VERSION "0.2"

NS_ :

BS_:

BU_: IFV_CWMP IFV_VFP External ExternalX

BO_ 259 ETSEL_common_1: 8 IFV_CWMP
 SG_ ETSEL_common_1_MessageCounter : 62|2@1+ (1,0) [0|3] ""  External
 SG_ Traffic_Direction : 47|2@1+ (1,0) [0|2] "enum"  External
 SG_ Predicted_Path_Lane_Width : 32|15@1+ (0.01,0) [0|5] "m"  External
 SG_ LROS_MVS_UpdatePulse : 16|16@1+ (1,0) [0|65535] ""  External
 SG_ LROS_FUS_UpdatePulse : 0|16@1+ (1,0) [0|65535] ""  External
 SG_ FiltVehicleSpeedOverGround : 49|13@1+ (0.01,0) [0|70] "m/s"  External

BO_ 1654 VIS_OBS_MSG_2: 8 IFV_CWMP
 SG_ VIS_OBS_CUT_IN_OUT_15 m15 : 33|3@1+ (1,0) [0|7] ""  External
 SG_ VIS_OBS_CUT_IN_OUT_14 m14 : 33|3@1+ (1,0) [0|7] ""  External
 SG_ VIS_OBS_CUT_IN_OUT_13 m13 : 33|3@1+ (1,0) [0|7] ""  External
 SG_ VIS_OBS_CUT_IN_OUT_12 m12 : 33|3@1+ (1,0) [0|7] ""  External
 SG_ VIS_OBS_CUT_IN_OUT_11 m11 : 33|3@1+ (1,0) [0|7] ""  External
 SG_ VIS_OBS_CUT_IN_OUT_10 m10 : 33|3@1+ (1,0) [0|7] ""  External
 SG_ VIS_OBS_CUT_IN_OUT_09 m9 : 33|3@1+ (1,0) [0|7] ""  External
 SG_ VIS_OBS_CUT_IN_OUT_08 m8 : 33|3@1+ (1,0) [0|7] ""  External
 SG_ VIS_OBS_CUT_IN_OUT_07 m7 : 33|3@1+ (1,0) [0|7] ""  External
 SG_ VIS_OBS_CUT_IN_OUT_06 m6 : 33|3@1+ (1,0) [0|7] ""  External
 SG_ VIS_OBS_CUT_IN_OUT_05 m5 : 33|3@1+ (1,0) [0|7] ""  External
 SG_ VIS_OBS_CUT_IN_OUT_04 m4 : 33|3@1+ (1,0) [0|7] ""  External
 SG_ VIS_OBS_CUT_IN_OUT_03 m3 : 33|3@1+ (1,0) [0|7] ""  External
 SG_ VIS_OBS_CUT_IN_OUT_02 m2 : 33|3@1+ (1,0) [0|7] ""  External
 SG_ VIS_OBS_CUT_IN_OUT_01 m1 : 33|3@1+ (1,0) [0|7] ""  External
 SG_ VIS_OBS_CIPO_15 m15 : 29|4@1+ (1,0) [0|15] ""  External
 SG_ VIS_OBS_CIPO_14 m14 : 29|4@1+ (1,0) [0|15] ""  External
 SG_ VIS_OBS_CIPO_13 m13 : 29|4@1+ (1,0) [0|15] ""  External
 SG_ VIS_OBS_CIPO_12 m12 : 29|4@1+ (1,0) [0|15] ""  External
 SG_ VIS_OBS_CIPO_11 m11 : 29|4@1+ (1,0) [0|15] ""  External
 SG_ VIS_OBS_CIPO_10 m10 : 29|4@1+ (1,0) [0|15] ""  External
 SG_ VIS_OBS_CIPO_09 m9 : 29|4@1+ (1,0) [0|15] ""  External
 SG_ VIS_OBS_CIPO_08 m8 : 29|4@1+ (1,0) [0|15] ""  External
 SG_ VIS_OBS_CIPO_07 m7 : 29|4@1+ (1,0) [0|15] ""  External
 SG_ VIS_OBS_CIPO_06 m6 : 29|4@1+ (1,0) [0|15] ""  External
 SG_ VIS_OBS_CIPO_05 m5 : 29|4@1+ (1,0) [0|15] ""  External
 SG_ VIS_OBS_CIPO_04 m4 : 29|4@1+ (1,0) [0|15] ""  External
 SG_ VIS_OBS_CIPO_03 m3 : 29|4@1+ (1,0) [0|15] ""  External
 SG_ VIS_OBS_CIPO_02 m2 : 29|4@1+ (1,0) [0|15] ""  External
 SG_ VIS_OBS_CIPO_01 m1 : 29|4@1+ (1,0) [0|15] ""  External
 SG_ VIS_OBS_TTC_CONST_ACC_MODEL_15 m15 : 19|10@1+ (0.01,0) [0|7] "s"  External
 SG_ VIS_OBS_TTC_CONST_ACC_MODEL_14 m14 : 19|10@1+ (0.01,0) [0|7] "s"  External
 SG_ VIS_OBS_TTC_CONST_ACC_MODEL_13 m13 : 19|10@1+ (0.01,0) [0|7] "s"  External
 SG_ VIS_OBS_TTC_CONST_ACC_MODEL_12 m12 : 19|10@1+ (0.01,0) [0|7] "s"  External
 SG_ VIS_OBS_TTC_CONST_ACC_MODEL_11 m11 : 19|10@1+ (0.01,0) [0|7] "s"  External
 SG_ VIS_OBS_TTC_CONST_ACC_MODEL_10 m10 : 19|10@1+ (0.01,0) [0|7] "s"  External
 SG_ VIS_OBS_TTC_CONST_ACC_MODEL_09 m9 : 19|10@1+ (0.01,0) [0|7] "s"  External
 SG_ VIS_OBS_TTC_CONST_ACC_MODEL_08 m8 : 19|10@1+ (0.01,0) [0|7] "s"  External
 SG_ VIS_OBS_TTC_CONST_ACC_MODEL_07 m7 : 19|10@1+ (0.01,0) [0|7] "s"  External
 SG_ VIS_OBS_TTC_CONST_ACC_MODEL_06 m6 : 19|10@1+ (0.01,0) [0|7] "s"  External
 SG_ VIS_OBS_TTC_CONST_ACC_MODEL_05 m5 : 19|10@1+ (0.01,0) [0|7] "s"  External
 SG_ VIS_OBS_TTC_CONST_ACC_MODEL_04 m4 : 19|10@1+ (0.01,0) [0|7] "s"  External
 SG_ VIS_OBS_TTC_CONST_ACC_MODEL_03 m3 : 19|10@1+ (0.01,0) [0|7] "s"  External
 SG_ VIS_OBS_TTC_CONST_ACC_MODEL_02 m2 : 19|10@1+ (0.01,0) [0|7] "s"  External
 SG_ VIS_OBS_TTC_CONST_ACC_MODEL_01 m1 : 19|10@1+ (0.01,0) [0|7] "s"  External
 SG_ VIS_OBS_LONG_ACCEL_15 m15 : 6|13@1+ (0.0078125,-20) [-20|20] "m/s^2"  External
 SG_ VIS_OBS_LONG_ACCEL_14 m14 : 6|13@1+ (0.0078125,-20) [-20|20] "m/s^2"  External
 SG_ VIS_OBS_LONG_ACCEL_13 m13 : 6|13@1+ (0.0078125,-20) [-20|20] "m/s^2"  External
 SG_ VIS_OBS_LONG_ACCEL_12 m12 : 6|13@1+ (0.0078125,-20) [-20|20] "m/s^2"  External
 SG_ VIS_OBS_LONG_ACCEL_11 m11 : 6|13@1+ (0.0078125,-20) [-20|20] "m/s^2"  External
 SG_ VIS_OBS_LONG_ACCEL_10 m10 : 6|13@1+ (0.0078125,-20) [-20|20] "m/s^2"  External
 SG_ VIS_OBS_LONG_ACCEL_09 m9 : 6|13@1+ (0.0078125,-20) [-20|20] "m/s^2"  External
 SG_ VIS_OBS_LONG_ACCEL_08 m8 : 6|13@1+ (0.0078125,-20) [-20|20] "m/s^2"  External
 SG_ VIS_OBS_LONG_ACCEL_07 m7 : 6|13@1+ (0.0078125,-20) [-20|20] "m/s^2"  External
 SG_ VIS_OBS_LONG_ACCEL_06 m6 : 6|13@1+ (0.0078125,-20) [-20|20] "m/s^2"  External
 SG_ VIS_OBS_LONG_ACCEL_05 m5 : 6|13@1+ (0.0078125,-20) [-20|20] "m/s^2"  External
 SG_ VIS_OBS_LONG_ACCEL_04 m4 : 6|13@1+ (0.0078125,-20) [-20|20] "m/s^2"  External
 SG_ VIS_OBS_LONG_ACCEL_03 m3 : 6|13@1+ (0.0078125,-20) [-20|20] "m/s^2"  External
 SG_ VIS_OBS_LONG_ACCEL_02 m2 : 6|13@1+ (0.0078125,-20) [-20|20] "m/s^2"  External
 SG_ VIS_OBS_LONG_ACCEL_01 m1 : 6|13@1+ (0.0078125,-20) [-20|20] "m/s^2"  External
 SG_ VIS_OBS_COUNT_MSG2 M : 2|4@1+ (1,0) [0|15] "obs"  External
 SG_ VIS_OBS_MESSAGE_COUNTER_MSG2 : 0|2@1+ (1,0) [0|3] ""  External

BO_ 1650 VFP_SYS_STATUS_MSG3: 8 IFV_CWMP
 SG_ VIS_FAILSAFE_PART_BLOCK : 36|2@1+ (1,0) [0|3] ""  External
 SG_ VIS_FAILSAFE_OUT_OF_FOCUS : 32|2@1+ (1,0) [0|3] ""  External
 SG_ VIS_FAILSAFE_OUT_OF_CALIBRATION : 34|2@1+ (1,0) [0|3] ""  External
 SG_ FUS_FAILSAFE_FUS_RAD_MISALIGNMNT : 28|2@1+ (1,0) [0|3] ""  External
 SG_ FUS_FAILSAFE_FUS_RAD_LOW_VIS : 30|2@1+ (1,0) [0|3] ""  External
 SG_ VIS_FAILSAFE_NIGHT_SPOT_RAYS : 24|2@1+ (1,0) [0|3] ""  External
 SG_ VIS_FAILSAFE_NIGHT_SMEARED_SPOTS : 26|2@1+ (1,0) [0|3] ""  External
 SG_ VIS_FAILSAFE_NIGHT_SELF_GLARE : 22|2@1+ (1,0) [0|3] ""  External
 SG_ VIS_FAILSAFE_SMEAR_IMAGE : 16|2@1+ (1,0) [0|3] ""  External
 SG_ VIS_FAILSAFE_NIGHT_FULL_BLOCK : 18|2@1+ (1,0) [0|3] ""  External
 SG_ VIS_FAILSAFE_NIGHT_FOGGY_SPOTS : 20|2@1+ (1,0) [0|3] ""  External
 SG_ VIS_FAILSAFE_NIGHT_BLUR : 14|2@1+ (1,0) [0|3] ""  External
 SG_ VIS_FAILSAFE_DAY_SUN_RAY : 12|2@1+ (1,0) [0|3] ""  External
 SG_ VIS_FAILSAFE_DAY_SPLASHES : 10|2@1+ (1,0) [0|3] ""  External
 SG_ VIS_FAILSAFE_DAY_LOW_SUN : 8|2@1+ (1,0) [0|3] ""  External
 SG_ CAN_DRIVING_SIDE : 7|1@1+ (1,0) [0|1] ""  External
 SG_ VIS_FAILSAFE_FLR_VIS_CORRELATION : 6|1@1+ (1,0) [0|1] ""  External
 SG_ VIS_FAULT_INVALID_SPEED_YAW : 5|1@1+ (1,0) [0|1] ""  External
 SG_ VIS_FAULT_IMAGER_RCC_MISALIGNED : 4|1@1+ (1,0) [0|1] ""  External
 SG_ VIS_FAILSAFE_PART_BLUR_IMAGE : 3|1@1+ (1,0) [0|1] ""  External
 SG_ VIS_FAILSAFE_PART_SOLID_BLOCKAGE : 2|1@1+ (1,0) [0|1] ""  External
 SG_ VIS_FAILSAFE_HEAVY_RAIN : 1|1@1+ (1,0) [0|1] ""  External
 SG_ VIS_FAILSAFE_ROLL_ANGLE : 0|1@1+ (1,0) [0|1] ""  External

BO_ 1710 VIS_LANE_TIMESTAMP: 8 IFV_CWMP
 SG_ VIS_LANE_TIMESTAMP : 0|32@1+ (1,0) [0|4294967295] "ms"  External

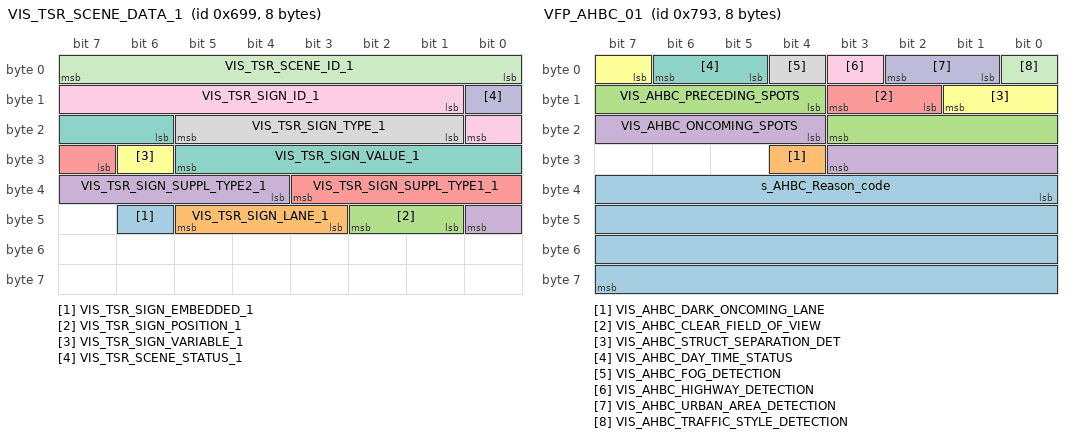
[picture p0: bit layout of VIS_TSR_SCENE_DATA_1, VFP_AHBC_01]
BO_ 1689 VIS_TSR_SCENE_DATA_1: 8 IFV_CWMP
 SG_ VIS_TSR_SIGN_EMBEDDED_1 : 46|1@1+ (1,0) [0|1] ""  External
 SG_ VIS_TSR_SIGN_LANE_1 : 43|3@1+ (1,0) [0|6] ""  External
 SG_ VIS_TSR_SIGN_POSITION_1 : 41|2@1+ (1,0) [0|2] ""  External
 SG_ VIS_TSR_SIGN_SUPPL_TYPE2_1 : 36|5@1+ (1,0) [0|24] ""  External
 SG_ VIS_TSR_SIGN_SUPPL_TYPE1_1 : 31|5@1+ (1,0) [0|24] ""  External
 SG_ VIS_TSR_SIGN_VARIABLE_1 : 30|1@1+ (1,0) [0|1] ""  External
 SG_ VIS_TSR_SIGN_VALUE_1 : 22|8@1+ (1,0) [0|255] ""  External
 SG_ VIS_TSR_SIGN_TYPE_1 : 17|5@1+ (1,0) [0|27] ""  External
 SG_ VIS_TSR_SIGN_ID_1 : 9|8@1+ (1,0) [0|255] ""  External
 SG_ VIS_TSR_SCENE_STATUS_1 : 8|1@1+ (1,0) [0|1] ""  External
 SG_ VIS_TSR_SCENE_ID_1 : 0|8@1+ (1,0) [0|255] ""  External

BO_ 1688 VIS_TSR_Environmental_Detection: 8 IFV_CWMP
 SG_ VIS_TSR_LANE_CHANGE : 6|2@1+ (1,0) [0|2] ""  External
 SG_ VIS_TSR_ROAD_CLASS : 3|3@1+ (1,0) [0|4] ""  External
 SG_ VIS_TSR_SPEED_UNIT : 1|2@1+ (1,0) [0|2] ""  External
 SG_ VIS_TSR_TRAFFIC_STYLE : 0|1@1+ (1,0) [0|1] ""  External

BO_ 1939 VFP_AHBC_01: 8 IFV_CWMP
 SG_ s_AHBC_Reason_code : 32|32@1+ (1,0) [0|4294967295] ""  External
 SG_ VIS_AHBC_DARK_ONCOMING_LANE : 28|1@1+ (1,0) [0|1] ""  External
 SG_ VIS_AHBC_PRECEDING_SPOTS : 12|8@1+ (1,0) [0|255] ""  External
 SG_ VIS_AHBC_ONCOMING_SPOTS : 20|8@1+ (1,0) [0|255] ""  External
 SG_ VIS_AHBC_CLEAR_FIELD_OF_VIEW : 10|2@1+ (1,0) [0|2] ""  External
 SG_ VIS_AHBC_STRUCT_SEPARATION_DET : 7|3@1+ (1,0) [0|4] ""  External
 SG_ VIS_AHBC_DAY_TIME_STATUS : 5|2@1+ (1,0) [0|3] ""  External
 SG_ VIS_AHBC_FOG_DETECTION : 4|1@1+ (1,0) [0|1] ""  External
 SG_ VIS_AHBC_HIGHWAY_DETECTION : 3|1@1+ (1,0) [0|1] ""  External
 SG_ VIS_AHBC_URBAN_AREA_DETECTION : 1|2@1+ (1,0) [0|2] ""  External
 SG_ VIS_AHBC_TRAFFIC_STYLE_DETECTION : 0|1@1+ (1,0) [0|1] ""  External

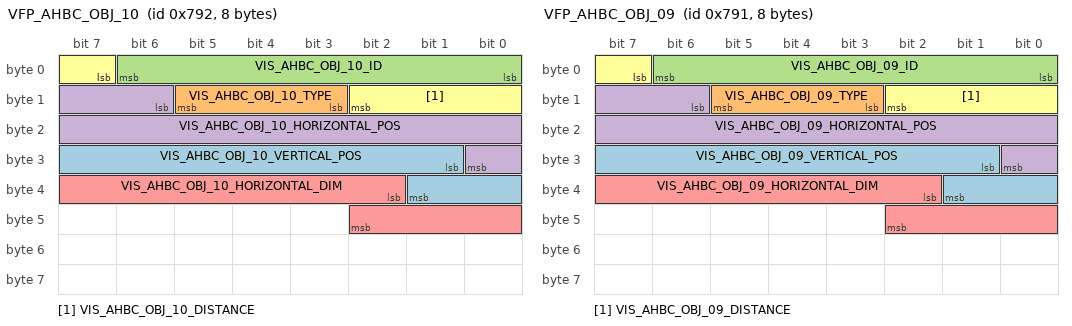
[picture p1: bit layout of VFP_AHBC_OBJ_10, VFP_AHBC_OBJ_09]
BO_ 1938 VFP_AHBC_OBJ_10: 8 IFV_CWMP
 SG_ VIS_AHBC_OBJ_10_VERTICAL_POS : 25|9@1+ (0.04,-5) [-5|5] "deg"  External
 SG_ VIS_AHBC_OBJ_10_TYPE : 11|3@1+ (1,0) [0|5] ""  External
 SG_ VIS_AHBC_OBJ_10_ID : 0|7@1+ (1,0) [0|127] ""  External
 SG_ VIS_AHBC_OBJ_10_HORIZONTAL_POS : 14|11@1+ (0.04,-24) [-24|24] "deg"  External
 SG_ VIS_AHBC_OBJ_10_HORIZONTAL_DIM : 34|9@1+ (0.04,0) [0|10] "deg"  External
 SG_ VIS_AHBC_OBJ_10_DISTANCE : 7|4@1+ (1,0) [0|15] ""  External

BO_ 1937 VFP_AHBC_OBJ_09: 8 IFV_CWMP
 SG_ VIS_AHBC_OBJ_09_VERTICAL_POS : 25|9@1+ (0.04,-5) [-5|5] "deg"  External
 SG_ VIS_AHBC_OBJ_09_TYPE : 11|3@1+ (1,0) [0|5] ""  External
 SG_ VIS_AHBC_OBJ_09_ID : 0|7@1+ (1,0) [0|127] ""  External
 SG_ VIS_AHBC_OBJ_09_HORIZONTAL_POS : 14|11@1+ (0.04,-24) [-24|24] "deg"  External
 SG_ VIS_AHBC_OBJ_09_HORIZONTAL_DIM : 34|9@1+ (0.04,0) [0|10] "deg"  External
 SG_ VIS_AHBC_OBJ_09_DISTANCE : 7|4@1+ (1,0) [0|15] ""  External

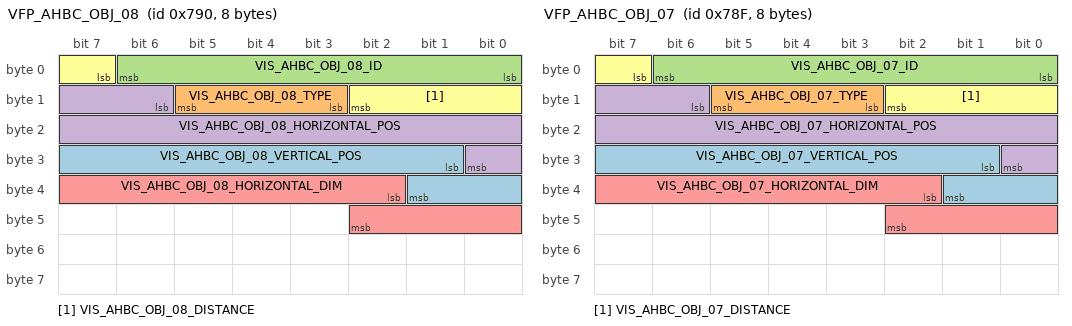
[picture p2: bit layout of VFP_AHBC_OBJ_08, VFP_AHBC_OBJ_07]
BO_ 1936 VFP_AHBC_OBJ_08: 8 IFV_CWMP
 SG_ VIS_AHBC_OBJ_08_VERTICAL_POS : 25|9@1+ (0.04,-5) [-5|5] "deg"  External
 SG_ VIS_AHBC_OBJ_08_TYPE : 11|3@1+ (1,0) [0|5] ""  External
 SG_ VIS_AHBC_OBJ_08_ID : 0|7@1+ (1,0) [0|127] ""  External
 SG_ VIS_AHBC_OBJ_08_HORIZONTAL_POS : 14|11@1+ (0.04,-24) [-24|24] "deg"  External
 SG_ VIS_AHBC_OBJ_08_HORIZONTAL_DIM : 34|9@1+ (0.04,0) [0|10] "deg"  External
 SG_ VIS_AHBC_OBJ_08_DISTANCE : 7|4@1+ (1,0) [0|15] ""  External

BO_ 1935 VFP_AHBC_OBJ_07: 8 IFV_CWMP
 SG_ VIS_AHBC_OBJ_07_VERTICAL_POS : 25|9@1+ (0.04,-5) [-5|5] "deg"  External
 SG_ VIS_AHBC_OBJ_07_TYPE : 11|3@1+ (1,0) [0|5] ""  External
 SG_ VIS_AHBC_OBJ_07_ID : 0|7@1+ (1,0) [0|127] ""  External
 SG_ VIS_AHBC_OBJ_07_HORIZONTAL_POS : 14|11@1+ (0.04,-24) [-24|24] "deg"  External
 SG_ VIS_AHBC_OBJ_07_HORIZONTAL_DIM : 34|9@1+ (0.04,0) [0|10] "deg"  External
 SG_ VIS_AHBC_OBJ_07_DISTANCE : 7|4@1+ (1,0) [0|15] ""  External

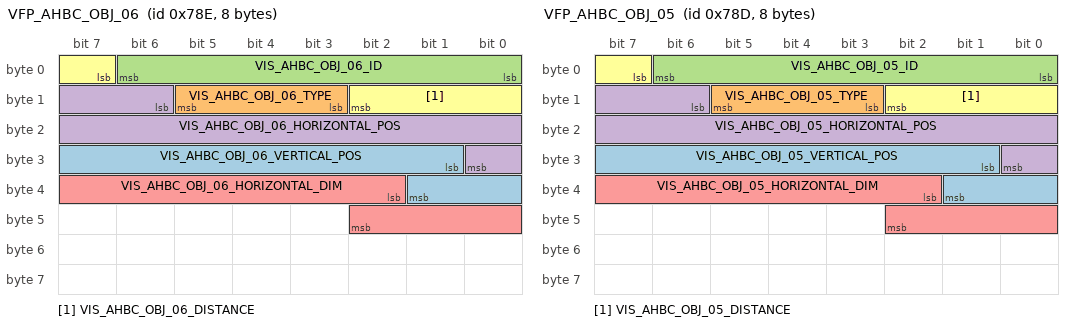
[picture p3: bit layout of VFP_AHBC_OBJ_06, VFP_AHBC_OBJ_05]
BO_ 1934 VFP_AHBC_OBJ_06: 8 IFV_CWMP
 SG_ VIS_AHBC_OBJ_06_VERTICAL_POS : 25|9@1+ (0.04,-5) [-5|5] "deg"  External
 SG_ VIS_AHBC_OBJ_06_TYPE : 11|3@1+ (1,0) [0|5] ""  External
 SG_ VIS_AHBC_OBJ_06_ID : 0|7@1+ (1,0) [0|127] ""  External
 SG_ VIS_AHBC_OBJ_06_HORIZONTAL_POS : 14|11@1+ (0.04,-24) [-24|24] "deg"  External
 SG_ VIS_AHBC_OBJ_06_HORIZONTAL_DIM : 34|9@1+ (0.04,0) [0|10] "deg"  External
 SG_ VIS_AHBC_OBJ_06_DISTANCE : 7|4@1+ (1,0) [0|15] ""  External

BO_ 1933 VFP_AHBC_OBJ_05: 8 IFV_CWMP
 SG_ VIS_AHBC_OBJ_05_VERTICAL_POS : 25|9@1+ (0.04,-5) [-5|5] "deg"  External
 SG_ VIS_AHBC_OBJ_05_TYPE : 11|3@1+ (1,0) [0|5] ""  External
 SG_ VIS_AHBC_OBJ_05_ID : 0|7@1+ (1,0) [0|127] ""  External
 SG_ VIS_AHBC_OBJ_05_HORIZONTAL_POS : 14|11@1+ (0.04,-24) [-24|24] "deg"  External
 SG_ VIS_AHBC_OBJ_05_HORIZONTAL_DIM : 34|9@1+ (0.04,0) [0|10] "deg"  External
 SG_ VIS_AHBC_OBJ_05_DISTANCE : 7|4@1+ (1,0) [0|15] ""  External

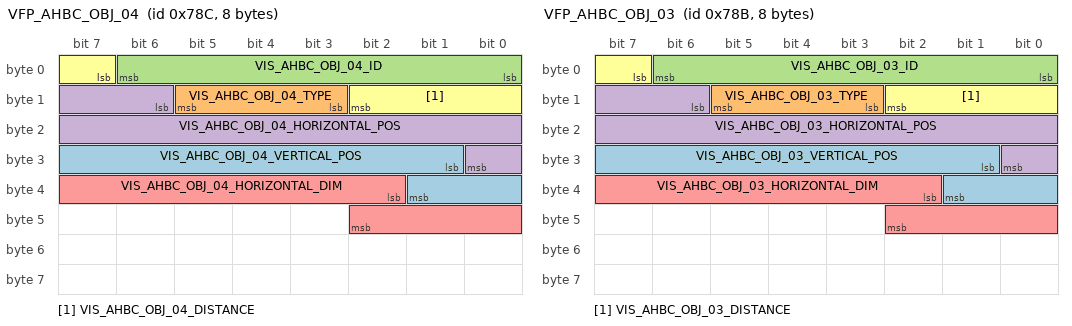
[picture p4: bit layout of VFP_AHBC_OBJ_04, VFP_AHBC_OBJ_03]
BO_ 1932 VFP_AHBC_OBJ_04: 8 IFV_CWMP
 SG_ VIS_AHBC_OBJ_04_VERTICAL_POS : 25|9@1+ (0.04,-5) [-5|5] "deg"  External
 SG_ VIS_AHBC_OBJ_04_TYPE : 11|3@1+ (1,0) [0|5] ""  External
 SG_ VIS_AHBC_OBJ_04_ID : 0|7@1+ (1,0) [0|127] ""  External
 SG_ VIS_AHBC_OBJ_04_HORIZONTAL_POS : 14|11@1+ (0.04,-24) [-24|24] "deg"  External
 SG_ VIS_AHBC_OBJ_04_HORIZONTAL_DIM : 34|9@1+ (0.04,0) [0|10] "deg"  External
 SG_ VIS_AHBC_OBJ_04_DISTANCE : 7|4@1+ (1,0) [0|15] ""  External

BO_ 1931 VFP_AHBC_OBJ_03: 8 IFV_CWMP
 SG_ VIS_AHBC_OBJ_03_VERTICAL_POS : 25|9@1+ (0.04,-5) [-5|5] "deg"  External
 SG_ VIS_AHBC_OBJ_03_TYPE : 11|3@1+ (1,0) [0|5] ""  External
 SG_ VIS_AHBC_OBJ_03_ID : 0|7@1+ (1,0) [0|127] ""  External
 SG_ VIS_AHBC_OBJ_03_HORIZONTAL_POS : 14|11@1+ (0.04,-24) [-24|24] "deg"  External
 SG_ VIS_AHBC_OBJ_03_HORIZONTAL_DIM : 34|9@1+ (0.04,0) [0|10] "deg"  External
 SG_ VIS_AHBC_OBJ_03_DISTANCE : 7|4@1+ (1,0) [0|15] ""  External

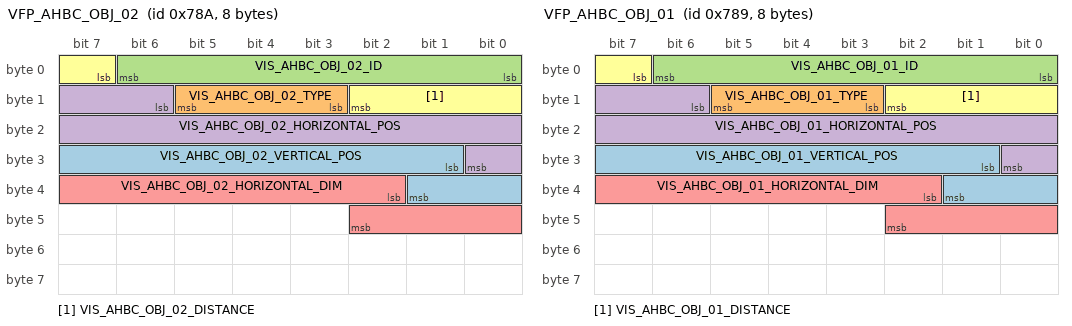
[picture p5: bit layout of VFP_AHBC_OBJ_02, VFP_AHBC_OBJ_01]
BO_ 1930 VFP_AHBC_OBJ_02: 8 IFV_CWMP
 SG_ VIS_AHBC_OBJ_02_VERTICAL_POS : 25|9@1+ (0.04,-5) [-5|5] "deg"  External
 SG_ VIS_AHBC_OBJ_02_TYPE : 11|3@1+ (1,0) [0|5] ""  External
 SG_ VIS_AHBC_OBJ_02_ID : 0|7@1+ (1,0) [0|127] ""  External
 SG_ VIS_AHBC_OBJ_02_HORIZONTAL_POS : 14|11@1+ (0.04,-24) [-24|24] "deg"  External
 SG_ VIS_AHBC_OBJ_02_HORIZONTAL_DIM : 34|9@1+ (0.04,0) [0|10] "deg"  External
 SG_ VIS_AHBC_OBJ_02_DISTANCE : 7|4@1+ (1,0) [0|15] ""  External

BO_ 1929 VFP_AHBC_OBJ_01: 8 IFV_CWMP
 SG_ VIS_AHBC_OBJ_01_VERTICAL_POS : 25|9@1+ (0.04,-5) [-5|5] "deg"  External
 SG_ VIS_AHBC_OBJ_01_TYPE : 11|3@1+ (1,0) [0|5] ""  External
 SG_ VIS_AHBC_OBJ_01_ID : 0|7@1+ (1,0) [0|127] ""  External
 SG_ VIS_AHBC_OBJ_01_HORIZONTAL_POS : 14|11@1+ (0.04,-24) [-24|24] "deg"  External
 SG_ VIS_AHBC_OBJ_01_HORIZONTAL_DIM : 34|9@1+ (0.04,0) [0|10] "deg"  External
 SG_ VIS_AHBC_OBJ_01_DISTANCE : 7|4@1+ (1,0) [0|15] ""  External

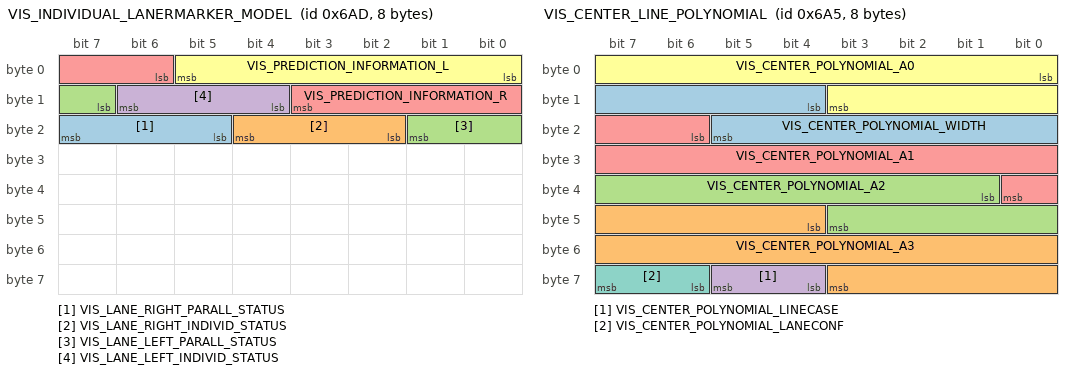
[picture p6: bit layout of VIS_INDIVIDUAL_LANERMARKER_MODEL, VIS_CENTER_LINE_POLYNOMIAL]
BO_ 1709 VIS_INDIVIDUAL_LANERMARKER_MODEL: 8 IFV_CWMP
 SG_ VIS_LANE_RIGHT_PARALL_STATUS : 21|3@1+ (1,0) [0|7] ""  External
 SG_ VIS_LANE_RIGHT_INDIVID_STATUS : 18|3@1+ (1,0) [0|7] ""  External
 SG_ VIS_LANE_LEFT_PARALL_STATUS : 15|3@1+ (1,0) [0|7] ""  External
 SG_ VIS_LANE_LEFT_INDIVID_STATUS : 12|3@1+ (1,0) [0|7] ""  External
 SG_ VIS_PREDICTION_INFORMATION_R : 6|6@1+ (1,0) [0|63] ""  External
 SG_ VIS_PREDICTION_INFORMATION_L : 0|6@1+ (1,0) [0|63] ""  External

BO_ 1701 VIS_CENTER_LINE_POLYNOMIAL: 8 IFV_CWMP
 SG_ VIS_CENTER_POLYNOMIAL_WIDTH : 12|10@1+ (0.01,0) [0|10] "m"  External
 SG_ VIS_CENTER_POLYNOMIAL_A3 : 44|16@1+ (1E-008,-0.00017) [-0.00017|0.000167] "1/m^2"  External
 SG_ VIS_CENTER_POLYNOMIAL_A2 : 33|11@1+ (1E-005,-0.01) [-0.01|0.01] "1/m"  External
 SG_ VIS_CENTER_POLYNOMIAL_LINECASE : 60|2@1+ (1,0) [0|3] ""  External
 SG_ VIS_CENTER_POLYNOMIAL_A1 : 22|11@1+ (0.0009,-0.9) [-0.9|0.9] "rad"  External
 SG_ VIS_CENTER_POLYNOMIAL_A0 : 0|12@1+ (0.01,-16) [-16|15.99] "m"  External
 SG_ VIS_CENTER_POLYNOMIAL_LANECONF : 62|2@1+ (1,0) [0|2] ""  External

BO_ 1655 VIS_OBS_MSG_3: 8 IFV_CWMP
 SG_ VIS_OBS_WIDTH_15 m15 : 6|7@1+ (0.1,0) [0|6] "m"  External
 SG_ VIS_OBS_WIDTH_14 m14 : 6|7@1+ (0.1,0) [0|6] "m"  External
 SG_ VIS_OBS_WIDTH_13 m13 : 6|7@1+ (0.1,0) [0|6] "m"  External
 SG_ VIS_OBS_WIDTH_12 m12 : 6|7@1+ (0.1,0) [0|6] "m"  External
 SG_ VIS_OBS_WIDTH_11 m11 : 6|7@1+ (0.1,0) [0|6] "m"  External
 SG_ VIS_OBS_WIDTH_10 m10 : 6|7@1+ (0.1,0) [0|6] "m"  External
 SG_ VIS_OBS_WIDTH_09 m9 : 6|7@1+ (0.1,0) [0|6] "m"  External
 SG_ VIS_OBS_WIDTH_08 m8 : 6|7@1+ (0.1,0) [0|6] "m"  External
 SG_ VIS_OBS_WIDTH_07 m7 : 6|7@1+ (0.1,0) [0|6] "m"  External
 SG_ VIS_OBS_WIDTH_06 m6 : 6|7@1+ (0.1,0) [0|12.7] "m"  External
 SG_ VIS_OBS_WIDTH_05 m5 : 6|7@1+ (0.1,0) [0|6] "m"  External
 SG_ VIS_OBS_WIDTH_04 m4 : 6|7@1+ (0.1,0) [0|6] "m"  External
 SG_ VIS_OBS_WIDTH_03 m3 : 6|7@1+ (0.1,0) [0|6] "m"  External
 SG_ VIS_OBS_WIDTH_02 m2 : 6|7@1+ (0.1,0) [0|6] "m"  External
 SG_ VIS_OBS_LONG_VEL_15 m15 : 26|12@1+ (0.0625,-128) [-128|127.9375] "m/s"  External
 SG_ VIS_OBS_LONG_VEL_14 m14 : 26|12@1+ (0.0625,-128) [-128|127.9375] "m/s"  External
 SG_ VIS_OBS_LONG_VEL_13 m13 : 26|12@1+ (0.0625,-128) [-128|127.9375] "m/s"  External
 SG_ VIS_OBS_LONG_VEL_12 m12 : 26|12@1+ (0.0625,-128) [-128|127.9375] "m/s"  External
 SG_ VIS_OBS_LONG_VEL_11 m11 : 26|12@1+ (0.0625,-128) [-128|127.9375] "m/s"  External
 SG_ VIS_OBS_LONG_VEL_10 m10 : 26|12@1+ (0.0625,-128) [-128|127.9375] "m/s"  External
 SG_ VIS_OBS_LONG_VEL_09 m9 : 26|12@1+ (0.0625,-128) [-128|127.9375] "m/s"  External
 SG_ VIS_OBS_LONG_VEL_08 m8 : 26|12@1+ (0.0625,-128) [-128|127.9375] "m/s"  External
 SG_ VIS_OBS_LONG_VEL_07 m7 : 26|12@1+ (0.0625,-128) [-128|127.9375] "m/s"  External
 SG_ VIS_OBS_LONG_VEL_06 m6 : 26|12@1+ (0.0625,-128) [-128|127.9375] "m/s"  External
 SG_ VIS_OBS_LONG_VEL_05 m5 : 26|12@1+ (0.0625,-128) [-128|127.9375] "m/s"  External
 SG_ VIS_OBS_LONG_VEL_04 m4 : 26|12@1+ (0.0625,-128) [-128|127.9375] "m/s"  External
 SG_ VIS_OBS_LONG_VEL_03 m3 : 26|12@1+ (0.0625,-128) [-128|127.9375] "m/s"  External
 SG_ VIS_OBS_LONG_VEL_02 m2 : 26|12@1+ (0.0625,-128) [-128|127.9375] "m/s"  External
 SG_ VIS_OBS_LONG_POS_15 m15 : 13|13@1+ (0.03125,0) [0|255] "m"  External
 SG_ VIS_OBS_LONG_POS_14 m14 : 13|13@1+ (0.03125,0) [0|255] "m"  External
 SG_ VIS_OBS_LONG_POS_13 m13 : 13|13@1+ (0.03125,0) [0|255] "m"  External
 SG_ VIS_OBS_LONG_POS_12 m12 : 13|13@1+ (0.03125,0) [0|255] "m"  External
 SG_ VIS_OBS_LONG_POS_11 m11 : 13|13@1+ (0.03125,0) [0|255] "m"  External
 SG_ VIS_OBS_LONG_POS_10 m10 : 13|13@1+ (0.03125,0) [0|255] "m"  External
 SG_ VIS_OBS_LONG_POS_09 m9 : 13|13@1+ (0.03125,0) [0|255] "m"  External
 SG_ VIS_OBS_LONG_POS_08 m8 : 13|13@1+ (0.03125,0) [0|255] "m"  External
 SG_ VIS_OBS_LONG_POS_07 m7 : 13|13@1+ (0.03125,0) [0|255] "m"  External
 SG_ VIS_OBS_LONG_POS_06 m6 : 13|13@1+ (0.03125,0) [0|255] "m"  External
 SG_ VIS_OBS_LONG_POS_05 m5 : 13|13@1+ (0.03125,0) [0|255] "m"  External
 SG_ VIS_OBS_LONG_POS_04 m4 : 13|13@1+ (0.03125,0) [0|255] "m"  External
 SG_ VIS_OBS_LONG_POS_03 m3 : 13|13@1+ (0.03125,0) [0|255] "m"  External
 SG_ VIS_OBS_LONG_POS_02 m2 : 13|13@1+ (0.03125,0) [0|255] "m"  External
 SG_ VIS_OBS_LAT_VEL_15 m15 : 50|12@1+ (0.0625,-128) [-128|127.9375] "m/s"  External
 SG_ VIS_OBS_LAT_VEL_14 m14 : 50|12@1+ (0.0625,-128) [-128|127.9375] "m/s"  External
 SG_ VIS_OBS_LAT_VEL_13 m13 : 50|12@1+ (0.0625,-128) [-128|127.9375] "m/s"  External
 SG_ VIS_OBS_LAT_VEL_12 m12 : 50|12@1+ (0.0625,-128) [-128|127.9375] "m/s"  External
 SG_ VIS_OBS_LAT_VEL_11 m11 : 50|12@1+ (0.0625,-128) [-128|127.9375] "m/s"  External
 SG_ VIS_OBS_LAT_VEL_10 m10 : 50|12@1+ (0.0625,-128) [-128|127.9375] "m/s"  External
 SG_ VIS_OBS_LAT_VEL_09 m9 : 50|12@1+ (0.0625,-128) [-128|127.9375] "m/s"  External
 SG_ VIS_OBS_LAT_VEL_08 m8 : 50|12@1+ (0.0625,-128) [-128|127.9375] "m/s"  External
 SG_ VIS_OBS_LAT_VEL_07 m7 : 50|12@1+ (0.0625,-128) [-128|127.9375] "m/s"  External
 SG_ VIS_OBS_LAT_VEL_06 m6 : 50|12@1+ (0.0625,-128) [-128|127.9375] "m/s"  External
 SG_ VIS_OBS_LAT_VEL_05 m5 : 50|12@1+ (0.0625,-128) [-128|127.9375] "m/s"  External
 SG_ VIS_OBS_LAT_VEL_04 m4 : 50|12@1+ (0.0625,-128) [-128|127.9375] "m/s"  External
 SG_ VIS_OBS_LAT_VEL_03 m3 : 50|12@1+ (0.0625,-128) [-128|127.9375] "m/s"  External
 SG_ VIS_OBS_LAT_VEL_02 m2 : 50|12@1+ (0.0625,-128) [-128|127.9375] "m/s"  External
 SG_ VIS_OBS_LAT_POS_15 m15 : 38|12@1+ (0.0625,-128) [-128|127.9375] "m"  External
 SG_ VIS_OBS_LAT_POS_14 m14 : 38|12@1+ (0.0625,-128) [-128|127.9375] "m"  External
 SG_ VIS_OBS_LAT_POS_13 m13 : 38|12@1+ (0.0625,-128) [-128|127.9375] "m"  External
 SG_ VIS_OBS_LAT_POS_12 m12 : 38|12@1+ (0.0625,-128) [-128|127.9375] "m"  External
 SG_ VIS_OBS_LAT_POS_11 m11 : 38|12@1+ (0.0625,-128) [-128|127.9375] "m"  External
 SG_ VIS_OBS_LAT_POS_10 m10 : 38|12@1+ (0.0625,-128) [-128|127.9375] "m"  External
 SG_ VIS_OBS_LAT_POS_09 m9 : 38|12@1+ (0.0625,-128) [-128|127.9375] "m"  External
 SG_ VIS_OBS_LAT_POS_08 m8 : 38|12@1+ (0.0625,-128) [-128|127.9375] "m"  External
 SG_ VIS_OBS_LAT_POS_07 m7 : 38|12@1+ (0.0625,-128) [-128|127.9375] "m"  External
 SG_ VIS_OBS_LAT_POS_06 m6 : 38|12@1+ (0.0625,-128) [-128|127.9375] "m"  External
 SG_ VIS_OBS_LAT_POS_05 m5 : 38|12@1+ (0.0625,-128) [-128|127.9375] "m"  External
 SG_ VIS_OBS_LAT_POS_04 m4 : 38|12@1+ (0.0625,-128) [-128|127.9375] "m"  External
 SG_ VIS_OBS_LAT_POS_03 m3 : 38|12@1+ (0.0625,-128) [-128|127.9375] "m"  External
 SG_ VIS_OBS_LAT_POS_02 m2 : 38|12@1+ (0.0625,-128) [-128|127.9375] "m"  External
 SG_ VIS_OBS_WIDTH_01 m1 : 6|7@1+ (0.1,0) [0|6] "m"  External
 SG_ VIS_OBS_MESSAGE_COUNTER_MSG3 : 0|2@1+ (1,0) [0|3] ""  External
 SG_ VIS_OBS_LONG_VEL_01 m1 : 26|12@1+ (0.0625,-128) [-128|127.9375] "m/s"  External
 SG_ VIS_OBS_LONG_POS_01 m1 : 13|13@1+ (0.03125,0) [0|255] "m"  External
 SG_ VIS_OBS_LAT_VEL_01 m1 : 50|12@1+ (0.0625,-128) [-128|127.9375] "m/s"  External
 SG_ VIS_OBS_LAT_POS_01 m1 : 38|12@1+ (0.0625,-128) [-128|127.9375] "m"  External
 SG_ VIS_OBS_COUNT_MSG3 M : 2|4@1+ (1,0) [0|15] "obs"  External

BO_ 1653 VIS_OBS_MSG_1: 8 IFV_CWMP
 SG_ VIS_OBS_TURN_INDICATOR_15 m15 : 22|2@1+ (1,0) [0|3] ""  External
 SG_ VIS_OBS_TURN_INDICATOR_14 m14 : 22|2@1+ (1,0) [0|3] ""  External
 SG_ VIS_OBS_TURN_INDICATOR_13 m13 : 22|2@1+ (1,0) [0|3] ""  External
 SG_ VIS_OBS_TURN_INDICATOR_12 m12 : 22|2@1+ (1,0) [0|3] ""  External
 SG_ VIS_OBS_TURN_INDICATOR_11 m11 : 22|2@1+ (1,0) [0|3] ""  External
 SG_ VIS_OBS_TURN_INDICATOR_10 m10 : 22|2@1+ (1,0) [0|3] ""  External
 SG_ VIS_OBS_TURN_INDICATOR_09 m9 : 22|2@1+ (1,0) [0|3] ""  External
 SG_ VIS_OBS_TURN_INDICATOR_08 m8 : 22|2@1+ (1,0) [0|3] ""  External
 SG_ VIS_OBS_TURN_INDICATOR_07 m7 : 22|2@1+ (1,0) [0|3] ""  External
 SG_ VIS_OBS_TURN_INDICATOR_06 m6 : 22|2@1+ (1,0) [0|3] ""  External
 SG_ VIS_OBS_TURN_INDICATOR_05 m5 : 22|2@1+ (1,0) [0|3] ""  External
 SG_ VIS_OBS_TURN_INDICATOR_04 m4 : 22|2@1+ (1,0) [0|3] ""  External
 SG_ VIS_OBS_TURN_INDICATOR_03 m3 : 22|2@1+ (1,0) [0|3] ""  External
 SG_ VIS_OBS_TURN_INDICATOR_02 m2 : 22|2@1+ (1,0) [0|3] ""  External
 SG_ VIS_OBS_PED_WAIST_UP_15 m15 : 19|1@1+ (1,0) [0|1] ""  External
 SG_ VIS_OBS_PED_WAIST_UP_14 m14 : 19|1@1+ (1,0) [0|1] ""  External
 SG_ VIS_OBS_PED_WAIST_UP_13 m13 : 19|1@1+ (1,0) [0|1] ""  External
 SG_ VIS_OBS_PED_WAIST_UP_12 m12 : 19|1@1+ (1,0) [0|1] ""  External
 SG_ VIS_OBS_PED_WAIST_UP_11 m11 : 19|1@1+ (1,0) [0|1] ""  External
 SG_ VIS_OBS_PED_WAIST_UP_10 m10 : 19|1@1+ (1,0) [0|1] ""  External
 SG_ VIS_OBS_PED_WAIST_UP_09 m9 : 19|1@1+ (1,0) [0|1] ""  External
 SG_ VIS_OBS_PED_WAIST_UP_08 m8 : 19|1@1+ (1,0) [0|1] ""  External
 SG_ VIS_OBS_PED_WAIST_UP_07 m7 : 19|1@1+ (1,0) [0|1] ""  External
 SG_ VIS_OBS_PED_WAIST_UP_06 m6 : 19|1@1+ (1,0) [0|1] ""  External
 SG_ VIS_OBS_PED_WAIST_UP_05 m5 : 19|1@1+ (1,0) [0|1] ""  External
 SG_ VIS_OBS_PED_WAIST_UP_04 m4 : 19|1@1+ (1,0) [0|1] ""  External
 SG_ VIS_OBS_PED_WAIST_UP_03 m3 : 19|1@1+ (1,0) [0|1] ""  External
 SG_ VIS_OBS_PED_WAIST_UP_02 m2 : 19|1@1+ (1,0) [0|1] ""  External
 SG_ VIS_OBS_ID_15 m15 : 8|4@1+ (1,0) [0|15] ""  External
 SG_ VIS_OBS_ID_14 m14 : 8|4@1+ (1,0) [0|15] ""  External
 SG_ VIS_OBS_ID_13 m13 : 8|4@1+ (1,0) [0|15] ""  External
 SG_ VIS_OBS_ID_12 m12 : 8|4@1+ (1,0) [0|15] ""  External
 SG_ VIS_OBS_ID_11 m11 : 8|4@1+ (1,0) [0|15] ""  External
 SG_ VIS_OBS_ID_10 m10 : 8|4@1+ (1,0) [0|15] ""  External
 SG_ VIS_OBS_ID_09 m9 : 8|4@1+ (1,0) [0|15] ""  External
 SG_ VIS_OBS_ID_08 m8 : 8|4@1+ (1,0) [0|15] ""  External
 SG_ VIS_OBS_ID_07 m7 : 8|4@1+ (1,0) [0|15] ""  External
 SG_ VIS_OBS_ID_06 m6 : 8|4@1+ (1,0) [0|15] ""  External
 SG_ VIS_OBS_ID_05 m5 : 8|4@1+ (1,0) [0|15] ""  External
 SG_ VIS_OBS_ID_04 m4 : 8|4@1+ (1,0) [0|15] ""  External
 SG_ VIS_OBS_ID_03 m3 : 8|4@1+ (1,0) [0|15] ""  External
 SG_ VIS_OBS_ID_02 m2 : 8|4@1+ (1,0) [0|15] ""  External
 SG_ VIS_OBS_HEIGHT_15 m15 : 58|5@1+ (0.1,0) [0|3] "m"  External
 SG_ VIS_OBS_HEIGHT_14 m14 : 58|5@1+ (0.1,0) [0|3] "m"  External
 SG_ VIS_OBS_HEIGHT_13 m13 : 58|5@1+ (0.1,0) [0|3] "m"  External
 SG_ VIS_OBS_HEIGHT_12 m12 : 58|5@1+ (0.1,0) [0|3] "m"  External
 SG_ VIS_OBS_HEIGHT_11 m11 : 58|5@1+ (0.1,0) [0|3] "m"  External
 SG_ VIS_OBS_HEIGHT_10 m10 : 58|5@1+ (0.1,0) [0|3] "m"  External
 SG_ VIS_OBS_HEIGHT_09 m9 : 58|5@1+ (0.1,0) [0|3] "m"  External
 SG_ VIS_OBS_HEIGHT_08 m8 : 58|5@1+ (0.1,0) [0|3] "m"  External
 SG_ VIS_OBS_HEIGHT_07 m7 : 58|5@1+ (0.1,0) [0|3] "m"  External
 SG_ VIS_OBS_HEIGHT_06 m6 : 58|5@1+ (0.1,0) [0|3] "m"  External
 SG_ VIS_OBS_HEIGHT_05 m5 : 58|5@1+ (0.1,0) [0|3] "m"  External
 SG_ VIS_OBS_HEIGHT_04 m4 : 58|5@1+ (0.1,0) [0|3] "m"  External
 SG_ VIS_OBS_HEIGHT_03 m3 : 58|5@1+ (0.1,0) [0|3] "m"  External
 SG_ VIS_OBS_HEIGHT_02 m2 : 58|5@1+ (0.1,0) [0|3] "m"  External
 SG_ VIS_OBS_CLASSIFICATION_15 m15 : 12|4@1+ (1,0) [0|10] ""  External
 SG_ VIS_OBS_CLASSIFICATION_14 m14 : 12|4@1+ (1,0) [0|10] ""  External
 SG_ VIS_OBS_CLASSIFICATION_13 m13 : 12|4@1+ (1,0) [0|10] ""  External
 SG_ VIS_OBS_CLASSIFICATION_12 m12 : 12|4@1+ (1,0) [0|10] ""  External
 SG_ VIS_OBS_CLASSIFICATION_11 m11 : 12|4@1+ (1,0) [0|10] ""  External
 SG_ VIS_OBS_CLASSIFICATION_10 m10 : 12|4@1+ (1,0) [0|10] ""  External
 SG_ VIS_OBS_CLASSIFICATION_09 m9 : 12|4@1+ (1,0) [0|10] ""  External
 SG_ VIS_OBS_CLASSIFICATION_08 m8 : 12|4@1+ (1,0) [0|10] ""  External
 SG_ VIS_OBS_CLASSIFICATION_07 m7 : 12|4@1+ (1,0) [0|10] ""  External
 SG_ VIS_OBS_CLASSIFICATION_06 m6 : 12|4@1+ (1,0) [0|10] ""  External
 SG_ VIS_OBS_CLASSIFICATION_05 m5 : 12|4@1+ (1,0) [0|10] ""  External
 SG_ VIS_OBS_CLASSIFICATION_04 m4 : 12|4@1+ (1,0) [0|10] ""  External
 SG_ VIS_OBS_CLASSIFICATION_03 m3 : 12|4@1+ (1,0) [0|10] ""  External
 SG_ VIS_OBS_CLASSIFICATION_02 m2 : 12|4@1+ (1,0) [0|10] ""  External
 SG_ VIS_OBS_BRAKE_LIGHT_INDIC_15 m15 : 20|2@1+ (1,0) [0|2] ""  External
 SG_ VIS_OBS_BRAKE_LIGHT_INDIC_14 m14 : 20|2@1+ (1,0) [0|2] ""  External
 SG_ VIS_OBS_BRAKE_LIGHT_INDIC_13 m13 : 20|2@1+ (1,0) [0|2] ""  External
 SG_ VIS_OBS_BRAKE_LIGHT_INDIC_12 m12 : 20|2@1+ (1,0) [0|2] ""  External
 SG_ VIS_OBS_BRAKE_LIGHT_INDIC_11 m11 : 20|2@1+ (1,0) [0|2] ""  External
 SG_ VIS_OBS_BRAKE_LIGHT_INDIC_10 m10 : 20|2@1+ (1,0) [0|2] ""  External
 SG_ VIS_OBS_BRAKE_LIGHT_INDIC_09 m9 : 20|2@1+ (1,0) [0|2] ""  External
 SG_ VIS_OBS_BRAKE_LIGHT_INDIC_08 m8 : 20|2@1+ (1,0) [0|2] ""  External
 SG_ VIS_OBS_BRAKE_LIGHT_INDIC_07 m7 : 20|2@1+ (1,0) [0|2] ""  External
 SG_ VIS_OBS_BRAKE_LIGHT_INDIC_06 m6 : 20|2@1+ (1,0) [0|2] ""  External
 SG_ VIS_OBS_BRAKE_LIGHT_INDIC_05 m5 : 20|2@1+ (1,0) [0|2] ""  External
 SG_ VIS_OBS_BRAKE_LIGHT_INDIC_04 m4 : 20|2@1+ (1,0) [0|2] ""  External
 SG_ VIS_OBS_BRAKE_LIGHT_INDIC_03 m3 : 20|2@1+ (1,0) [0|2] ""  External
 SG_ VIS_OBS_BRAKE_LIGHT_INDIC_02 m2 : 20|2@1+ (1,0) [0|2] ""  External
 SG_ VIS_OBS_TURN_INDICATOR_01 m1 : 22|2@1+ (1,0) [0|3] ""  External
 SG_ VIS_OBS_PED_WAIST_UP_01 m1 : 19|1@1+ (1,0) [0|1] ""  External
 SG_ VIS_OBS_MESSAGE_COUNTER_MSG1 : 56|2@1+ (1,0) [0|3] ""  External
 SG_ VIS_OBS_ID_01 m1 : 8|4@1+ (1,0) [0|15] ""  External
 SG_ VIS_OBS_HEIGHT_01 m1 : 58|5@1+ (0.1,0) [0|3] "m"  External
 SG_ VIS_OBS_COUNT_MSG1 M : 4|4@1+ (1,0) [0|15] "obs"  External
 SG_ VIS_OBS_CLASSIFICATION_01 m1 : 12|4@1+ (1,0) [0|10] ""  External
 SG_ VIS_OBS_BRAKE_LIGHT_INDIC_01 m1 : 20|2@1+ (1,0) [0|2] ""  External

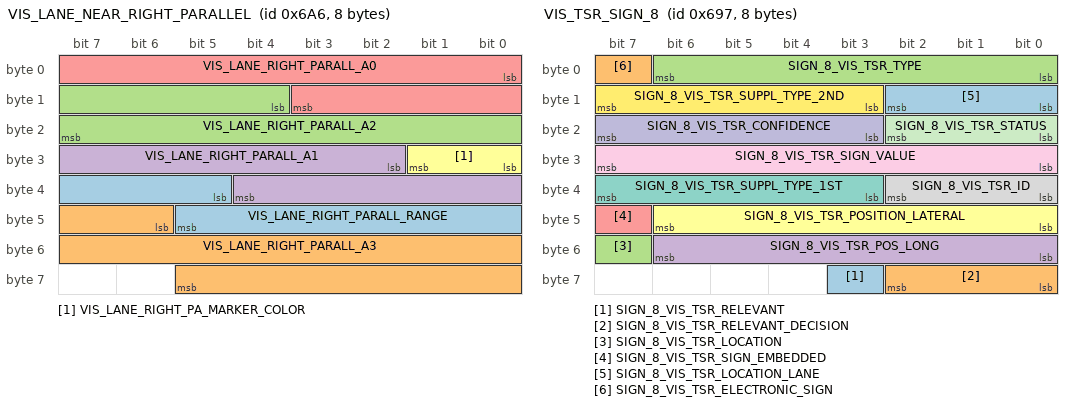
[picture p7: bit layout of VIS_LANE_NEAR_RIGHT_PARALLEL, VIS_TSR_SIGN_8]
BO_ 1702 VIS_LANE_NEAR_RIGHT_PARALLEL: 8 IFV_CWMP
 SG_ VIS_LANE_RIGHT_PARALL_RANGE : 37|9@1+ (0.25,0) [0|127.75] "m"  External
 SG_ VIS_LANE_RIGHT_PARALL_A3 : 46|16@1+ (1E-008,-0.00017) [-0.00017|0.000167] "1/m^2"  External
 SG_ VIS_LANE_RIGHT_PARALL_A2 : 12|12@1+ (5E-006,-0.01) [-0.01|0.01] "1/m"  External
 SG_ VIS_LANE_RIGHT_PARALL_A1 : 26|11@1+ (0.0009,-0.9) [-0.9|0.9] ""  External
 SG_ VIS_LANE_RIGHT_PARALL_A0 : 0|12@1+ (0.01,-16) [-16|15.99] "m"  External
 SG_ VIS_LANE_RIGHT_PA_MARKER_COLOR : 24|2@1+ (1,0) [0|3] ""  External

BO_ 1707 VIS_LANE_NEAR_RIGHT_INDIVIDUAL: 8 IFV_CWMP
 SG_ VIS_LANE_RIGHT_INDIVID_RANGE : 37|9@1+ (0.25,0) [0|127.75] "m"  External
 SG_ VIS_LANE_RIGHT_INDIVID_A3 : 46|16@1+ (1E-008,-0.00017) [-0.00017|0.000167] "1/m^2"  External
 SG_ VIS_LANE_RIGHT_INDIVID_A2 : 12|12@1+ (5E-006,-0.01) [-0.01|0.01] "1/m"  External
 SG_ VIS_LANE_RIGHT_INDIVID_A1 : 26|11@1+ (0.0009,-0.9) [-0.9|0.9] ""  External
 SG_ VIS_LANE_RIGHT_INDIVID_A0 : 0|12@1+ (0.01,-16) [-16|15.99] "m"  External
 SG_ VIS_LANE_RIGHT_IN_MARKER_COLOR : 24|2@1+ (1,0) [0|3] ""  External

BO_ 1703 VIS_LANE_NEAR_LEFT_PARALLEL: 8 IFV_CWMP
 SG_ VIS_LANE_LEFT_PARALL_RANGE : 37|9@1+ (0.25,0) [0|127.75] "m"  External
 SG_ VIS_LANE_LEFT_PARALL_A3 : 46|16@1+ (1E-008,-0.00017) [-0.00017|0.000167] "1/m^2"  External
 SG_ VIS_LANE_LEFT_PARALL_A2 : 12|12@1+ (5E-006,-0.01) [-0.01|0.01] "1/m"  External
 SG_ VIS_LANE_LEFT_PARALL_A1 : 26|11@1+ (0.0009,-0.9) [-0.9|0.9] ""  External
 SG_ VIS_LANE_LEFT_PARALL_A0 : 0|12@1+ (0.01,-16) [-16|15.99] "m"  External
 SG_ VIS_LANE_LEFT_PA_MARKER_COLOR : 24|2@1+ (1,0) [0|3] ""  External

BO_ 1708 VIS_LANE_NEAR_LEFT_INDIVIDUAL: 8 IFV_CWMP
 SG_ VIS_LANE_LEFT_INDIVID_RANGE : 37|9@1+ (0.25,0) [0|127.75] "m"  External
 SG_ VIS_LANE_LEFT_INDIVID_A3 : 46|16@1+ (1E-008,-0.00017) [-0.00017|0.000167] "1/m^2"  External
 SG_ VIS_LANE_LEFT_INDIVID_A2 : 12|12@1+ (5E-006,-0.01) [-0.01|0.01] "1/m"  External
 SG_ VIS_LANE_LEFT_INDIVID_A1 : 26|11@1+ (0.0009,-0.9) [-0.9|0.9] ""  External
 SG_ VIS_LANE_LEFT_INDIVID_A0 : 0|12@1+ (0.01,-16) [-16|15.99] "m"  External
 SG_ VIS_LANE_LEFT_IN_MARKER_COLOR : 24|2@1+ (1,0) [0|3] ""  External

BO_ 1704 VIS_LANE_NEIGHBOR_RIGHT: 8 IFV_CWMP
 SG_ VIS_LANE_NEIGHBOR_RIGHT_RANGE : 37|9@1+ (0.25,0) [0|127.75] "m"  External
 SG_ VIS_LANE_NEIGHBOR_RIGHT_A3 : 46|16@1+ (1E-008,-0.00017) [-0.00017|0.000167] "1/m^2"  External
 SG_ VIS_LANE_NEIGHBOR_RIGHT_A2 : 12|12@1+ (5E-006,-0.01) [-0.01|0.01] "1/m"  External
 SG_ VIS_LANE_NEIGHBOR_RIGHT_A1 : 26|11@1+ (0.0009,-0.9) [-0.9|0.9] ""  External
 SG_ VIS_LANE_NEIGHBOR_RIGHT_A0 : 0|12@1+ (0.01,-16) [-16|15.99] "m"  External
 SG_ VIS_LANE_NEIGHBOR_RIGHT_MARKER_COLOR : 24|2@1+ (1,0) [0|3] ""  External

BO_ 1705 VIS_LANE_NEIGHBOR_LEFT: 8 IFV_CWMP
 SG_ VIS_LANE_NEIGHBOR_LEFT_RANGE : 37|9@1+ (0.25,0) [0|127.75] "m"  External
 SG_ VIS_LANE_NEIGHBOR_LEFT_A3 : 46|16@1+ (1E-008,-0.00017) [-0.00017|0.000167] "1/m^2"  External
 SG_ VIS_LANE_NEIGHBOR_LEFT_A2 : 12|12@1+ (5E-006,-0.01) [-0.01|0.01] "1/m"  External
 SG_ VIS_LANE_NEIGHBOR_LEFT_A1 : 26|11@1+ (0.0009,-0.9) [-0.9|0.9] ""  External
 SG_ VIS_LANE_NEIGHBOR_LEFT_A0 : 0|12@1+ (0.01,-16) [-16|15.99] "m"  External
 SG_ VIS_LANE_NEIGHBOR_LEFT_MARKER_COLOR : 24|2@1+ (1,0) [0|3] ""  External

BO_ 1687 VIS_TSR_SIGN_8: 8 IFV_CWMP
 SG_ SIGN_8_VIS_TSR_RELEVANT : 59|1@1+ (1,0) [0|1] ""  External
 SG_ SIGN_8_VIS_TSR_RELEVANT_DECISION : 56|3@1+ (1,0) [0|7] ""  External
 SG_ SIGN_8_VIS_TSR_LOCATION : 55|1@1+ (1,0) [0|1] ""  External
 SG_ SIGN_8_VIS_TSR_POS_LONG : 48|7@1+ (1,0) [0|127] ""  External
 SG_ SIGN_8_VIS_TSR_SIGN_EMBEDDED : 47|1@1+ (1,0) [0|1] ""  External
 SG_ SIGN_8_VIS_TSR_POSITION_LATERAL : 40|7@1+ (1,-64) [-64|63] "m"  External
 SG_ SIGN_8_VIS_TSR_SUPPL_TYPE_1ST : 35|5@1+ (1,0) [0|24] ""  External
 SG_ SIGN_8_VIS_TSR_ID : 32|3@1+ (1,0) [0|7] ""  External
 SG_ SIGN_8_VIS_TSR_SIGN_VALUE : 24|8@1+ (1,0) [0|255] ""  External
 SG_ SIGN_8_VIS_TSR_CONFIDENCE : 19|5@1+ (0.0625,0) [0|1] ""  External
 SG_ SIGN_8_VIS_TSR_STATUS : 16|3@1+ (1,0) [0|7] ""  External
 SG_ SIGN_8_VIS_TSR_SUPPL_TYPE_2ND : 11|5@1+ (1,0) [0|24] ""  External
 SG_ SIGN_8_VIS_TSR_LOCATION_LANE : 8|3@1+ (1,-4) [-4|3] ""  External
 SG_ SIGN_8_VIS_TSR_ELECTRONIC_SIGN : 7|1@1+ (1,0) [0|1] ""  External
 SG_ SIGN_8_VIS_TSR_TYPE : 0|7@1+ (1,0) [0|127] ""  External

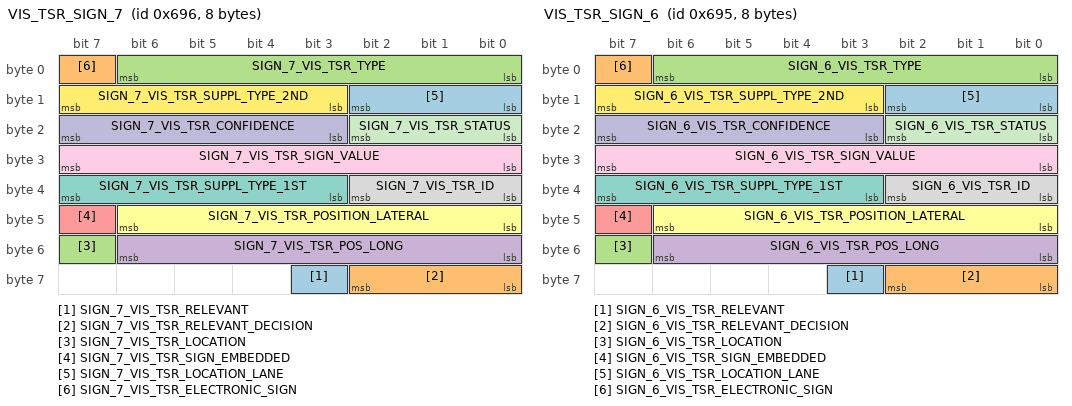
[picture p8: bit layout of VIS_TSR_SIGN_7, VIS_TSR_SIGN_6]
BO_ 1686 VIS_TSR_SIGN_7: 8 IFV_CWMP
 SG_ SIGN_7_VIS_TSR_RELEVANT : 59|1@1+ (1,0) [0|1] ""  External
 SG_ SIGN_7_VIS_TSR_RELEVANT_DECISION : 56|3@1+ (1,0) [0|7] ""  External
 SG_ SIGN_7_VIS_TSR_LOCATION : 55|1@1+ (1,0) [0|1] ""  External
 SG_ SIGN_7_VIS_TSR_POS_LONG : 48|7@1+ (1,0) [0|127] ""  External
 SG_ SIGN_7_VIS_TSR_SIGN_EMBEDDED : 47|1@1+ (1,0) [0|1] ""  External
 SG_ SIGN_7_VIS_TSR_POSITION_LATERAL : 40|7@1+ (1,-64) [-64|63] "m"  External
 SG_ SIGN_7_VIS_TSR_SUPPL_TYPE_1ST : 35|5@1+ (1,0) [0|24] ""  External
 SG_ SIGN_7_VIS_TSR_ID : 32|3@1+ (1,0) [0|7] ""  External
 SG_ SIGN_7_VIS_TSR_SIGN_VALUE : 24|8@1+ (1,0) [0|255] ""  External
 SG_ SIGN_7_VIS_TSR_CONFIDENCE : 19|5@1+ (0.0625,0) [0|1] ""  External
 SG_ SIGN_7_VIS_TSR_STATUS : 16|3@1+ (1,0) [0|7] ""  External
 SG_ SIGN_7_VIS_TSR_SUPPL_TYPE_2ND : 11|5@1+ (1,0) [0|24] ""  External
 SG_ SIGN_7_VIS_TSR_LOCATION_LANE : 8|3@1+ (1,-4) [-4|3] ""  External
 SG_ SIGN_7_VIS_TSR_ELECTRONIC_SIGN : 7|1@1+ (1,0) [0|1] ""  External
 SG_ SIGN_7_VIS_TSR_TYPE : 0|7@1+ (1,0) [0|127] ""  External

BO_ 1685 VIS_TSR_SIGN_6: 8 IFV_CWMP
 SG_ SIGN_6_VIS_TSR_RELEVANT : 59|1@1+ (1,0) [0|1] ""  External
 SG_ SIGN_6_VIS_TSR_RELEVANT_DECISION : 56|3@1+ (1,0) [0|7] ""  External
 SG_ SIGN_6_VIS_TSR_LOCATION : 55|1@1+ (1,0) [0|1] ""  External
 SG_ SIGN_6_VIS_TSR_POS_LONG : 48|7@1+ (1,0) [0|127] ""  External
 SG_ SIGN_6_VIS_TSR_SIGN_EMBEDDED : 47|1@1+ (1,0) [0|1] ""  External
 SG_ SIGN_6_VIS_TSR_POSITION_LATERAL : 40|7@1+ (1,-64) [-64|63] "m"  External
 SG_ SIGN_6_VIS_TSR_SUPPL_TYPE_1ST : 35|5@1+ (1,0) [0|24] ""  External
 SG_ SIGN_6_VIS_TSR_ID : 32|3@1+ (1,0) [0|7] ""  External
 SG_ SIGN_6_VIS_TSR_SIGN_VALUE : 24|8@1+ (1,0) [0|255] ""  External
 SG_ SIGN_6_VIS_TSR_CONFIDENCE : 19|5@1+ (0.0625,0) [0|1] ""  External
 SG_ SIGN_6_VIS_TSR_STATUS : 16|3@1+ (1,0) [0|7] ""  External
 SG_ SIGN_6_VIS_TSR_SUPPL_TYPE_2ND : 11|5@1+ (1,0) [0|24] ""  External
 SG_ SIGN_6_VIS_TSR_LOCATION_LANE : 8|3@1+ (1,-4) [-4|3] ""  External
 SG_ SIGN_6_VIS_TSR_ELECTRONIC_SIGN : 7|1@1+ (1,0) [0|1] ""  External
 SG_ SIGN_6_VIS_TSR_TYPE : 0|7@1+ (1,0) [0|127] ""  External

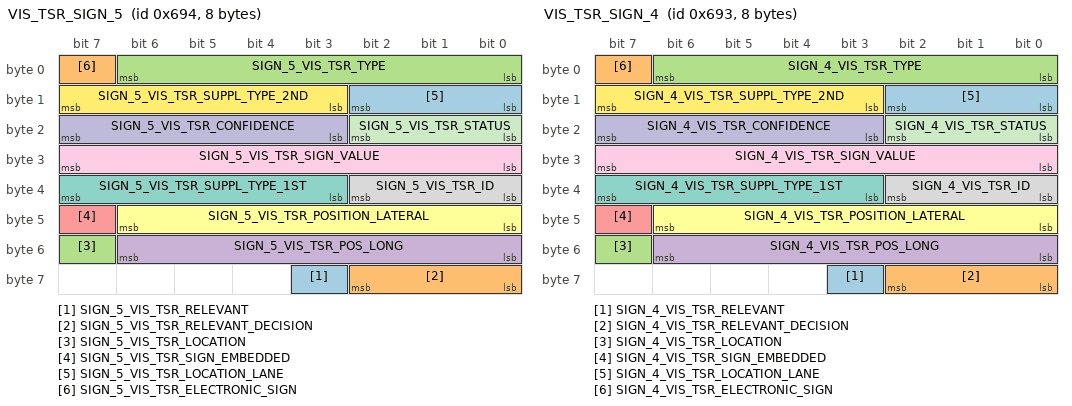
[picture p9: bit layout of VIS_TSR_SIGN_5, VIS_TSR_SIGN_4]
BO_ 1684 VIS_TSR_SIGN_5: 8 IFV_CWMP
 SG_ SIGN_5_VIS_TSR_RELEVANT : 59|1@1+ (1,0) [0|1] ""  External
 SG_ SIGN_5_VIS_TSR_RELEVANT_DECISION : 56|3@1+ (1,0) [0|7] ""  External
 SG_ SIGN_5_VIS_TSR_LOCATION : 55|1@1+ (1,0) [0|1] ""  External
 SG_ SIGN_5_VIS_TSR_POS_LONG : 48|7@1+ (1,0) [0|127] ""  External
 SG_ SIGN_5_VIS_TSR_SIGN_EMBEDDED : 47|1@1+ (1,0) [0|1] ""  External
 SG_ SIGN_5_VIS_TSR_POSITION_LATERAL : 40|7@1+ (1,-64) [-64|63] "m"  External
 SG_ SIGN_5_VIS_TSR_SUPPL_TYPE_1ST : 35|5@1+ (1,0) [0|24] ""  External
 SG_ SIGN_5_VIS_TSR_ID : 32|3@1+ (1,0) [0|7] ""  External
 SG_ SIGN_5_VIS_TSR_SIGN_VALUE : 24|8@1+ (1,0) [0|255] ""  External
 SG_ SIGN_5_VIS_TSR_CONFIDENCE : 19|5@1+ (0.0625,0) [0|1] ""  External
 SG_ SIGN_5_VIS_TSR_STATUS : 16|3@1+ (1,0) [0|7] ""  External
 SG_ SIGN_5_VIS_TSR_SUPPL_TYPE_2ND : 11|5@1+ (1,0) [0|24] ""  External
 SG_ SIGN_5_VIS_TSR_LOCATION_LANE : 8|3@1+ (1,-4) [-4|3] ""  External
 SG_ SIGN_5_VIS_TSR_ELECTRONIC_SIGN : 7|1@1+ (1,0) [0|1] ""  External
 SG_ SIGN_5_VIS_TSR_TYPE : 0|7@1+ (1,0) [0|127] ""  External

BO_ 1683 VIS_TSR_SIGN_4: 8 IFV_CWMP
 SG_ SIGN_4_VIS_TSR_RELEVANT : 59|1@1+ (1,0) [0|1] ""  External
 SG_ SIGN_4_VIS_TSR_RELEVANT_DECISION : 56|3@1+ (1,0) [0|7] ""  External
 SG_ SIGN_4_VIS_TSR_LOCATION : 55|1@1+ (1,0) [0|1] ""  External
 SG_ SIGN_4_VIS_TSR_POS_LONG : 48|7@1+ (1,0) [0|127] ""  External
 SG_ SIGN_4_VIS_TSR_SIGN_EMBEDDED : 47|1@1+ (1,0) [0|1] ""  External
 SG_ SIGN_4_VIS_TSR_POSITION_LATERAL : 40|7@1+ (1,-64) [-64|63] "m"  External
 SG_ SIGN_4_VIS_TSR_SUPPL_TYPE_1ST : 35|5@1+ (1,0) [0|24] ""  External
 SG_ SIGN_4_VIS_TSR_ID : 32|3@1+ (1,0) [0|7] ""  External
 SG_ SIGN_4_VIS_TSR_SIGN_VALUE : 24|8@1+ (1,0) [0|255] ""  External
 SG_ SIGN_4_VIS_TSR_CONFIDENCE : 19|5@1+ (0.0625,0) [0|1] ""  External
 SG_ SIGN_4_VIS_TSR_STATUS : 16|3@1+ (1,0) [0|7] ""  External
 SG_ SIGN_4_VIS_TSR_SUPPL_TYPE_2ND : 11|5@1+ (1,0) [0|24] ""  External
 SG_ SIGN_4_VIS_TSR_LOCATION_LANE : 8|3@1+ (1,-4) [-4|3] ""  External
 SG_ SIGN_4_VIS_TSR_ELECTRONIC_SIGN : 7|1@1+ (1,0) [0|1] ""  External
 SG_ SIGN_4_VIS_TSR_TYPE : 0|7@1+ (1,0) [0|127] ""  External

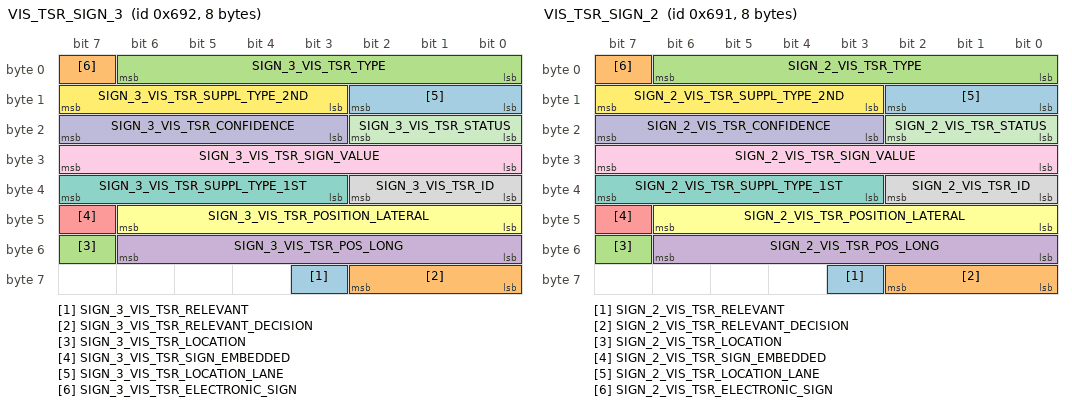
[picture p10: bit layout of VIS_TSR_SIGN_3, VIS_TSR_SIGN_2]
BO_ 1682 VIS_TSR_SIGN_3: 8 IFV_CWMP
 SG_ SIGN_3_VIS_TSR_RELEVANT : 59|1@1+ (1,0) [0|1] ""  External
 SG_ SIGN_3_VIS_TSR_RELEVANT_DECISION : 56|3@1+ (1,0) [0|7] ""  External
 SG_ SIGN_3_VIS_TSR_LOCATION : 55|1@1+ (1,0) [0|1] ""  External
 SG_ SIGN_3_VIS_TSR_POS_LONG : 48|7@1+ (1,0) [0|127] ""  External
 SG_ SIGN_3_VIS_TSR_SIGN_EMBEDDED : 47|1@1+ (1,0) [0|1] ""  External
 SG_ SIGN_3_VIS_TSR_POSITION_LATERAL : 40|7@1+ (1,-64) [-64|63] "m"  External
 SG_ SIGN_3_VIS_TSR_SUPPL_TYPE_1ST : 35|5@1+ (1,0) [0|24] ""  External
 SG_ SIGN_3_VIS_TSR_ID : 32|3@1+ (1,0) [0|7] ""  External
 SG_ SIGN_3_VIS_TSR_SIGN_VALUE : 24|8@1+ (1,0) [0|255] ""  External
 SG_ SIGN_3_VIS_TSR_CONFIDENCE : 19|5@1+ (0.0625,0) [0|1] ""  External
 SG_ SIGN_3_VIS_TSR_STATUS : 16|3@1+ (1,0) [0|7] ""  External
 SG_ SIGN_3_VIS_TSR_SUPPL_TYPE_2ND : 11|5@1+ (1,0) [0|24] ""  External
 SG_ SIGN_3_VIS_TSR_LOCATION_LANE : 8|3@1+ (1,-4) [-4|3] ""  External
 SG_ SIGN_3_VIS_TSR_ELECTRONIC_SIGN : 7|1@1+ (1,0) [0|1] ""  External
 SG_ SIGN_3_VIS_TSR_TYPE : 0|7@1+ (1,0) [0|127] ""  External

BO_ 1681 VIS_TSR_SIGN_2: 8 IFV_CWMP
 SG_ SIGN_2_VIS_TSR_RELEVANT : 59|1@1+ (1,0) [0|1] ""  External
 SG_ SIGN_2_VIS_TSR_RELEVANT_DECISION : 56|3@1+ (1,0) [0|7] ""  External
 SG_ SIGN_2_VIS_TSR_LOCATION : 55|1@1+ (1,0) [0|1] ""  External
 SG_ SIGN_2_VIS_TSR_POS_LONG : 48|7@1+ (1,0) [0|127] ""  External
 SG_ SIGN_2_VIS_TSR_SIGN_EMBEDDED : 47|1@1+ (1,0) [0|1] ""  External
 SG_ SIGN_2_VIS_TSR_POSITION_LATERAL : 40|7@1+ (1,-64) [-64|63] "m"  External
 SG_ SIGN_2_VIS_TSR_SUPPL_TYPE_1ST : 35|5@1+ (1,0) [0|24] ""  External
 SG_ SIGN_2_VIS_TSR_ID : 32|3@1+ (1,0) [0|7] ""  External
 SG_ SIGN_2_VIS_TSR_SIGN_VALUE : 24|8@1+ (1,0) [0|255] ""  External
 SG_ SIGN_2_VIS_TSR_CONFIDENCE : 19|5@1+ (0.0625,0) [0|1] ""  External
 SG_ SIGN_2_VIS_TSR_STATUS : 16|3@1+ (1,0) [0|7] ""  External
 SG_ SIGN_2_VIS_TSR_SUPPL_TYPE_2ND : 11|5@1+ (1,0) [0|24] ""  External
 SG_ SIGN_2_VIS_TSR_LOCATION_LANE : 8|3@1+ (1,-4) [-4|3] ""  External
 SG_ SIGN_2_VIS_TSR_ELECTRONIC_SIGN : 7|1@1+ (1,0) [0|1] ""  External
 SG_ SIGN_2_VIS_TSR_TYPE : 0|7@1+ (1,0) [0|127] ""  External

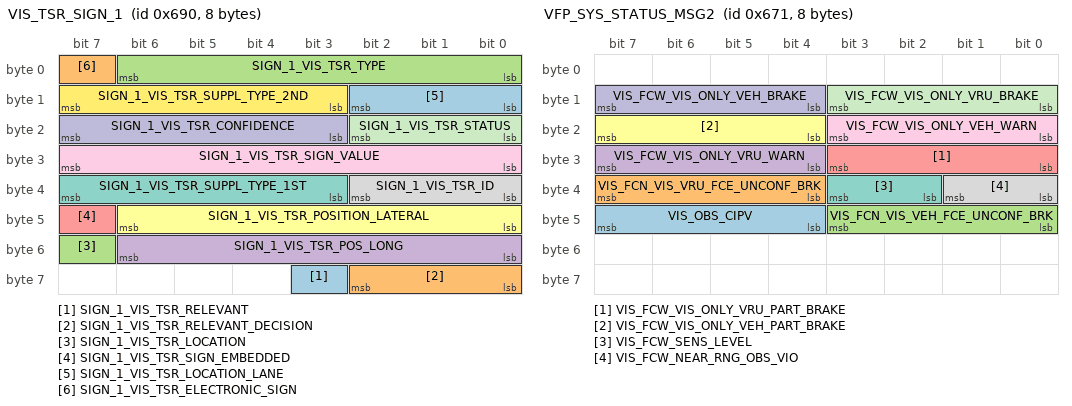
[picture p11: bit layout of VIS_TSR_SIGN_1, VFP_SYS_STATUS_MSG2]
BO_ 1680 VIS_TSR_SIGN_1: 8 IFV_CWMP
 SG_ SIGN_1_VIS_TSR_RELEVANT : 59|1@1+ (1,0) [0|1] ""  External
 SG_ SIGN_1_VIS_TSR_RELEVANT_DECISION : 56|3@1+ (1,0) [0|7] ""  External
 SG_ SIGN_1_VIS_TSR_LOCATION : 55|1@1+ (1,0) [0|0] ""  External
 SG_ SIGN_1_VIS_TSR_POS_LONG : 48|7@1+ (1,0) [0|127] ""  External
 SG_ SIGN_1_VIS_TSR_SIGN_EMBEDDED : 47|1@1+ (1,0) [0|1] ""  External
 SG_ SIGN_1_VIS_TSR_POSITION_LATERAL : 40|7@1+ (1,-64) [-64|63] "m"  External
 SG_ SIGN_1_VIS_TSR_SUPPL_TYPE_1ST : 35|5@1+ (1,0) [0|24] ""  External
 SG_ SIGN_1_VIS_TSR_ID : 32|3@1+ (1,0) [0|7] ""  External
 SG_ SIGN_1_VIS_TSR_SIGN_VALUE : 24|8@1+ (1,0) [0|255] ""  External
 SG_ SIGN_1_VIS_TSR_CONFIDENCE : 19|5@1+ (0.0625,0) [0|1] ""  External
 SG_ SIGN_1_VIS_TSR_STATUS : 16|3@1+ (1,0) [0|7] ""  External
 SG_ SIGN_1_VIS_TSR_SUPPL_TYPE_2ND : 11|5@1+ (1,0) [0|24] ""  External
 SG_ SIGN_1_VIS_TSR_LOCATION_LANE : 8|3@1+ (1,-4) [-4|3] ""  External
 SG_ SIGN_1_VIS_TSR_ELECTRONIC_SIGN : 7|1@1+ (1,0) [0|1] ""  External
 SG_ SIGN_1_VIS_TSR_TYPE : 0|7@1+ (1,0) [0|127] ""  External

BO_ 1700 VIS_LANE_INFORMATION: 8 IFV_CWMP
 SG_ VIS_LANE_PARALL_PROB : 61|1@1+ (1,0) [0|1] ""  External
 SG_ VIS_ROAD_ISTUNNEL_ENTRYEXIT : 60|1@1+ (1,0) [0|1] ""  External
 SG_ VIS_LANE_AMBIGUOUS_LANE_RIGHT : 59|1@1+ (1,0) [0|1] ""  External
 SG_ VIS_LANE_AMBIGUOUS_LANE_LEFT : 58|1@1+ (1,0) [0|1] ""  External
 SG_ VIS_LANE_LANE_CHANGE : 56|2@1+ (1,0) [0|3] ""  External
 SG_ VIS_LANE_RIGHT_INDIVID_TJACONF : 46|2@1+ (1,0) [0|2] ""  External
 SG_ VIS_LANE_RIGHT_INDIVID_LKACONF : 44|2@1+ (1,0) [0|2] ""  External
 SG_ VIS_LANE_RIGHT_INDIVID_DIMONCONF : 43|1@1+ (1,0) [0|1] ""  External
 SG_ VIS_LANE_RIGHT_PARALL_TJACONF : 38|2@1+ (1,0) [0|2] ""  External
 SG_ VIS_LANE_RIGHT_PARALL_LKACONF : 36|2@1+ (1,0) [0|2] ""  External
 SG_ VIS_LANE_RIGHT_PARALL_DIMONCONF : 35|1@1+ (1,0) [0|1] ""  External
 SG_ VIS_LANE_LEFT_INDIVID_TJACONF : 30|2@1+ (1,0) [0|2] ""  External
 SG_ VIS_LANE_LEFT_INDIVID_LKACONF : 28|2@1+ (1,0) [0|2] ""  External
 SG_ VIS_LANE_LEFT_INDIVID_DIMONCONF : 27|1@1+ (1,0) [0|1] ""  External
 SG_ VIS_LANE_LEFT_PARALL_TJACONF : 22|2@1+ (1,0) [0|2] ""  External
 SG_ VIS_LANE_LEFT_PARALL_LKACONF : 20|2@1+ (1,0) [0|2] ""  External
 SG_ VIS_LANE_LEFT_PARALL_DIMONCONF : 19|1@1+ (1,0) [0|1] ""  External
 SG_ VIS_LANE_RIGHT_PARALL_TYPE : 12|4@1+ (1,0) [0|8] ""  External
 SG_ VIS_LANE_RIGHT_INDIVID_TYPE : 8|4@1+ (1,0) [0|8] ""  External
 SG_ VIS_LANE_LEFT_PARALL_TYPE : 4|4@1+ (1,0) [0|8] ""  External
 SG_ VIS_LANE_LEFT_INDIVID_TYPE : 0|4@1+ (1,0) [0|8] ""  External

BO_ 1649 VFP_SYS_STATUS_MSG2: 8 IFV_CWMP
 SG_ VIS_OBS_CIPV : 44|4@1+ (1,0) [0|15] ""  External
 SG_ VIS_FCN_VIS_VRU_FCE_UNCONF_BRK : 36|4@1+ (1,0) [0|15] ""  External
 SG_ VIS_FCN_VIS_VEH_FCE_UNCONF_BRK : 40|4@1+ (1,0) [0|15] ""  External
 SG_ VIS_FCW_VIS_ONLY_VRU_WARN : 28|4@1+ (1,0) [0|15] ""  External
 SG_ VIS_FCW_VIS_ONLY_VRU_PART_BRAKE : 24|4@1+ (1,0) [0|15] ""  External
 SG_ VIS_FCW_VIS_ONLY_VEH_PART_BRAKE : 20|4@1+ (1,0) [0|15] ""  External
 SG_ VIS_FCW_SENS_LEVEL : 34|2@1+ (1,0) [0|2] ""  External
 SG_ VIS_FCW_NEAR_RNG_OBS_VIO : 32|2@1+ (1,0) [0|3] ""  External
 SG_ VIS_FCW_VIS_ONLY_VEH_WARN : 16|4@1+ (1,0) [0|15] ""  External
 SG_ VIS_FCW_VIS_ONLY_VEH_BRAKE : 12|4@1+ (1,0) [0|15] ""  External
 SG_ VIS_FCW_VIS_ONLY_VRU_BRAKE : 8|4@1+ (1,0) [0|15] ""  External

BO_ 1171 Pedestrian_AC: 8 IFV_CWMP
 SG_ PAC_visTrkID : 20|4@1+ (1,0) [0|15] ""  External
 SG_ PAC_Stage_age : 1|8@1+ (1,0) [0|255] ""  External
 SG_ PAC_Object_class : 16|4@1+ (1,0) [0|10] ""  External

BO_ 1155 Pedestrian_9C: 8 IFV_CWMP
 SG_ P9C_visTrkID : 20|4@1+ (1,0) [0|15] ""  External
 SG_ P9C_Stage_age : 1|8@1+ (1,0) [0|255] ""  External
 SG_ P9C_Object_class : 16|4@1+ (1,0) [0|10] ""  External

BO_ 1139 Pedestrian_8C: 8 IFV_CWMP
 SG_ P8C_visTrkID : 20|4@1+ (1,0) [0|15] ""  External
 SG_ P8C_Stage_age : 1|8@1+ (1,0) [0|255] ""  External
 SG_ P8C_Object_class : 16|4@1+ (1,0) [0|10] ""  External

BO_ 1123 Pedestrian_7C: 8 IFV_CWMP
 SG_ P7C_visTrkID : 20|4@1+ (1,0) [0|15] ""  External
 SG_ P7C_Stage_age : 1|8@1+ (1,0) [0|255] ""  External
 SG_ P7C_Object_class : 16|4@1+ (1,0) [0|10] ""  External

BO_ 1107 Pedestrian_6C: 8 IFV_CWMP
 SG_ P6C_visTrkID : 20|4@1+ (1,0) [0|15] ""  External
 SG_ P6C_Stage_age : 1|8@1+ (1,0) [0|255] ""  External
 SG_ P6C_Object_class : 16|4@1+ (1,0) [0|10] ""  External

BO_ 1091 Pedestrian_5C: 8 IFV_CWMP
 SG_ P5C_visTrkID : 20|4@1+ (1,0) [0|15] ""  External
 SG_ P5C_Stage_age : 1|8@1+ (1,0) [0|255] ""  External
 SG_ P5C_Object_class : 16|4@1+ (1,0) [0|10] ""  External

BO_ 1075 Pedestrian_4C: 8 IFV_CWMP
 SG_ P4C_visTrkID : 20|4@1+ (1,0) [0|15] ""  External
 SG_ P4C_Stage_age : 1|8@1+ (1,0) [0|255] ""  External
 SG_ P4C_Object_class : 16|4@1+ (1,0) [0|10] ""  External

BO_ 1059 Pedestrian_3C: 8 IFV_CWMP
 SG_ P3C_visTrkID : 20|4@1+ (1,0) [0|15] ""  External
 SG_ P3C_Stage_age : 1|8@1+ (1,0) [0|255] ""  External
 SG_ P3C_Object_class : 16|4@1+ (1,0) [0|10] ""  External

BO_ 1043 Pedestrian_2C: 8 IFV_CWMP
 SG_ P2C_visTrkID : 20|4@1+ (1,0) [0|15] ""  External
 SG_ P2C_Stage_age : 1|8@1+ (1,0) [0|255] ""  External
 SG_ P2C_Object_class : 16|4@1+ (1,0) [0|10] ""  External

BO_ 1170 Pedestrian_AB: 8 IFV_CWMP
 SG_ PAB_A_lat_obj : 13|11@1+ (0.01,-10) [-10|10] "m/s^2"  External
 SG_ PAB_V_lat_obj : 1|12@1+ (0.05,-20) [-20|20] "m/s"  External
 SG_ PAB_FcwConfidence : 38|3@1+ (1,0) [0|1] ""  External
 SG_ PAB_CmbbPrimaryConfidence : 35|3@1+ (1,0) [0|3] ""  External
 SG_ PAB_Status : 44|3@1+ (1,0) [0|7] ""  External
 SG_ PAB_Age : 47|8@1+ (1,0) [0|255] ""  External

BO_ 1154 Pedestrian_9B: 8 IFV_CWMP
 SG_ P9B_V_lat_obj : 1|12@1+ (0.05,-20) [-20|20] "m/s"  External
 SG_ P9B_FcwConfidence : 38|3@1+ (1,0) [0|1] ""  External
 SG_ P9B_CmbbPrimaryConfidence : 35|3@1+ (1,0) [0|3] ""  External
 SG_ P9B_Status : 44|3@1+ (1,0) [0|7] ""  External
 SG_ P9B_Age : 47|8@1+ (1,0) [0|255] ""  External
 SG_ P9B_A_lat_obj : 13|11@1+ (0.01,-10) [-10|10] "m/s^2"  External

BO_ 1138 Pedestrian_8B: 8 IFV_CWMP
 SG_ P8B_V_lat_obj : 1|12@1+ (0.05,-20) [-20|20] "m/s"  External
 SG_ P8B_FcwConfidence : 38|3@1+ (1,0) [0|1] ""  External
 SG_ P8B_CmbbPrimaryConfidence : 35|3@1+ (1,0) [0|3] ""  External
 SG_ P8B_Status : 44|3@1+ (1,0) [0|7] ""  External
 SG_ P8B_Age : 47|8@1+ (1,0) [0|255] ""  External
 SG_ P8B_A_lat_obj : 13|11@1+ (0.01,-10) [-10|10] "m/s^2"  External

BO_ 1122 Pedestrian_7B: 8 IFV_CWMP
 SG_ P7B_V_lat_obj : 1|12@1+ (0.05,-20) [-20|20] "m/s"  External
 SG_ P7B_FcwConfidence : 38|3@1+ (1,0) [0|1] ""  External
 SG_ P7B_CmbbPrimaryConfidence : 35|3@1+ (1,0) [0|3] ""  External
 SG_ P7B_Status : 44|3@1+ (1,0) [0|7] ""  External
 SG_ P7B_Age : 47|8@1+ (1,0) [0|255] ""  External
 SG_ P7B_A_lat_obj : 13|11@1+ (0.01,-10) [-10|10] "m/s^2"  External

BO_ 1106 Pedestrian_6B: 8 IFV_CWMP
 SG_ P6B_V_lat_obj : 1|12@1+ (0.05,-20) [-20|20] "m/s"  External
 SG_ P6B_FcwConfidence : 38|3@1+ (1,0) [0|1] ""  External
 SG_ P6B_CmbbPrimaryConfidence : 35|3@1+ (1,0) [0|3] ""  External
 SG_ P6B_Status : 44|3@1+ (1,0) [0|7] ""  External
 SG_ P6B_Age : 47|8@1+ (1,0) [0|255] ""  External
 SG_ P6B_A_lat_obj : 13|11@1+ (0.01,-10) [-10|10] "m/s^2"  External

BO_ 1090 Pedestrian_5B: 8 IFV_CWMP
 SG_ P5B_V_lat_obj : 1|12@1+ (0.05,-20) [-20|20] "m/s"  External
 SG_ P5B_FcwConfidence : 38|3@1+ (1,0) [0|1] ""  External
 SG_ P5B_CmbbPrimaryConfidence : 35|3@1+ (1,0) [0|3] ""  External
 SG_ P5B_Status : 44|3@1+ (1,0) [0|7] ""  External
 SG_ P5B_Age : 47|8@1+ (1,0) [0|255] ""  External
 SG_ P5B_A_lat_obj : 13|11@1+ (0.01,-10) [-10|10] "m/s^2"  External

BO_ 1074 Pedestrian_4B: 8 IFV_CWMP
 SG_ P4B_V_lat_obj : 1|12@1+ (0.05,-20) [-20|20] "m/s"  External
 SG_ P4B_FcwConfidence : 38|3@1+ (1,0) [0|1] ""  External
 SG_ P4B_CmbbPrimaryConfidence : 35|3@1+ (1,0) [0|3] ""  External
 SG_ P4B_Status : 44|3@1+ (1,0) [0|7] ""  External
 SG_ P4B_Age : 47|8@1+ (1,0) [0|255] ""  External
 SG_ P4B_A_lat_obj : 13|11@1+ (0.01,-10) [-10|10] "m/s^2"  External

BO_ 1058 Pedestrian_3B: 8 IFV_CWMP
 SG_ P3B_V_lat_obj : 1|12@1+ (0.05,-20) [-20|20] "m/s"  External
 SG_ P3B_FcwConfidence : 38|3@1+ (1,0) [0|1] ""  External
 SG_ P3B_CmbbPrimaryConfidence : 35|3@1+ (1,0) [0|3] ""  External
 SG_ P3B_Status : 44|3@1+ (1,0) [0|7] ""  External
 SG_ P3B_Age : 47|8@1+ (1,0) [0|255] ""  External
 SG_ P3B_A_lat_obj : 13|11@1+ (0.01,-10) [-10|10] "m/s^2"  External

BO_ 1042 Pedestrian_2B: 8 IFV_CWMP
 SG_ P2B_V_lat_obj : 1|12@1+ (0.05,-20) [-20|20] "m/s"  External
 SG_ P2B_FcwConfidence : 38|3@1+ (1,0) [0|1] ""  External
 SG_ P2B_CmbbPrimaryConfidence : 35|3@1+ (1,0) [0|3] ""  External
 SG_ P2B_Status : 44|3@1+ (1,0) [0|7] ""  External
 SG_ P2B_Age : 47|8@1+ (1,0) [0|255] ""  External
 SG_ P2B_A_lat_obj : 13|11@1+ (0.01,-10) [-10|10] "m/s^2"  External

BO_ 1169 Pedestrian_AA: 8 IFV_CWMP
 SG_ PAA_V_long_obj : 20|12@1+ (0.05,-100) [-100|100] "m/s"  External
 SG_ PAA_TrackID : 1|7@1+ (1,0) [0|64] ""  External
 SG_ PAA_L_long_rel : 8|12@1+ (0.05,0) [0|180] "m"  External
 SG_ PAA_L_lat_rel : 44|14@1+ (0.01,-50) [-50|50] "m"  External
 SG_ PAA_A_long_obj : 32|12@1+ (0.01,-20) [-20|20] "m/s^2"  External

BO_ 1153 Pedestrian_9A: 8 IFV_CWMP
 SG_ P9A_V_long_obj : 20|12@1+ (0.05,-100) [-100|100] "m/s"  External
 SG_ P9A_TrackID : 1|7@1+ (1,0) [0|64] ""  External
 SG_ P9A_L_long_rel : 8|12@1+ (0.05,0) [0|180] "m"  External
 SG_ P9A_L_lat_rel : 44|14@1+ (0.01,-50) [-50|50] "m"  External
 SG_ P9A_A_long_obj : 32|12@1+ (0.01,-20) [-20|20] "m/s^2"  External

BO_ 1137 Pedestrian_8A: 8 IFV_CWMP
 SG_ P8A_V_long_obj : 20|12@1+ (0.05,-100) [-100|100] "m/s"  External
 SG_ P8A_TrackID : 1|7@1+ (1,0) [0|64] ""  External
 SG_ P8A_L_long_rel : 8|12@1+ (0.05,0) [0|180] "m"  External
 SG_ P8A_L_lat_rel : 44|14@1+ (0.01,-50) [-50|50] "m"  External
 SG_ P8A_A_long_obj : 32|12@1+ (0.01,-20) [-20|20] "m/s^2"  External

BO_ 1121 Pedestrian_7A: 8 IFV_CWMP
 SG_ P7A_V_long_obj : 20|12@1+ (0.05,-100) [-100|100] "m/s"  External
 SG_ P7A_TrackID : 1|7@1+ (1,0) [0|64] ""  External
 SG_ P7A_L_long_rel : 8|12@1+ (0.05,0) [0|180] "m"  External
 SG_ P7A_L_lat_rel : 44|14@1+ (0.01,-50) [-50|50] "m"  External
 SG_ P7A_A_long_obj : 32|12@1+ (0.01,-20) [-20|20] "m/s^2"  External

BO_ 1105 Pedestrian_6A: 8 IFV_CWMP
 SG_ P6A_L_lat_rel : 44|14@1+ (0.01,-50) [-50|50] "m"  External
 SG_ P6A_A_long_obj : 32|12@1+ (0.01,-20) [-20|20] "m/s^2"  External
 SG_ P6A_V_long_obj : 20|12@1+ (0.05,-100) [-100|100] "m/s"  External
 SG_ P6A_L_long_rel : 8|12@1+ (0.05,0) [0|180] "m"  External
 SG_ P6A_TrackID : 1|7@1+ (1,0) [0|64] ""  External

BO_ 1089 Pedestrian_5A: 8 IFV_CWMP
 SG_ P5A_L_lat_rel : 44|14@1+ (0.01,-50) [-50|50] "m"  External
 SG_ P5A_A_long_obj : 32|12@1+ (0.01,-20) [-20|20] "m/s^2"  External
 SG_ P5A_V_long_obj : 20|12@1+ (0.05,-100) [-100|100] "m/s"  External
 SG_ P5A_L_long_rel : 8|12@1+ (0.05,0) [0|180] "m"  External
 SG_ P5A_TrackID : 1|7@1+ (1,0) [0|64] ""  External

BO_ 1073 Pedestrian_4A: 8 IFV_CWMP
 SG_ P4A_L_lat_rel : 44|14@1+ (0.01,-50) [-50|50] "m"  External
 SG_ P4A_A_long_obj : 32|12@1+ (0.01,-20) [-20|20] "m/s^2"  External
 SG_ P4A_V_long_obj : 20|12@1+ (0.05,-100) [-100|100] "m/s"  External
 SG_ P4A_L_long_rel : 8|12@1+ (0.05,0) [0|180] "m"  External
 SG_ P4A_TrackID : 1|7@1+ (1,0) [0|64] ""  External

BO_ 1057 Pedestrian_3A: 8 IFV_CWMP
 SG_ P3A_L_lat_rel : 44|14@1+ (0.01,-50) [-50|50] "m"  External
 SG_ P3A_A_long_obj : 32|12@1+ (0.01,-20) [-20|20] "m/s^2"  External
 SG_ P3A_V_long_obj : 20|12@1+ (0.05,-100) [-100|100] "m/s"  External
 SG_ P3A_L_long_rel : 8|12@1+ (0.05,0) [0|180] "m"  External
 SG_ P3A_TrackID : 1|7@1+ (1,0) [0|64] ""  External

BO_ 1041 Pedestrian_2A: 8 IFV_CWMP
 SG_ P2A_L_lat_rel : 44|14@1+ (0.01,-50) [-50|50] "m"  External
 SG_ P2A_V_long_obj : 20|12@1+ (0.05,-100) [-100|100] "m/s"  External
 SG_ P2A_A_long_obj : 32|12@1+ (0.01,-20) [-20|20] "m/s^2"  External
 SG_ P2A_L_long_rel : 8|12@1+ (0.05,0) [0|180] "m"  External
 SG_ P2A_TrackID : 1|7@1+ (1,0) [0|64] ""  External

BO_ 1026 Pedestrian_1B: 8 IFV_CWMP
 SG_ P1B_Age : 47|8@1+ (1,0) [0|255] ""  External
 SG_ P1B_V_lat_obj : 1|12@1+ (0.05,-20) [-20|20] "m/s"  External
 SG_ P1B_FcwConfidence : 38|3@1+ (1,0) [0|1] ""  External
 SG_ P1B_CmbbPrimaryConfidence : 35|3@1+ (1,0) [0|3] ""  External
 SG_ P1B_Status : 44|3@1+ (1,0) [0|7] ""  External
 SG_ P1B_A_lat_obj : 13|11@1+ (0.01,-10) [-10|10] "m/s^2"  External

BO_ 1958 LKA_Diag_status: 8 IFV_CWMP
 SG_ ldp_Veh_status_check : 0|1@1+ (1,0) [0|1] ""  External
 SG_ LKA_Handcode_diag_RC_Mask : 21|23@1- (1,0) [0|8388607] ""  External
 SG_ Handcode_Diag_Validity_mask : 44|20@1- (1,0) [0|1048575] ""  External
 SG_ LKA_Feature_diag_mask : 2|19@1- (1,0) [-262144|262143] ""  External
 SG_ LKA_Feature_diag : 1|1@1+ (1,0) [0|1] ""  External

BO_ 1957 LDP_debug_A: 7 IFV_CWMP
 SG_ ldp_f_left_driver_suppression : 4|1@1+ (1,0) [0|1] ""  External
 SG_ ldp_torq_req_from_right_w_PI : 48|8@1- (0.05,0) [-6.4|6.35] ""  External
 SG_ ldp_torq_req_from_left_w_PI : 40|8@1- (0.05,0) [-6.4|6.35] ""  External
 SG_ ldp_i_term_init_flags : 24|8@1+ (1,0) [0|255] ""  External
 SG_ ldp_i_term_freeze_flags : 32|8@1+ (1,0) [0|255] ""  External
 SG_ ldp_i_term : 16|8@1- (0.025,0) [-3.2|3.175] ""  External
 SG_ ldp_f_hands_off_warning : 7|1@1+ (1,0) [0|1] ""  External
 SG_ ldp_right_lane_change : 15|1@1+ (1,0) [0|1] ""  External
 SG_ ldp_left_lane_change : 14|1@1+ (1,0) [0|1] ""  External
 SG_ ldp_road_state : 5|1@1+ (1,0) [0|1] ""  External
 SG_ ldp_f_right_curve : 13|1@1+ (1,0) [0|1] ""  External
 SG_ ldp_f_left_curve : 12|1@1+ (1,0) [0|1] ""  External
 SG_ ldp_valid_MM_lane_width : 11|1@1+ (1,0) [0|1] ""  External
 SG_ ldp_valid_MM_curvature : 10|1@1+ (1,0) [0|1] ""  External
 SG_ ldp_MM_turn_signal : 8|2@1+ (1,0) [0|3] ""  External
 SG_ ldp_f_right_driver_suppression : 3|1@1+ (1,0) [0|1] ""  External
 SG_ ldp_SysStatusInfo : 0|3@1+ (1,0) [0|7] "enum"  External

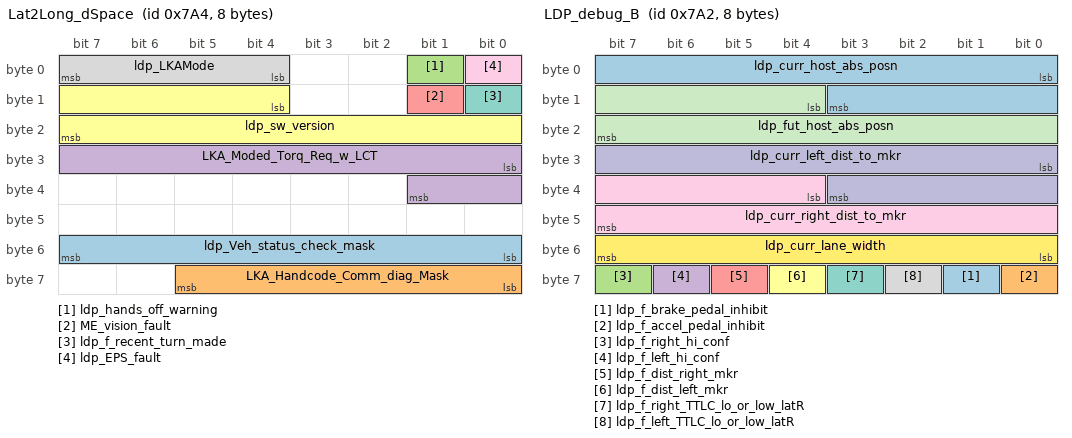
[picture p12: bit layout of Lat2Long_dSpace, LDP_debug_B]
BO_ 1956 Lat2Long_dSpace: 8 IFV_CWMP
 SG_ ldp_Veh_status_check_mask : 48|8@1- (1,0) [0|255] ""  External
 SG_ LKA_Handcode_Comm_diag_Mask : 56|6@1- (1,0) [0|63] ""  External
 SG_ ldp_hands_off_warning : 1|1@1+ (1,0) [0|1] ""  External
 SG_ LKA_Moded_Torq_Req_w_LCT : 24|10@1- (0.01,0) [-5.12|5.11] "Nm"  External
 SG_ ME_vision_fault : 9|1@1- (1,0) [0|1] ""  External
 SG_ ldp_sw_version : 12|12@1+ (0.001,0) [0|4.095] ""  External
 SG_ ldp_f_recent_turn_made : 8|1@1+ (1,0) [0|1] ""  External
 SG_ ldp_LKAMode : 4|4@1+ (1,0) [0|8] ""  External
 SG_ ldp_EPS_fault : 0|1@1+ (1,0) [0|1] ""  External

BO_ 1955 LDP_Controller: 8 IFV_CWMP
 SG_ ldp_spd_based_torq_limit : 0|8@1+ (0.02,0) [0|5.1] ""  External
 SG_ ldp_right_P_term : 8|8@1- (0.02,0) [-2.56|2.54] ""  External
 SG_ ldp_left_P_term : 16|8@1- (0.02,0) [-2.56|2.54] ""  External
 SG_ ldp_torq_req_from_right_raw : 44|10@1- (0.01,0) [-5.12|5.11] "Nm"  External
 SG_ ldp_torq_req_from_left_raw : 54|10@1- (0.01,0) [-5.12|5.11] "Nm"  External
 SG_ ldp_torq_req_from_right_mag_lim : 24|10@1- (0.01,0) [-5.12|5.11] "Nm"  External
 SG_ ldp_torq_req_from_left_mag_lim : 34|10@1- (0.01,0) [-5.12|5.11] "Nm"  External

BO_ 1954 LDP_debug_B: 8 IFV_CWMP
 SG_ ldp_f_brake_pedal_inhibit : 57|1@1+ (1,0) [0|1] ""  External
 SG_ ldp_f_accel_pedal_inhibit : 56|1@1+ (1,0) [0|1] ""  External
 SG_ ldp_f_right_hi_conf : 63|1@1+ (1,0) [0|1] ""  External
 SG_ ldp_f_left_hi_conf : 62|1@1+ (1,0) [0|1] ""  External
 SG_ ldp_f_dist_right_mkr : 61|1@1+ (1,0) [0|1] ""  External
 SG_ ldp_f_dist_left_mkr : 60|1@1+ (1,0) [0|1] ""  External
 SG_ ldp_f_right_TTLC_lo_or_low_latR : 59|1@1+ (1,0) [0|1] ""  External
 SG_ ldp_f_left_TTLC_lo_or_low_latR : 58|1@1+ (1,0) [0|1] ""  External
 SG_ ldp_curr_right_dist_to_mkr : 36|12@1- (0.01,0) [-20.48|20.47] "m"  External
 SG_ ldp_curr_left_dist_to_mkr : 24|12@1- (0.01,0) [-20.48|20.47] "m"  External
 SG_ ldp_fut_host_abs_posn : 12|12@1- (0.01,0) [-20.48|20.47] "m"  External
 SG_ ldp_curr_lane_width : 48|8@1+ (0.05,0) [0|12.75] "m"  External
 SG_ ldp_curr_host_abs_posn : 0|12@1- (0.01,0) [-20.48|20.47] "m"  External

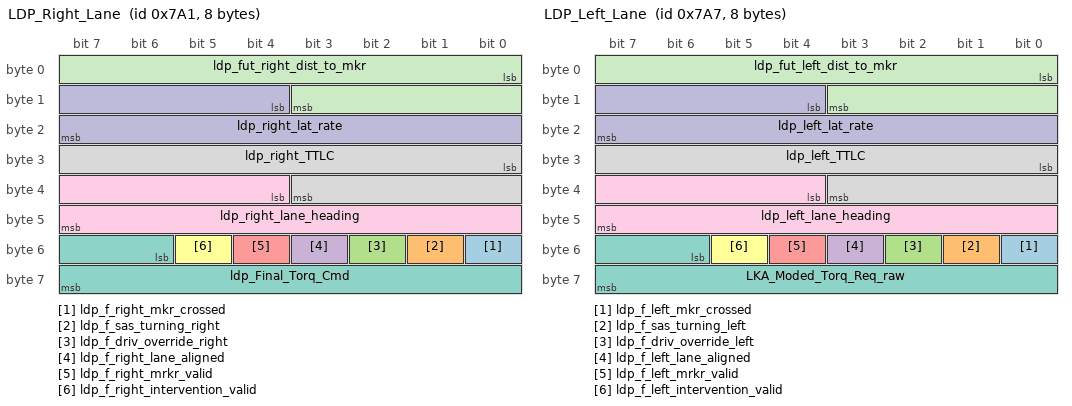
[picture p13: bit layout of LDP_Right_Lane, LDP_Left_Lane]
BO_ 1953 LDP_Right_Lane: 8 IFV_CWMP
 SG_ ldp_f_right_mkr_crossed : 48|1@1+ (1,0) [0|1] ""  External
 SG_ ldp_f_sas_turning_right : 49|1@1+ (1,0) [0|1] ""  External
 SG_ ldp_f_driv_override_right : 50|1@1+ (1,0) [0|1] ""  External
 SG_ ldp_f_right_lane_aligned : 51|1@1+ (1,0) [0|1] ""  External
 SG_ ldp_f_right_mrkr_valid : 52|1@1+ (1,0) [0|1] ""  External
 SG_ ldp_f_right_intervention_valid : 53|1@1+ (1,0) [0|1] ""  External
 SG_ ldp_Final_Torq_Cmd : 54|10@1- (0.01,0) [-5.12|5.11] "Nm"  External
 SG_ ldp_right_TTLC : 24|12@1- (0.005,0) [-10.24|10.235] "sec"  External
 SG_ ldp_right_lane_heading : 36|12@1- (0.0025,0) [-5.12|5.1175] "deg"  External
 SG_ ldp_right_lat_rate : 12|12@1- (0.01,0) [-20.48|20.47] "m/s"  External
 SG_ ldp_fut_right_dist_to_mkr : 0|12@1- (0.005,0) [-10.24|10.235] "m"  External

BO_ 1959 LDP_Left_Lane: 8 IFV_CWMP
 SG_ ldp_f_left_mkr_crossed : 48|1@1+ (1,0) [0|1] ""  External
 SG_ ldp_f_sas_turning_left : 49|1@1+ (1,0) [0|1] ""  External
 SG_ ldp_f_driv_override_left : 50|1@1+ (1,0) [0|1] ""  External
 SG_ ldp_f_left_lane_aligned : 51|1@1+ (1,0) [0|1] ""  External
 SG_ ldp_f_left_mrkr_valid : 52|1@1+ (1,0) [0|1] ""  External
 SG_ ldp_f_left_intervention_valid : 53|1@1+ (1,0) [0|1] ""  External
 SG_ LKA_Moded_Torq_Req_raw : 54|10@1- (0.01,0) [-5.12|5.11] "Nm"  External
 SG_ ldp_left_TTLC : 24|12@1- (0.005,0) [-10.24|10.235] "sec"  External
 SG_ ldp_left_lane_heading : 36|12@1- (0.0025,0) [-5.12|5.1175] "deg"  External
 SG_ ldp_left_lat_rate : 12|12@1- (0.01,0) [-20.48|20.47] "m/s"  External
 SG_ ldp_fut_left_dist_to_mkr : 0|12@1- (0.005,0) [-10.24|10.235] "m"  External

BO_ 1988 CIB_Inhibits_5_4: 8 IFV_CWMP
 SG_ CIB_Inhibit_5_Flags : 7|32@0+ (1,0) [0|0] "Bit Mapped"  External
 SG_ CIB_Inhibit_4_Flags : 39|32@0+ (1,0) [0|0] "Bit Mapped"  External

BO_ 1987 CIB_Inhibits_3_2: 8 IFV_CWMP
 SG_ CIB_Inhibit_2_Flags : 39|32@0+ (1,0) [0|0] "Bit Mapped"  External
 SG_ CIB_Inhibit_3_Flags : 7|32@0+ (1,0) [0|0] "Bit Mapped"  External

BO_ 1986 CIB_Inhibits_1_0: 8 IFV_CWMP
 SG_ CIB_Inhibit_0_Flags : 39|32@0+ (1,0) [0|0] "Bit Mapped"  External
 SG_ CIB_Inhibit_1_Flags : 7|32@0+ (1,0) [0|0] "Bit Mapped"  External

BO_ 1994 FCW_Inhibits_5_4: 8 IFV_CWMP
 SG_ FCW_Inhibit_5_Flags : 7|32@0+ (1,0) [0|0] "Bit Mapped"  External
 SG_ FCW_Inhibit_4_Flags : 39|32@0+ (1,0) [0|0] "Bit Mapped"  External

BO_ 1993 FCW_Inhibits_3_2: 8 IFV_CWMP
 SG_ FCW_Inhibit_2_Flags : 39|32@0+ (1,0) [0|0] "Bit Mapped"  External
 SG_ FCW_Inhibit_3_Flags : 7|32@0+ (1,0) [0|0] "Bit Mapped"  External

BO_ 1992 FCW_Inhibits_1_0: 8 IFV_CWMP
 SG_ FCW_Inhibit_1_Flags : 7|32@0+ (1,0) [0|0] "Bit Mapped"  External
 SG_ FCW_Inhibit_0_Flags : 39|32@0+ (1,0) [0|0] "Bit Mapped"  External

BO_ 1973 ACC_Dev_Diseng_5_4: 8 IFV_CWMP
 SG_ Disengage_ACC_5_Flags : 7|32@0+ (1,0) [0|0] "Bit Mapped"  External
 SG_ Disengage_ACC_4_Flags : 39|32@0+ (1,0) [0|0] "Bit Mapped"  ExternalX

BO_ 1972 ACC_Dev_Diseng_3_2: 8 IFV_CWMP
 SG_ Disengage_ACC_2_Flags : 39|32@0+ (1,0) [0|0] "Bit Mapped"  External
 SG_ Disengage_ACC_3_Flags : 7|32@0+ (1,0) [0|0] "Bit Mapped"  External

BO_ 1971 ACC_Dev_Diseng_1_0: 8 IFV_CWMP
 SG_ Disengage_ACC_0_Flags : 39|32@0+ (1,0) [0|0] "Bit Mapped"  External
 SG_ Disengage_ACC_1_Flags : 7|32@0+ (1,0) [0|0] "Bit Mapped"  External

BO_ 1970 ACC_Dev_Inh_5_4: 8 IFV_CWMP
 SG_ Inhibit_ACC_4_Flags : 39|32@0+ (1,0) [0|0] "Bit Mapped"  External
 SG_ Inhibit_ACC_5_Flags : 7|32@0+ (1,0) [0|0] "Bit Mapped"  External

BO_ 1969 ACC_Dev_Inh_3_2: 8 IFV_CWMP
 SG_ Inhibit_ACC_2_Flags : 39|32@0+ (1,0) [0|0] "Bit Mapped"  External
 SG_ Inhibit_ACC_3_Flags : 7|32@0+ (1,0) [0|0] "Bit Mapped"  External

BO_ 1968 ACC_Dev_Inh_1_0: 8 IFV_CWMP
 SG_ Inhibit_ACC_0_Flags : 39|32@0+ (1,0) [0|0] "Bit Mapped"  External
 SG_ Inhibit_ACC_1_Flags : 7|32@0+ (1,0) [0|0] "Bit Mapped"  External

BO_ 1974 ACC_Dev_Adjust_Outer_Funnel: 8 IFV_CWMP
 SG_ IMULongAccelFilt_mpss : 29|8@0- (0.0625,0) [-8|7.9375] "mpss"  External
 SG_ dropped_target_timer : 37|15@0+ (1,0) [0|32767] ""  External
 SG_ HostLongAccelFilt_mpss : 21|8@0- (0.0625,0) [-8|7.9375] "mpss"  External
 SG_ hold_accel_in_curve_time : 54|15@0+ (1,0) [0|32767] "sec"  External
 SG_ Estimated_Radius_Curvature : 7|14@0- (1,0) [-8192|8191] "m"  External
 SG_ Outer_Funnel_State : 9|4@0+ (1,0) [0|8] "Enum"  External

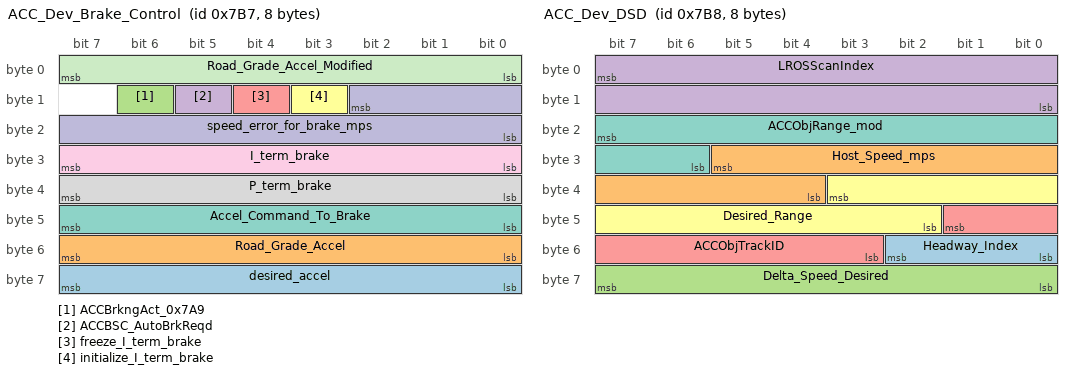
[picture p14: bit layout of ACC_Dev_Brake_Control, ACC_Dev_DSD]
BO_ 1975 ACC_Dev_Brake_Control: 8 IFV_CWMP
 SG_ desired_accel : 63|8@0- (0.0625,0) [-8|7.9375] "mpss"  External
 SG_ Road_Grade_Accel : 55|8@0- (0.0625,0) [-8|7.9375] "mpss"  External
 SG_ ACCBrkngAct_0x7A9 : 14|1@0+ (1,0) [0|0] ""  External
 SG_ ACCBSC_AutoBrkReqd : 13|1@0+ (1,0) [0|0] ""  External
 SG_ freeze_I_term_brake : 12|1@0+ (1,0) [0|0] ""  External
 SG_ initialize_I_term_brake : 11|1@0+ (1,0) [0|0] ""  External
 SG_ Accel_Command_To_Brake : 47|8@0- (0.0625,0) [-8|7.9375] "mpss"  External
 SG_ P_term_brake : 39|8@0- (0.0625,0) [-8|7.9375] "mpss"  External
 SG_ I_term_brake : 31|8@0- (0.0625,0) [-8|7.9375] "mpss"  External
 SG_ speed_error_for_brake_mps : 10|11@0- (0.0625,0) [-64|63.9375] "mps"  External
 SG_ Road_Grade_Accel_Modified : 7|8@0- (0.0625,0) [-8|7.9375] "mpss"  External

BO_ 1976 ACC_Dev_DSD: 8 IFV_CWMP
 SG_ Headway_Index : 50|3@0+ (1,0) [0|7] "table index"  External
 SG_ Host_Speed_mps : 29|10@0+ (0.0625,0) [0|63.9375] "m/sec"  External
 SG_ Delta_Speed_Desired : 63|8@0- (0.0625,0) [-8|7.9375] "m/sec^2"  External
 SG_ LROSScanIndex : 7|16@0+ (1,0) [0|65535] "Counts"  External
 SG_ ACCObjTrackID : 41|7@0+ (1,0) [0|127] "Counts"  External
 SG_ Desired_Range : 35|10@0+ (0.25,0) [0|255.75] "Meters"  External
 SG_ ACCObjRange_mod : 23|10@0+ (0.25,0) [0|255.75] "Meters"  External

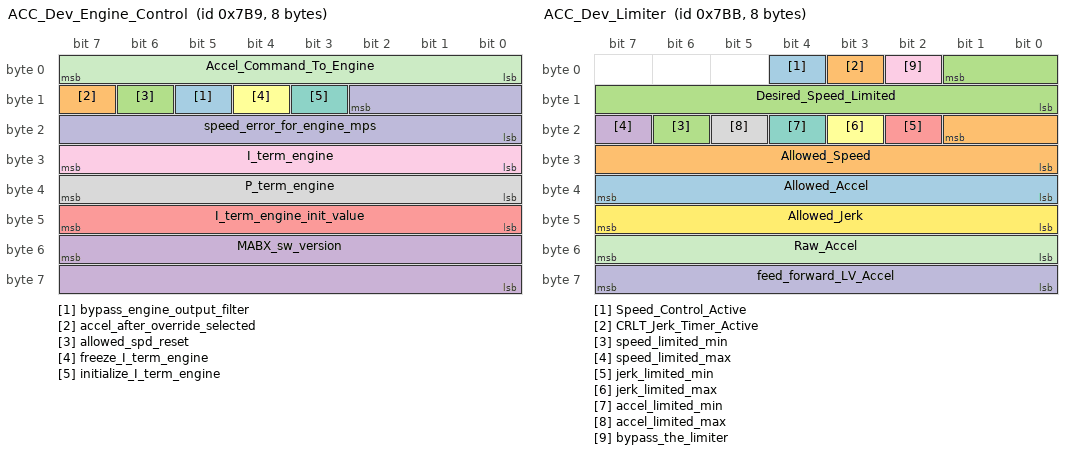
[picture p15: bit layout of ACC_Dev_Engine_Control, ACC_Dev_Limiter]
BO_ 1977 ACC_Dev_Engine_Control: 8 IFV_CWMP
 SG_ bypass_engine_output_filter : 13|1@0+ (1,0) [0|0] ""  External
 SG_ accel_after_override_selected : 15|1@0+ (1,0) [0|1] "Boolean"  External
 SG_ allowed_spd_reset : 14|1@0+ (1,0) [0|1] "Boolean"  External
 SG_ MABX_sw_version : 55|16@0+ (0.001,0) [0|65.535] ""  External
 SG_ I_term_engine_init_value : 47|8@0- (0.0625,0) [-8|7.9375] "mpss"  External
 SG_ freeze_I_term_engine : 12|1@0+ (1,0) [0|0] ""  External
 SG_ initialize_I_term_engine : 11|1@0+ (1,0) [0|0] ""  External
 SG_ P_term_engine : 39|8@0- (0.0625,0) [-8|7.9375] "mpss"  External
 SG_ I_term_engine : 31|8@0- (0.0625,0) [-8|7.9375] "mpss"  External
 SG_ speed_error_for_engine_mps : 10|11@0- (0.0625,0) [-64|63.9375] "mps"  External
 SG_ Accel_Command_To_Engine : 7|8@0- (0.0625,0) [-8|7.9375] "mpss"  External

BO_ 1978 ACC_Dev_Engine_Control_2: 8 IFV_CWMP
 SG_ freeze_engine_integrator_flags : 7|32@0+ (1,0) [0|0] "Bit Mapped"  External

BO_ 1979 ACC_Dev_Limiter: 8 IFV_CWMP
 SG_ Speed_Control_Active : 4|1@0+ (1,0) [0|1] ""  External
 SG_ CRLT_Jerk_Timer_Active : 3|1@0+ (1,0) [0|1] ""  External
 SG_ speed_limited_min : 22|1@0+ (1,0) [0|0] ""  External
 SG_ speed_limited_max : 23|1@0+ (1,0) [0|0] ""  External
 SG_ jerk_limited_min : 18|1@0+ (1,0) [0|0] ""  External
 SG_ jerk_limited_max : 19|1@0+ (1,0) [0|0] ""  External
 SG_ accel_limited_min : 20|1@0+ (1,0) [0|0] ""  External
 SG_ accel_limited_max : 21|1@0+ (1,0) [0|0] ""  External
 SG_ bypass_the_limiter : 2|1@0+ (1,0) [0|0] ""  External
 SG_ feed_forward_LV_Accel : 63|8@0- (0.0625,0) [-8|7.9375] "mpss"  External
 SG_ Raw_Accel : 55|8@0- (0.0625,0) [-8|7.9375] "mpss"  External
 SG_ Allowed_Jerk : 47|8@0- (0.1,0) [-12.8|12.7] "mpsss"  External
 SG_ Allowed_Accel : 39|8@0- (0.0625,0) [-8|7.9375] "mpss"  External
 SG_ Allowed_Speed : 17|10@0+ (0.0625,0) [0|63.9375] "mps"  External
 SG_ Desired_Speed_Limited : 1|10@0+ (0.0625,0) [0|63.9375] "mps"  External

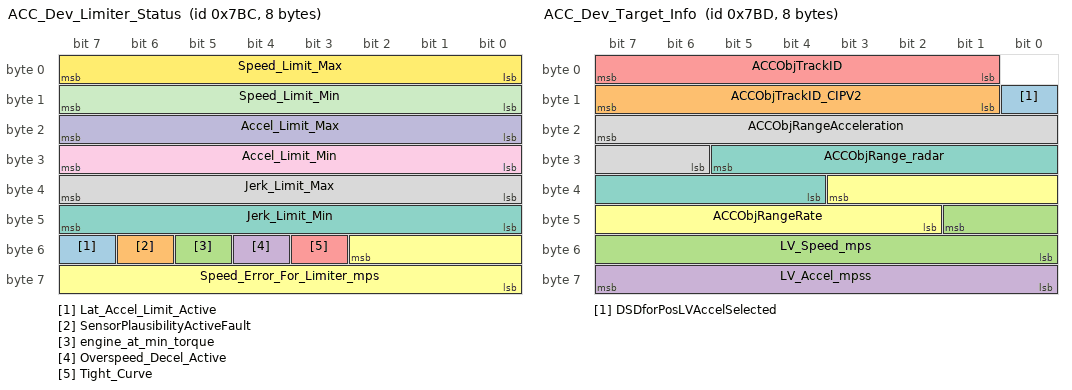
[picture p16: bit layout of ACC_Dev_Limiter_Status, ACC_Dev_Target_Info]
BO_ 1980 ACC_Dev_Limiter_Status: 8 IFV_CWMP
 SG_ Lat_Accel_Limit_Active : 55|1@0+ (1,0) [0|0] ""  External
 SG_ SensorPlausibilityActiveFault : 54|1@0+ (1,0) [0|0] ""  External
 SG_ engine_at_min_torque : 53|1@0+ (1,0) [0|0] ""  External
 SG_ Overspeed_Decel_Active : 52|1@0+ (1,0) [0|0] ""  External
 SG_ Tight_Curve : 51|1@0+ (1,0) [0|0] ""  External
 SG_ Speed_Error_For_Limiter_mps : 50|11@0- (0.0625,0) [-64|63.9375] "mps"  External
 SG_ Jerk_Limit_Min : 47|8@0- (0.1,0) [-12.8|12.7] "mpsss"  External
 SG_ Jerk_Limit_Max : 39|8@0- (0.1,0) [-12.8|12.7] "mpsss"  External
 SG_ Accel_Limit_Min : 31|8@0- (0.0625,-2) [-10|5.9375] "mpss"  External
 SG_ Accel_Limit_Max : 23|8@0- (0.0625,0) [-8|7.9375] "mpss"  External
 SG_ Speed_Limit_Min : 15|8@0+ (0.25,0) [0|64] "mps"  External
 SG_ Speed_Limit_Max : 7|8@0+ (0.25,0) [0|64] "mps"  External

BO_ 1981 ACC_Dev_Target_Info: 8 IFV_CWMP
 SG_ DSDforPosLVAccelSelected : 8|1@0+ (1,0) [0|1] "Boolean"  External
 SG_ ACCObjTrackID_CIPV2 : 15|7@0+ (1,0) [0|127] "Counts"  External
 SG_ LV_Speed_mps : 41|10@0+ (0.0625,0) [0|64] "mps"  External
 SG_ LV_Accel_mpss : 63|8@0- (0.0625,0) [-8|7.9375] "mpss"  External
 SG_ ACCObjTrackID : 7|7@0+ (1,0) [0|127] "Counts"  External
 SG_ ACCObjRangeRate : 35|10@0- (0.125,0) [-64|63.875] "mps"  External
 SG_ ACCObjRange_radar : 29|10@0+ (0.25,0) [0|255.75] "Meters"  External
 SG_ ACCObjRangeAcceleration : 23|10@0- (0.05,0) [-25.6|25.55] "m/s/s"  External

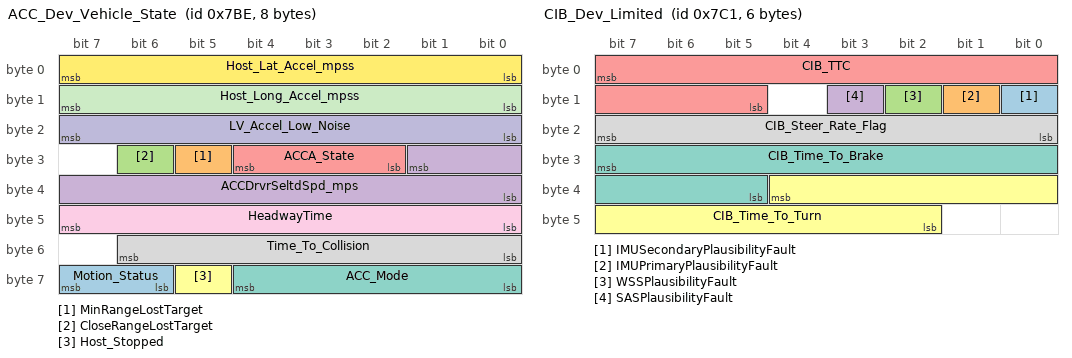
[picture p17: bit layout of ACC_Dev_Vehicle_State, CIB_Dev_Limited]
BO_ 1982 ACC_Dev_Vehicle_State: 8 IFV_CWMP
 SG_ Motion_Status : 63|2@0+ (1,0) [0|3] ""  External
 SG_ MinRangeLostTarget : 29|1@0+ (1,0) [0|1] ""  External
 SG_ CloseRangeLostTarget : 30|1@0+ (1,0) [0|1] ""  External
 SG_ ACCDrvrSeltdSpd_mps : 25|10@0+ (0.0625,0) [0|63.9375] "m/sec"  External
 SG_ ACCA_State : 28|3@0+ (1,0) [0|0] "Enum"  External
 SG_ Host_Stopped : 61|1@0+ (1,0) [0|0] ""  External
 SG_ ACC_Mode : 60|5@0+ (1,0) [0|31] "ENUM"  External
 SG_ Time_To_Collision : 54|7@0+ (0.25,0) [0|32] "sec"  External
 SG_ HeadwayTime : 47|8@0+ (0.05,0) [0|12.75] "Sec"  External
 SG_ LV_Accel_Low_Noise : 23|8@0- (0.0625,0) [-8|7.9375] "mpss"  External
 SG_ Host_Long_Accel_mpss : 15|8@0- (0.0625,0) [-8|7.9375] "mpss"  External
 SG_ Host_Lat_Accel_mpss : 7|8@0- (0.0625,0) [-8|7.9375] "mpss"  External

BO_ 1984 CIB_Dev_Data: 8 IFV_CWMP
 SG_ CIB_PCSEntryGatePassed : 59|1@0+ (1,0) [0|1] "Enum"  External
 SG_ CIB_LowBrakeDeploy : 62|1@0+ (1,0) [0|1] "Enum"  External
 SG_ CIB_HighBrakeDeploy : 61|1@0+ (1,0) [0|1] "Enum"  External
 SG_ CIB_InPathGatePassed : 60|1@0+ (1,0) [0|1] "Enum"  External
 SG_ CIB_ProcessCmbbTrack : 58|1@0+ (1,0) [0|1] "Enum"  External
 SG_ CIB_ProcessEachTrack : 57|1@0+ (1,0) [0|1] "Enum"  External
 SG_ CIB_NewTrackData : 56|1@0+ (1,0) [0|1] "Enum"  External
 SG_ CIB_PCSAlgoEntered : 50|1@0+ (1,0) [0|1] "Enum"  External
 SG_ CIB_StationaryObjectDelay_On : 5|1@0+ (1,0) [0|1] "Enum"  External
 SG_ CIB_Inhibit_Steering_OR : 4|1@0+ (1,0) [0|1] "Enum"  External
 SG_ CIB_Steering_OR : 3|1@0+ (1,0) [0|1] "Enum"  External
 SG_ CIB_OverrideTimer_On : 2|1@0+ (1,0) [0|1] "Enum"  External
 SG_ CIB_HighBrakeTimer_On : 1|1@0+ (1,0) [0|1] "Enum"  External
 SG_ CIB_GasPedal_OR : 0|1@0+ (1,0) [0|1] "Enum"  External
 SG_ CIB_Activation_Target_ID : 41|7@0- (1,0) [0|64] "Track No."  External
 SG_ CIB_Time_To_Turn : 36|11@0+ (0.015625,0) [0|31.984375] "Sec"  External
 SG_ CIB_Time_To_Brake : 31|11@0+ (0.015625,0) [0|31.984375] "Sec"  External
 SG_ CIB_Steer_Rate_Flag : 23|8@0+ (1,0) [0|0] "Counts"  External
 SG_ CIB_Filt_Accel_mpss : 15|8@0- (0.0625,0) [-8|7.9375] "mpss"  External
 SG_ CIB_FCW : 7|1@0+ (1,0) [0|0] "Boolean"  External
 SG_ CIB_Brake_Release : 6|1@0+ (1,0) [0|0] "boolean"  External
 SG_ CIB_Brake_Level : 49|3@0+ (1,0) [0|0] "Enum"  External

BO_ 1985 CIB_Dev_Limited: 6 IFV_CWMP
 SG_ IMUSecondaryPlausibilityFault : 8|1@0+ (1,0) [0|0] ""  External
 SG_ IMUPrimaryPlausibilityFault : 9|1@0+ (1,0) [0|0] ""  External
 SG_ WSSPlausibilityFault : 10|1@0+ (1,0) [0|0] ""  External
 SG_ SASPlausibilityFault : 11|1@0+ (1,0) [0|0] ""  External
 SG_ CIB_TTC : 7|11@0+ (0.015625,0) [0|31.984375] "Sec"  External
 SG_ CIB_Time_To_Turn : 36|11@0+ (0.015625,0) [0|31.984375] "Sec"  External
 SG_ CIB_Time_To_Brake : 31|11@0+ (0.015625,0) [0|31.984375] "Sec"  External
 SG_ CIB_Steer_Rate_Flag : 23|8@0+ (1,0) [0|0] "Counts"  External

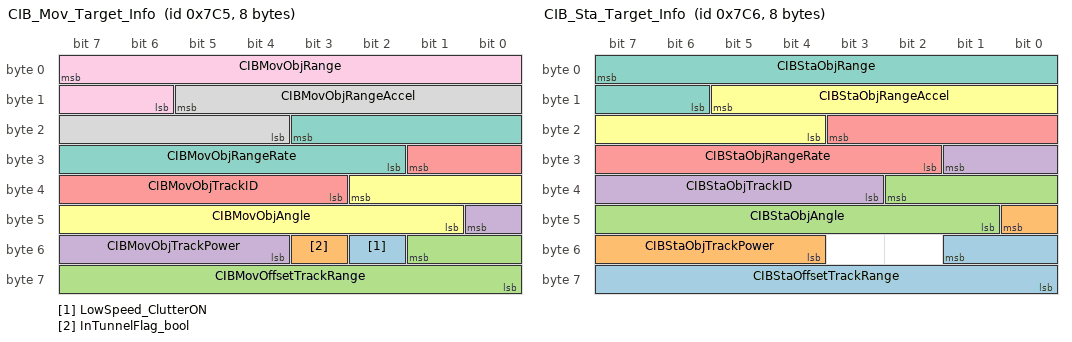
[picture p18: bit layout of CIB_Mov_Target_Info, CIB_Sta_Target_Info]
BO_ 1989 CIB_Mov_Target_Info: 8 IFV_CWMP
 SG_ LowSpeed_ClutterON : 50|1@0+ (1,0) [0|0] ""  External
 SG_ InTunnelFlag_bool : 51|1@0+ (1,0) [0|0] ""  External
 SG_ CIBMovOffsetTrackRange : 49|10@0+ (0.25,0) [0|255.75] "Meters"  External
 SG_ CIBMovObjTrackPower : 40|5@0+ (1,-10) [-10|21] "dB"  External
 SG_ CIBMovObjTrackID : 25|7@0+ (1,0) [0|127] "Counts"  External
 SG_ CIBMovObjAngle : 34|10@0- (0.1,0) [-51.2|51.1] "deg"  External
 SG_ CIBMovObjRangeRate : 19|10@0- (0.125,0) [-64|63.875] "mps"  External
 SG_ CIBMovObjRangeAccel : 13|10@0- (0.05,0) [-25.6|25.55] "m/s/s"  External
 SG_ CIBMovObjRange : 7|10@0+ (0.25,0) [0|255.75] "Meters"  External

BO_ 1990 CIB_Sta_Target_Info: 8 IFV_CWMP
 SG_ CIBStaOffsetTrackRange : 49|10@0+ (0.25,0) [0|255.75] "Meters"  External
 SG_ CIBStaObjTrackPower : 40|5@0+ (1,-10) [-10|21] "dB"  External
 SG_ CIBStaObjAngle : 34|10@0- (0.1,0) [-51.2|51.1] "deg"  External
 SG_ CIBStaObjTrackID : 25|7@0+ (1,0) [0|127] "Counts"  External
 SG_ CIBStaObjRangeRate : 19|10@0- (0.125,0) [-64|63.875] "mps"  External
 SG_ CIBStaObjRangeAccel : 13|10@0- (0.05,0) [-25.6|25.55] "m/s/s"  External
 SG_ CIBStaObjRange : 7|10@0+ (0.25,0) [0|255.75] "Meters"  External

BO_ 1991 FCW_Dev_Data: 4 IFV_CWMP
 SG_ FCW_Ref_TTC : 7|16@0+ (1,0) [0|65535] ""  External

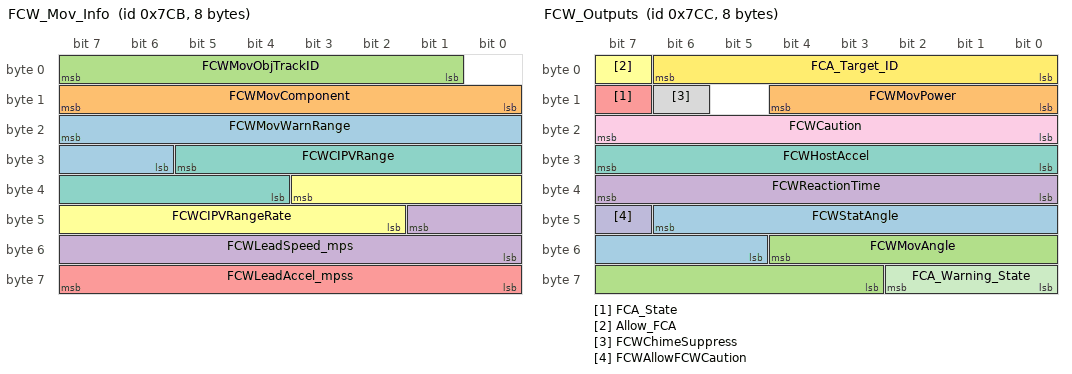
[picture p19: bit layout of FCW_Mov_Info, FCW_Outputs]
BO_ 1995 FCW_Mov_Info: 8 IFV_CWMP
 SG_ FCWMovWarnRange : 23|10@0+ (0.25,0) [0|255.75] "Meters"  External
 SG_ FCWMovComponent : 15|8@0+ (1,0) [0|0] "Bit Mapped"  External
 SG_ FCWMovObjTrackID : 7|7@0+ (1,0) [0|127] "Counts"  External
 SG_ FCWLeadSpeed_mps : 41|10@0+ (0.0625,0) [0|63.9375] "m/sec"  External
 SG_ FCWLeadAccel_mpss : 63|8@0- (0.0625,0) [-8|7.9375] "mpss"  External
 SG_ FCWCIPVRangeRate : 35|10@0- (0.125,0) [-64|63.875] "mps"  External
 SG_ FCWCIPVRange : 29|10@0+ (0.25,0) [0|255.75] "Meters"  External

BO_ 1996 FCW_Outputs: 8 IFV_CWMP
 SG_ FCWStatAngle : 46|10@0- (0.1,0) [-51.2|51.1] "deg"  External
 SG_ FCWMovPower : 12|5@0+ (1,-10) [-10|21] "dB"  External
 SG_ FCWMovAngle : 52|10@0- (0.1,0) [-51.2|51.1] "deg"  External
 SG_ FCWReactionTime : 39|8@0+ (0.0625,0) [0|10] "Sec"  External
 SG_ FCA_State : 15|1@0+ (1,0) [0|0] "Boolean"  External
 SG_ Allow_FCA : 7|1@0+ (1,0) [0|0] "Boolean"  External
 SG_ FCWHostAccel : 31|8@0- (0.0625,0) [-8|7.9375] "mpss"  External
 SG_ FCWChimeSuppress : 14|1@0+ (1,0) [0|0] "Boolean"  External
 SG_ FCWCaution : 23|8@0+ (0.5,0) [0|100] "Percent"  External
 SG_ FCWAllowFCWCaution : 47|1@0+ (1,0) [0|0] "Boolean"  External
 SG_ FCA_Warning_State : 58|3@0+ (1,0) [0|0] "Enumerated"  External
 SG_ FCA_Target_ID : 6|7@0+ (1,0) [0|127] "Counts"  External

BO_ 1997 FCW_Stat_Info: 8 IFV_CWMP
 SG_ FCWCIPSRangeRate : 44|10@0- (0.125,0) [-64|63.875] "mps"  External
 SG_ FCWStatWarnRange : 29|10@0+ (0.25,0) [0|255.75] "Meters"  External
 SG_ FCWStatObjTrackID : 7|7@0+ (1,0) [0|127] "Counts"  External
 SG_ FCWStatComponent : 15|8@0+ (1,0) [0|0] "Bit Mapped"  External
 SG_ FCWCIPSRange : 23|10@0+ (0.25,0) [0|255.75] "Meters"  External
 SG_ FCWCIPSLatTimer : 35|7@0+ (1,0) [0|100] "Counts"  External

BA_DEF_ SG_  "GenSigVtName" STRING ;
BA_DEF_ SG_  "GenSigVtIndex" STRING ;
BA_DEF_ SG_  "GenSigVtEn" STRING ;
BA_DEF_ SG_  "GenSigCmt" STRING ;
BA_DEF_ SG_  "GenSigStartValue" INT 0 1000000000;
BA_DEF_ SG_  "UsedOnPgmDBC" ENUM  "No","Yes";
BA_DEF_ SG_  "GenSigMissingSourceValue" INT 0 1000000000;
BA_DEF_ SG_  "GenSigInactiveValue" INT 0 100000;
BA_DEF_ SG_  "GenSigSendType" ENUM  "Cyclic","OnWrite","vector_leerstring","OnChange","vector_leerstring","IfActive","vector_leerstring","NoSigSendType";
BA_DEF_ BO_  "FrameGatewayMS1" HEX 0 1407;
BA_DEF_ BO_  "NetworkInitialization" ENUM  "No","Yes";
BA_DEF_ BO_  "EventRateOfChange" INT 10 10000;
BA_DEF_ BO_  "GenMsgStartDelayTime" INT 0 10000;
BA_DEF_ BO_  "GenMsgNrOfRepetition" INT 0 100;
BA_DEF_ BO_  "GenMsgDelayTime" INT 0 1000;
BA_DEF_ BO_  "GenMsgCycleTimeFast" INT 0 100000;
BA_DEF_ BO_  "GenMsgCycleTime" INT 0 100000;
BA_DEF_ BO_  "GenMsgSendType" ENUM  "FixedPeriodic","Event","EnabledPeriodic","NotUsed","NotUsed","EventPeriodic","NotUsed","NotUsed","NoMsgSendType";
BA_DEF_ BO_  "GenMsgILSupport" ENUM  "No","Yes";
BA_DEF_ SG_  "SystemSignalLongSymbol" STRING ;
BA_DEF_DEF_  "GenSigVtName" "";
BA_DEF_DEF_  "GenSigVtIndex" "";
BA_DEF_DEF_  "GenSigVtEn" "";
BA_DEF_DEF_  "GenSigCmt" "";
BA_DEF_DEF_  "GenSigStartValue" 0;
BA_DEF_DEF_  "UsedOnPgmDBC" "Yes";
BA_DEF_DEF_  "GenSigMissingSourceValue" 0;
BA_DEF_DEF_  "GenSigInactiveValue" 0;
BA_DEF_DEF_  "GenSigSendType" "NoSigSendType";
BA_DEF_DEF_  "FrameGatewayMS1" 0;
BA_DEF_DEF_  "NetworkInitialization" "Yes";
BA_DEF_DEF_  "EventRateOfChange" 10000;
BA_DEF_DEF_  "GenMsgStartDelayTime" 0;
BA_DEF_DEF_  "GenMsgNrOfRepetition" 0;
BA_DEF_DEF_  "GenMsgDelayTime" 0;
BA_DEF_DEF_  "GenMsgCycleTimeFast" 0;
BA_DEF_DEF_  "GenMsgCycleTime" 0;
BA_DEF_DEF_  "GenMsgSendType" "NoMsgSendType";
BA_DEF_DEF_  "GenMsgILSupport" "Yes";
BA_DEF_DEF_  "SystemSignalLongSymbol" "";
BA_ "NetworkInitialization" BO_ 259 0;
BA_ "GenMsgSendType" BO_ 259 1;
BA_ "GenMsgILSupport" BO_ 1654 0;
BA_ "NetworkInitialization" BO_ 1654 0;
BA_ "GenMsgSendType" BO_ 1654 1;
BA_ "NetworkInitialization" BO_ 1650 0;
BA_ "GenMsgSendType" BO_ 1650 1;
BA_ "NetworkInitialization" BO_ 1710 0;
BA_ "GenMsgSendType" BO_ 1710 1;
BA_ "NetworkInitialization" BO_ 1689 0;
BA_ "GenMsgSendType" BO_ 1689 1;
BA_ "NetworkInitialization" BO_ 1688 0;
BA_ "GenMsgSendType" BO_ 1688 1;
BA_ "NetworkInitialization" BO_ 1939 0;
BA_ "GenMsgSendType" BO_ 1939 1;
BA_ "NetworkInitialization" BO_ 1938 0;
BA_ "GenMsgSendType" BO_ 1938 1;
BA_ "NetworkInitialization" BO_ 1937 0;
BA_ "GenMsgSendType" BO_ 1937 1;
BA_ "NetworkInitialization" BO_ 1936 0;
BA_ "GenMsgSendType" BO_ 1936 1;
BA_ "NetworkInitialization" BO_ 1935 0;
BA_ "GenMsgSendType" BO_ 1935 1;
BA_ "NetworkInitialization" BO_ 1934 0;
BA_ "GenMsgSendType" BO_ 1934 1;
BA_ "NetworkInitialization" BO_ 1933 0;
BA_ "GenMsgSendType" BO_ 1933 1;
BA_ "NetworkInitialization" BO_ 1932 0;
BA_ "GenMsgSendType" BO_ 1932 1;
BA_ "NetworkInitialization" BO_ 1931 0;
BA_ "GenMsgSendType" BO_ 1931 1;
BA_ "NetworkInitialization" BO_ 1930 0;
BA_ "GenMsgSendType" BO_ 1930 1;
BA_ "NetworkInitialization" BO_ 1929 0;
BA_ "GenMsgSendType" BO_ 1929 1;
BA_ "NetworkInitialization" BO_ 1709 0;
BA_ "GenMsgSendType" BO_ 1709 1;
BA_ "NetworkInitialization" BO_ 1701 0;
BA_ "GenMsgSendType" BO_ 1701 1;
BA_ "GenMsgILSupport" BO_ 1655 0;
BA_ "NetworkInitialization" BO_ 1655 0;
BA_ "GenMsgSendType" BO_ 1655 1;
BA_ "GenMsgILSupport" BO_ 1653 0;
BA_ "NetworkInitialization" BO_ 1653 0;
BA_ "GenMsgSendType" BO_ 1653 1;
BA_ "NetworkInitialization" BO_ 1702 0;
BA_ "GenMsgSendType" BO_ 1702 1;
BA_ "NetworkInitialization" BO_ 1707 0;
BA_ "GenMsgSendType" BO_ 1707 1;
BA_ "NetworkInitialization" BO_ 1703 0;
BA_ "GenMsgSendType" BO_ 1703 1;
BA_ "NetworkInitialization" BO_ 1708 0;
BA_ "GenMsgSendType" BO_ 1708 1;
BA_ "NetworkInitialization" BO_ 1687 0;
BA_ "GenMsgSendType" BO_ 1687 1;
BA_ "NetworkInitialization" BO_ 1686 0;
BA_ "GenMsgSendType" BO_ 1686 1;
BA_ "NetworkInitialization" BO_ 1685 0;
BA_ "GenMsgSendType" BO_ 1685 1;
BA_ "NetworkInitialization" BO_ 1684 0;
BA_ "GenMsgSendType" BO_ 1684 1;
BA_ "NetworkInitialization" BO_ 1683 0;
BA_ "GenMsgSendType" BO_ 1683 1;
BA_ "NetworkInitialization" BO_ 1682 0;
BA_ "GenMsgSendType" BO_ 1682 1;
BA_ "NetworkInitialization" BO_ 1681 0;
BA_ "GenMsgSendType" BO_ 1681 1;
BA_ "NetworkInitialization" BO_ 1680 0;
BA_ "GenMsgSendType" BO_ 1680 1;
BA_ "NetworkInitialization" BO_ 1700 0;
BA_ "GenMsgSendType" BO_ 1700 1;
BA_ "NetworkInitialization" BO_ 1649 0;
BA_ "GenMsgSendType" BO_ 1649 1;
BA_ "NetworkInitialization" BO_ 1171 0;
BA_ "GenMsgSendType" BO_ 1171 1;
BA_ "NetworkInitialization" BO_ 1155 0;
BA_ "GenMsgSendType" BO_ 1155 1;
BA_ "NetworkInitialization" BO_ 1139 0;
BA_ "GenMsgSendType" BO_ 1139 1;
BA_ "NetworkInitialization" BO_ 1123 0;
BA_ "GenMsgSendType" BO_ 1123 1;
BA_ "NetworkInitialization" BO_ 1107 0;
BA_ "GenMsgSendType" BO_ 1107 1;
BA_ "NetworkInitialization" BO_ 1091 0;
BA_ "GenMsgSendType" BO_ 1091 1;
BA_ "NetworkInitialization" BO_ 1075 0;
BA_ "GenMsgSendType" BO_ 1075 1;
BA_ "NetworkInitialization" BO_ 1059 0;
BA_ "GenMsgSendType" BO_ 1059 1;
BA_ "NetworkInitialization" BO_ 1043 0;
BA_ "GenMsgSendType" BO_ 1043 1;
BA_ "NetworkInitialization" BO_ 1170 0;
BA_ "GenMsgSendType" BO_ 1170 1;
BA_ "NetworkInitialization" BO_ 1154 0;
BA_ "GenMsgSendType" BO_ 1154 1;
BA_ "NetworkInitialization" BO_ 1138 0;
BA_ "GenMsgSendType" BO_ 1138 1;
BA_ "NetworkInitialization" BO_ 1122 0;
BA_ "GenMsgSendType" BO_ 1122 1;
BA_ "NetworkInitialization" BO_ 1106 0;
BA_ "GenMsgSendType" BO_ 1106 1;
BA_ "NetworkInitialization" BO_ 1090 0;
BA_ "GenMsgSendType" BO_ 1090 1;
BA_ "NetworkInitialization" BO_ 1074 0;
BA_ "GenMsgSendType" BO_ 1074 1;
BA_ "NetworkInitialization" BO_ 1058 0;
BA_ "GenMsgSendType" BO_ 1058 1;
BA_ "NetworkInitialization" BO_ 1042 0;
BA_ "GenMsgSendType" BO_ 1042 1;
BA_ "NetworkInitialization" BO_ 1169 0;
BA_ "GenMsgSendType" BO_ 1169 1;
BA_ "NetworkInitialization" BO_ 1153 0;
BA_ "GenMsgSendType" BO_ 1153 1;
BA_ "NetworkInitialization" BO_ 1137 0;
BA_ "GenMsgSendType" BO_ 1137 1;
BA_ "NetworkInitialization" BO_ 1121 0;
BA_ "GenMsgSendType" BO_ 1121 1;
BA_ "NetworkInitialization" BO_ 1105 0;
BA_ "GenMsgSendType" BO_ 1105 1;
BA_ "NetworkInitialization" BO_ 1089 0;
BA_ "GenMsgSendType" BO_ 1089 1;
BA_ "NetworkInitialization" BO_ 1073 0;
BA_ "GenMsgSendType" BO_ 1073 1;
BA_ "NetworkInitialization" BO_ 1057 0;
BA_ "GenMsgSendType" BO_ 1057 1;
BA_ "NetworkInitialization" BO_ 1041 0;
BA_ "GenMsgSendType" BO_ 1041 1;
BA_ "NetworkInitialization" BO_ 1026 0;
BA_ "GenMsgSendType" BO_ 1026 1;
BA_ "GenMsgSendType" BO_ 1958 1;
BA_ "GenMsgSendType" BO_ 1957 1;
BA_ "GenMsgSendType" BO_ 1956 1;
BA_ "GenMsgSendType" BO_ 1955 1;
BA_ "GenMsgSendType" BO_ 1954 1;
BA_ "GenMsgSendType" BO_ 1953 1;
BA_ "GenMsgSendType" BO_ 1959 1;
BA_ "GenMsgSendType" BO_ 1988 1;
BA_ "GenMsgSendType" BO_ 1987 1;
BA_ "GenMsgSendType" BO_ 1986 1;
BA_ "GenMsgSendType" BO_ 1994 1;
BA_ "GenMsgSendType" BO_ 1993 1;
BA_ "GenMsgSendType" BO_ 1992 1;
BA_ "GenMsgSendType" BO_ 1973 1;
BA_ "GenMsgSendType" BO_ 1972 1;
BA_ "GenMsgSendType" BO_ 1971 1;
BA_ "GenMsgSendType" BO_ 1970 1;
BA_ "GenMsgSendType" BO_ 1969 1;
BA_ "GenMsgSendType" BO_ 1968 1;
BA_ "GenMsgSendType" BO_ 1974 1;
BA_ "GenMsgSendType" BO_ 1975 1;
BA_ "GenMsgSendType" BO_ 1976 1;
BA_ "GenMsgSendType" BO_ 1977 1;
BA_ "GenMsgSendType" BO_ 1978 1;
BA_ "GenMsgSendType" BO_ 1979 1;
BA_ "GenMsgSendType" BO_ 1980 1;
BA_ "GenMsgSendType" BO_ 1981 1;
BA_ "GenMsgSendType" BO_ 1982 1;
BA_ "GenMsgSendType" BO_ 1984 1;
BA_ "GenMsgSendType" BO_ 1985 1;
BA_ "GenMsgSendType" BO_ 1989 1;
BA_ "GenMsgSendType" BO_ 1990 1;
BA_ "GenMsgSendType" BO_ 1991 1;
BA_ "GenMsgSendType" BO_ 1995 1;
BA_ "GenMsgSendType" BO_ 1996 1;
BA_ "GenMsgSendType" BO_ 1997 1;
BA_ "GenSigSendType" SG_ 259 ETSEL_common_1_MessageCounter 1;
BA_ "GenSigSendType" SG_ 259 Traffic_Direction 1;
BA_ "GenSigSendType" SG_ 259 Predicted_Path_Lane_Width 1;
BA_ "GenSigSendType" SG_ 259 LROS_MVS_UpdatePulse 1;
BA_ "GenSigSendType" SG_ 259 LROS_FUS_UpdatePulse 1;
BA_ "GenSigSendType" SG_ 259 FiltVehicleSpeedOverGround 1;
BA_ "GenSigStartValue" SG_ 1654 VIS_OBS_LONG_ACCEL_15 2560;
BA_ "GenSigStartValue" SG_ 1654 VIS_OBS_LONG_ACCEL_14 2560;
BA_ "GenSigStartValue" SG_ 1654 VIS_OBS_LONG_ACCEL_13 2560;
BA_ "GenSigStartValue" SG_ 1654 VIS_OBS_LONG_ACCEL_12 2560;
BA_ "GenSigStartValue" SG_ 1654 VIS_OBS_LONG_ACCEL_11 2560;
BA_ "GenSigStartValue" SG_ 1654 VIS_OBS_LONG_ACCEL_10 2560;
BA_ "GenSigStartValue" SG_ 1654 VIS_OBS_LONG_ACCEL_09 2560;
BA_ "GenSigStartValue" SG_ 1654 VIS_OBS_LONG_ACCEL_08 2560;
BA_ "GenSigStartValue" SG_ 1654 VIS_OBS_LONG_ACCEL_07 2560;
BA_ "GenSigStartValue" SG_ 1654 VIS_OBS_LONG_ACCEL_06 2560;
BA_ "GenSigStartValue" SG_ 1654 VIS_OBS_LONG_ACCEL_05 2560;
BA_ "GenSigStartValue" SG_ 1654 VIS_OBS_LONG_ACCEL_04 2560;
BA_ "GenSigStartValue" SG_ 1654 VIS_OBS_LONG_ACCEL_03 2560;
BA_ "GenSigStartValue" SG_ 1654 VIS_OBS_LONG_ACCEL_02 2560;
BA_ "GenSigStartValue" SG_ 1654 VIS_OBS_LONG_ACCEL_01 2560;
BA_ "GenSigSendType" SG_ 1650 VIS_FAILSAFE_PART_BLOCK 1;
BA_ "GenSigVtEn" SG_ 1650 VIS_FAILSAFE_OUT_OF_FOCUS "TRUE";
BA_ "GenSigVtName" SG_ 1650 VIS_FAILSAFE_OUT_OF_FOCUS "VtSig_VIS_FAILSAFE_OUT_OF_FOCUS";
BA_ "GenSigSendType" SG_ 1650 VIS_FAILSAFE_OUT_OF_FOCUS 1;
BA_ "GenSigVtEn" SG_ 1650 VIS_FAILSAFE_OUT_OF_CALIBRATION "TRUE";
BA_ "GenSigVtName" SG_ 1650 VIS_FAILSAFE_OUT_OF_CALIBRATION "VtSig_VIS_FAILSAFE_OUT_OF_CALIBRATION";
BA_ "GenSigSendType" SG_ 1650 VIS_FAILSAFE_OUT_OF_CALIBRATION 1;
BA_ "GenSigVtEn" SG_ 1650 FUS_FAILSAFE_FUS_RAD_MISALIGNMNT "TRUE";
BA_ "GenSigVtName" SG_ 1650 FUS_FAILSAFE_FUS_RAD_MISALIGNMNT "VtSig_FUS_FAILSAFE_FUS_RAD_MISALIGNMNT";
BA_ "GenSigSendType" SG_ 1650 FUS_FAILSAFE_FUS_RAD_MISALIGNMNT 1;
BA_ "GenSigVtEn" SG_ 1650 FUS_FAILSAFE_FUS_RAD_LOW_VIS "TRUE";
BA_ "GenSigVtName" SG_ 1650 FUS_FAILSAFE_FUS_RAD_LOW_VIS "VtSig_FUS_FAILSAFE_FUS_RAD_LOW_VIS";
BA_ "GenSigSendType" SG_ 1650 FUS_FAILSAFE_FUS_RAD_LOW_VIS 1;
BA_ "GenSigVtEn" SG_ 1650 VIS_FAILSAFE_NIGHT_SPOT_RAYS "TRUE";
BA_ "GenSigVtName" SG_ 1650 VIS_FAILSAFE_NIGHT_SPOT_RAYS "VtSig_VIS_FAILSAFE_NIGHT_SPOT_RAYS";
BA_ "GenSigSendType" SG_ 1650 VIS_FAILSAFE_NIGHT_SPOT_RAYS 1;
BA_ "GenSigVtEn" SG_ 1650 VIS_FAILSAFE_NIGHT_SMEARED_SPOTS "TRUE";
BA_ "GenSigVtName" SG_ 1650 VIS_FAILSAFE_NIGHT_SMEARED_SPOTS "VtSig_VIS_FAILSAFE_NIGHT_SMEARED_SPOTS";
BA_ "GenSigSendType" SG_ 1650 VIS_FAILSAFE_NIGHT_SMEARED_SPOTS 1;
BA_ "GenSigVtEn" SG_ 1650 VIS_FAILSAFE_NIGHT_SELF_GLARE "TRUE";
BA_ "GenSigVtName" SG_ 1650 VIS_FAILSAFE_NIGHT_SELF_GLARE "VtSig_VIS_FAILSAFE_NIGHT_SELF_GLARE";
BA_ "GenSigSendType" SG_ 1650 VIS_FAILSAFE_NIGHT_SELF_GLARE 1;
BA_ "GenSigVtEn" SG_ 1650 VIS_FAILSAFE_SMEAR_IMAGE "TRUE";
BA_ "GenSigVtName" SG_ 1650 VIS_FAILSAFE_SMEAR_IMAGE "VtSig_VIS_FAILSAFE_SMEAR_IMAGE";
BA_ "GenSigSendType" SG_ 1650 VIS_FAILSAFE_SMEAR_IMAGE 1;
BA_ "GenSigVtEn" SG_ 1650 VIS_FAILSAFE_NIGHT_FULL_BLOCK "TRUE";
BA_ "GenSigVtName" SG_ 1650 VIS_FAILSAFE_NIGHT_FULL_BLOCK "VtSig_VIS_FAILSAFE_NIGHT_FULL_BLOCK";
BA_ "GenSigSendType" SG_ 1650 VIS_FAILSAFE_NIGHT_FULL_BLOCK 1;
BA_ "GenSigVtEn" SG_ 1650 VIS_FAILSAFE_NIGHT_FOGGY_SPOTS "TRUE";
BA_ "GenSigVtName" SG_ 1650 VIS_FAILSAFE_NIGHT_FOGGY_SPOTS "VtSig_VIS_FAILSAFE_NIGHT_FOGGY_SPOTS";
BA_ "GenSigSendType" SG_ 1650 VIS_FAILSAFE_NIGHT_FOGGY_SPOTS 1;
BA_ "GenSigVtEn" SG_ 1650 VIS_FAILSAFE_NIGHT_BLUR "TRUE";
BA_ "GenSigVtName" SG_ 1650 VIS_FAILSAFE_NIGHT_BLUR "VtSig_VIS_FAILSAFE_NIGH_BLUR";
BA_ "GenSigSendType" SG_ 1650 VIS_FAILSAFE_NIGHT_BLUR 1;
BA_ "GenSigVtEn" SG_ 1650 VIS_FAILSAFE_DAY_SUN_RAY "TRUE";
BA_ "GenSigVtName" SG_ 1650 VIS_FAILSAFE_DAY_SUN_RAY "VtSig_VIS_FAILSAFE_DAY_SUN_RAY";
BA_ "GenSigSendType" SG_ 1650 VIS_FAILSAFE_DAY_SUN_RAY 1;
BA_ "GenSigVtEn" SG_ 1650 VIS_FAILSAFE_DAY_SPLASHES "TRUE";
BA_ "GenSigVtName" SG_ 1650 VIS_FAILSAFE_DAY_SPLASHES "VtSig_VIS_FAILSAFE_DAY_SPLASHES";
BA_ "GenSigSendType" SG_ 1650 VIS_FAILSAFE_DAY_SPLASHES 1;
BA_ "GenSigVtEn" SG_ 1650 VIS_FAILSAFE_DAY_LOW_SUN "TRUE";
BA_ "GenSigVtName" SG_ 1650 VIS_FAILSAFE_DAY_LOW_SUN "VtSig_VIS_FAILSAFE_DAY_LOW_SUN";
BA_ "GenSigSendType" SG_ 1650 VIS_FAILSAFE_DAY_LOW_SUN 1;
BA_ "GenSigVtEn" SG_ 1650 CAN_DRIVING_SIDE "TRUE";
BA_ "GenSigVtName" SG_ 1650 CAN_DRIVING_SIDE "VtSig_CAN_DRIVING_SIDE";
BA_ "GenSigSendType" SG_ 1650 CAN_DRIVING_SIDE 1;
BA_ "GenSigVtEn" SG_ 1650 VIS_FAILSAFE_FLR_VIS_CORRELATION "TRUE";
BA_ "GenSigVtName" SG_ 1650 VIS_FAILSAFE_FLR_VIS_CORRELATION "VtSig_VIS_FAILSAFE_FLR_VIS_CORRELATION";
BA_ "GenSigSendType" SG_ 1650 VIS_FAILSAFE_FLR_VIS_CORRELATION 1;
BA_ "GenSigVtEn" SG_ 1650 VIS_FAULT_INVALID_SPEED_YAW "TRUE";
BA_ "GenSigVtName" SG_ 1650 VIS_FAULT_INVALID_SPEED_YAW "VtSig_VIS_FAULT_INVALID_SPEED_YAW";
BA_ "GenSigSendType" SG_ 1650 VIS_FAULT_INVALID_SPEED_YAW 1;
BA_ "GenSigVtEn" SG_ 1650 VIS_FAULT_IMAGER_RCC_MISALIGNED "TRUE";
BA_ "GenSigVtName" SG_ 1650 VIS_FAULT_IMAGER_RCC_MISALIGNED "VtSig_VIS_FAULT_IMAGER_RCC_MISALIGNED";
BA_ "GenSigSendType" SG_ 1650 VIS_FAULT_IMAGER_RCC_MISALIGNED 1;
BA_ "GenSigVtEn" SG_ 1650 VIS_FAILSAFE_PART_BLUR_IMAGE "TRUE";
BA_ "GenSigVtName" SG_ 1650 VIS_FAILSAFE_PART_BLUR_IMAGE "VtSig_VIS_FAILSAFE_PART_BLUR_IMAGE";
BA_ "GenSigSendType" SG_ 1650 VIS_FAILSAFE_PART_BLUR_IMAGE 1;
BA_ "GenSigVtEn" SG_ 1650 VIS_FAILSAFE_PART_SOLID_BLOCKAGE "TRUE";
BA_ "GenSigVtName" SG_ 1650 VIS_FAILSAFE_PART_SOLID_BLOCKAGE "VtSig_VIS_FAILSAFE_PART_SOLID_BLOCKAGE";
BA_ "GenSigSendType" SG_ 1650 VIS_FAILSAFE_PART_SOLID_BLOCKAGE 1;
BA_ "GenSigVtEn" SG_ 1650 VIS_FAILSAFE_HEAVY_RAIN "TRUE";
BA_ "GenSigVtName" SG_ 1650 VIS_FAILSAFE_HEAVY_RAIN "VtSig_VIS_FAILSAFE_HEAVY_RAIN";
BA_ "GenSigSendType" SG_ 1650 VIS_FAILSAFE_HEAVY_RAIN 1;
BA_ "GenSigVtEn" SG_ 1650 VIS_FAILSAFE_ROLL_ANGLE "TRUE";
BA_ "GenSigVtName" SG_ 1650 VIS_FAILSAFE_ROLL_ANGLE "VtSig_VIS_FAILSAFE_ROLL_ANGLE";
BA_ "GenSigSendType" SG_ 1650 VIS_FAILSAFE_ROLL_ANGLE 1;
BA_ "GenSigSendType" SG_ 1710 VIS_LANE_TIMESTAMP 1;
BA_ "GenSigVtEn" SG_ 1689 VIS_TSR_SIGN_EMBEDDED_1 "TRUE";
BA_ "GenSigVtName" SG_ 1689 VIS_TSR_SIGN_EMBEDDED_1 "VtSig_VIS_TSR_SIGN_EMBEDDED_SCENE_1";
BA_ "GenSigSendType" SG_ 1689 VIS_TSR_SIGN_EMBEDDED_1 1;
BA_ "GenSigVtEn" SG_ 1689 VIS_TSR_SIGN_LANE_1 "TRUE";
BA_ "GenSigVtName" SG_ 1689 VIS_TSR_SIGN_LANE_1 "VtSig_VIS_TSR_SIGN_LANE_1";
BA_ "GenSigSendType" SG_ 1689 VIS_TSR_SIGN_LANE_1 1;
BA_ "GenSigVtEn" SG_ 1689 VIS_TSR_SIGN_POSITION_1 "TRUE";
BA_ "GenSigVtName" SG_ 1689 VIS_TSR_SIGN_POSITION_1 "VtSig_VIS_TSR_SIGN_POSITION_1";
BA_ "GenSigSendType" SG_ 1689 VIS_TSR_SIGN_POSITION_1 1;
BA_ "GenSigVtEn" SG_ 1689 VIS_TSR_SIGN_SUPPL_TYPE2_1 "TRUE";
BA_ "GenSigVtName" SG_ 1689 VIS_TSR_SIGN_SUPPL_TYPE2_1 "VtSig_VIS_TSR_SIGN_SUPPL_TYPE2_1";
BA_ "GenSigSendType" SG_ 1689 VIS_TSR_SIGN_SUPPL_TYPE2_1 1;
BA_ "GenSigVtEn" SG_ 1689 VIS_TSR_SIGN_SUPPL_TYPE1_1 "TRUE";
BA_ "GenSigVtName" SG_ 1689 VIS_TSR_SIGN_SUPPL_TYPE1_1 "VtSig_VIS_TSR_SIGN_SUPPL_TYPE1_1";
BA_ "GenSigSendType" SG_ 1689 VIS_TSR_SIGN_SUPPL_TYPE1_1 1;
BA_ "GenSigVtEn" SG_ 1689 VIS_TSR_SIGN_VARIABLE_1 "TRUE";
BA_ "GenSigVtName" SG_ 1689 VIS_TSR_SIGN_VARIABLE_1 "VtSig_VIS_TSR_SIGN_VARIABLE_1";
BA_ "GenSigSendType" SG_ 1689 VIS_TSR_SIGN_VARIABLE_1 1;
BA_ "GenSigSendType" SG_ 1689 VIS_TSR_SIGN_VALUE_1 1;
BA_ "GenSigVtEn" SG_ 1689 VIS_TSR_SIGN_TYPE_1 "TRUE";
BA_ "GenSigVtName" SG_ 1689 VIS_TSR_SIGN_TYPE_1 "VtSig_VIS_TSR_SIGN_TYPE_1";
BA_ "GenSigSendType" SG_ 1689 VIS_TSR_SIGN_TYPE_1 1;
BA_ "GenSigSendType" SG_ 1689 VIS_TSR_SIGN_ID_1 1;
BA_ "GenSigVtEn" SG_ 1689 VIS_TSR_SCENE_STATUS_1 "TRUE";
BA_ "GenSigVtName" SG_ 1689 VIS_TSR_SCENE_STATUS_1 "VtSig_VIS_TSR_SCENE_STATUS_1";
BA_ "GenSigSendType" SG_ 1689 VIS_TSR_SCENE_STATUS_1 1;
BA_ "GenSigSendType" SG_ 1689 VIS_TSR_SCENE_ID_1 1;
BA_ "GenSigVtEn" SG_ 1688 VIS_TSR_LANE_CHANGE "TRUE";
BA_ "GenSigVtName" SG_ 1688 VIS_TSR_LANE_CHANGE "VtSig_VIS_TSR_LANE_CHANGE";
BA_ "GenSigSendType" SG_ 1688 VIS_TSR_LANE_CHANGE 1;
BA_ "GenSigVtEn" SG_ 1688 VIS_TSR_ROAD_CLASS "TRUE";
BA_ "GenSigVtName" SG_ 1688 VIS_TSR_ROAD_CLASS "VtSig_VIS_TSR_ROAD_CLASS";
BA_ "GenSigSendType" SG_ 1688 VIS_TSR_ROAD_CLASS 1;
BA_ "GenSigVtEn" SG_ 1688 VIS_TSR_SPEED_UNIT "TRUE";
BA_ "GenSigVtName" SG_ 1688 VIS_TSR_SPEED_UNIT "VtSig_VIS_TSR_SPEED_UNIT";
BA_ "GenSigSendType" SG_ 1688 VIS_TSR_SPEED_UNIT 1;
BA_ "GenSigVtEn" SG_ 1688 VIS_TSR_TRAFFIC_STYLE "TRUE";
BA_ "GenSigVtName" SG_ 1688 VIS_TSR_TRAFFIC_STYLE "VtSig_VIS_TSR_TRAFFIC_STYLE";
BA_ "GenSigSendType" SG_ 1688 VIS_TSR_TRAFFIC_STYLE 1;
BA_ "GenSigVtEn" SG_ 1939 VIS_AHBC_DARK_ONCOMING_LANE "TRUE";
BA_ "GenSigVtName" SG_ 1939 VIS_AHBC_DARK_ONCOMING_LANE "VtSig_VIS_AHBC_DARK_ONCOMING_LANE";
BA_ "GenSigSendType" SG_ 1939 VIS_AHBC_DARK_ONCOMING_LANE 1;
BA_ "GenSigSendType" SG_ 1939 VIS_AHBC_PRECEDING_SPOTS 1;
BA_ "GenSigSendType" SG_ 1939 VIS_AHBC_ONCOMING_SPOTS 1;
BA_ "GenSigVtEn" SG_ 1939 VIS_AHBC_CLEAR_FIELD_OF_VIEW "TRUE";
BA_ "GenSigVtName" SG_ 1939 VIS_AHBC_CLEAR_FIELD_OF_VIEW "VtSig_VIS_AHBC_CLEAR_FIELD_OF_VIEW";
BA_ "GenSigSendType" SG_ 1939 VIS_AHBC_CLEAR_FIELD_OF_VIEW 1;
BA_ "GenSigVtEn" SG_ 1939 VIS_AHBC_STRUCT_SEPARATION_DET "TRUE";
BA_ "GenSigVtName" SG_ 1939 VIS_AHBC_STRUCT_SEPARATION_DET "VtSig_VIS_AHBC_STRUCT_SEPARATION_DET";
BA_ "GenSigSendType" SG_ 1939 VIS_AHBC_STRUCT_SEPARATION_DET 1;
BA_ "GenSigVtEn" SG_ 1939 VIS_AHBC_DAY_TIME_STATUS "TRUE";
BA_ "GenSigVtName" SG_ 1939 VIS_AHBC_DAY_TIME_STATUS "VtSig_VIS_AHBC_DAY_TIME_STATUS";
BA_ "GenSigSendType" SG_ 1939 VIS_AHBC_DAY_TIME_STATUS 1;
BA_ "GenSigVtEn" SG_ 1939 VIS_AHBC_FOG_DETECTION "TRUE";
BA_ "GenSigVtName" SG_ 1939 VIS_AHBC_FOG_DETECTION "VtSig_VIS_AHBC_FOG_DETECTION";
BA_ "GenSigSendType" SG_ 1939 VIS_AHBC_FOG_DETECTION 1;
BA_ "GenSigVtEn" SG_ 1939 VIS_AHBC_HIGHWAY_DETECTION "TRUE";
BA_ "GenSigVtName" SG_ 1939 VIS_AHBC_HIGHWAY_DETECTION "VtSig_VIS_AHBC_HIGHWAY_DETECTION";
BA_ "GenSigSendType" SG_ 1939 VIS_AHBC_HIGHWAY_DETECTION 1;
BA_ "GenSigVtEn" SG_ 1939 VIS_AHBC_URBAN_AREA_DETECTION "TRUE";
BA_ "GenSigVtName" SG_ 1939 VIS_AHBC_URBAN_AREA_DETECTION "VtSig_VIS_AHBC_URBAN_AREA_DETECTION";
BA_ "GenSigSendType" SG_ 1939 VIS_AHBC_URBAN_AREA_DETECTION 1;
BA_ "GenSigVtEn" SG_ 1939 VIS_AHBC_TRAFFIC_STYLE_DETECTION "TRUE";
BA_ "GenSigVtName" SG_ 1939 VIS_AHBC_TRAFFIC_STYLE_DETECTION "VtSig_VIS_AHBC_TRAFFIC_STYLE_DETECTION";
BA_ "GenSigSendType" SG_ 1939 VIS_AHBC_TRAFFIC_STYLE_DETECTION 1;
BA_ "GenSigSendType" SG_ 1938 VIS_AHBC_OBJ_10_VERTICAL_POS 1;
BA_ "GenSigVtEn" SG_ 1938 VIS_AHBC_OBJ_10_TYPE "TRUE";
BA_ "GenSigVtName" SG_ 1938 VIS_AHBC_OBJ_10_TYPE "VtSig_VIS_AHBC_OBJ_10_TYPE";
BA_ "GenSigSendType" SG_ 1938 VIS_AHBC_OBJ_10_TYPE 1;
BA_ "GenSigSendType" SG_ 1938 VIS_AHBC_OBJ_10_ID 1;
BA_ "GenSigSendType" SG_ 1938 VIS_AHBC_OBJ_10_HORIZONTAL_POS 1;
BA_ "GenSigSendType" SG_ 1938 VIS_AHBC_OBJ_10_HORIZONTAL_DIM 1;
BA_ "GenSigVtEn" SG_ 1938 VIS_AHBC_OBJ_10_DISTANCE "TRUE";
BA_ "GenSigVtName" SG_ 1938 VIS_AHBC_OBJ_10_DISTANCE "VtSig_VIS_AHBC_OBJ_10_DISTANCE";
BA_ "GenSigSendType" SG_ 1938 VIS_AHBC_OBJ_10_DISTANCE 1;
BA_ "GenSigSendType" SG_ 1937 VIS_AHBC_OBJ_09_VERTICAL_POS 1;
BA_ "GenSigVtEn" SG_ 1937 VIS_AHBC_OBJ_09_TYPE "TRUE";
BA_ "GenSigVtName" SG_ 1937 VIS_AHBC_OBJ_09_TYPE "VtSig_VIS_AHBC_OBJ_09_TYPE";
BA_ "GenSigSendType" SG_ 1937 VIS_AHBC_OBJ_09_TYPE 1;
BA_ "GenSigSendType" SG_ 1937 VIS_AHBC_OBJ_09_ID 1;
BA_ "GenSigSendType" SG_ 1937 VIS_AHBC_OBJ_09_HORIZONTAL_POS 1;
BA_ "GenSigSendType" SG_ 1937 VIS_AHBC_OBJ_09_HORIZONTAL_DIM 1;
BA_ "GenSigVtEn" SG_ 1937 VIS_AHBC_OBJ_09_DISTANCE "TRUE";
BA_ "GenSigVtName" SG_ 1937 VIS_AHBC_OBJ_09_DISTANCE "VtSig_VIS_AHBC_OBJ_09_DISTANCE";
BA_ "GenSigSendType" SG_ 1937 VIS_AHBC_OBJ_09_DISTANCE 1;
BA_ "GenSigSendType" SG_ 1936 VIS_AHBC_OBJ_08_VERTICAL_POS 1;
BA_ "GenSigVtEn" SG_ 1936 VIS_AHBC_OBJ_08_TYPE "TRUE";
BA_ "GenSigVtName" SG_ 1936 VIS_AHBC_OBJ_08_TYPE "VtSig_VIS_AHBC_OBJ_08_TYPE";
BA_ "GenSigSendType" SG_ 1936 VIS_AHBC_OBJ_08_TYPE 1;
BA_ "GenSigSendType" SG_ 1936 VIS_AHBC_OBJ_08_ID 1;
BA_ "GenSigSendType" SG_ 1936 VIS_AHBC_OBJ_08_HORIZONTAL_POS 1;
BA_ "GenSigSendType" SG_ 1936 VIS_AHBC_OBJ_08_HORIZONTAL_DIM 1;
BA_ "GenSigVtEn" SG_ 1936 VIS_AHBC_OBJ_08_DISTANCE "TRUE";
BA_ "GenSigVtName" SG_ 1936 VIS_AHBC_OBJ_08_DISTANCE "VtSig_VIS_AHBC_OBJ_08_DISTANCE";
BA_ "GenSigSendType" SG_ 1936 VIS_AHBC_OBJ_08_DISTANCE 1;
BA_ "GenSigSendType" SG_ 1935 VIS_AHBC_OBJ_07_VERTICAL_POS 1;
BA_ "GenSigVtEn" SG_ 1935 VIS_AHBC_OBJ_07_TYPE "TRUE";
BA_ "GenSigVtName" SG_ 1935 VIS_AHBC_OBJ_07_TYPE "VtSig_VIS_AHBC_OBJ_07_TYPE";
BA_ "GenSigSendType" SG_ 1935 VIS_AHBC_OBJ_07_TYPE 1;
BA_ "GenSigSendType" SG_ 1935 VIS_AHBC_OBJ_07_ID 1;
BA_ "GenSigSendType" SG_ 1935 VIS_AHBC_OBJ_07_HORIZONTAL_POS 1;
BA_ "GenSigSendType" SG_ 1935 VIS_AHBC_OBJ_07_HORIZONTAL_DIM 1;
BA_ "GenSigVtEn" SG_ 1935 VIS_AHBC_OBJ_07_DISTANCE "TRUE";
BA_ "GenSigVtName" SG_ 1935 VIS_AHBC_OBJ_07_DISTANCE "VtSig_VIS_AHBC_OBJ_07_DISTANCE";
BA_ "GenSigSendType" SG_ 1935 VIS_AHBC_OBJ_07_DISTANCE 1;
BA_ "GenSigSendType" SG_ 1934 VIS_AHBC_OBJ_06_VERTICAL_POS 1;
BA_ "GenSigVtEn" SG_ 1934 VIS_AHBC_OBJ_06_TYPE "TRUE";
BA_ "GenSigVtName" SG_ 1934 VIS_AHBC_OBJ_06_TYPE "VtSig_VIS_AHBC_OBJ_06_TYPE";
BA_ "GenSigSendType" SG_ 1934 VIS_AHBC_OBJ_06_TYPE 1;
BA_ "GenSigSendType" SG_ 1934 VIS_AHBC_OBJ_06_ID 1;
BA_ "GenSigSendType" SG_ 1934 VIS_AHBC_OBJ_06_HORIZONTAL_POS 1;
BA_ "GenSigSendType" SG_ 1934 VIS_AHBC_OBJ_06_HORIZONTAL_DIM 1;
BA_ "GenSigVtEn" SG_ 1934 VIS_AHBC_OBJ_06_DISTANCE "TRUE";
BA_ "GenSigVtName" SG_ 1934 VIS_AHBC_OBJ_06_DISTANCE "VtSig_VIS_AHBC_OBJ_06_DISTANCE";
BA_ "GenSigSendType" SG_ 1934 VIS_AHBC_OBJ_06_DISTANCE 1;
BA_ "GenSigSendType" SG_ 1933 VIS_AHBC_OBJ_05_VERTICAL_POS 1;
BA_ "GenSigVtEn" SG_ 1933 VIS_AHBC_OBJ_05_TYPE "TRUE";
BA_ "GenSigVtName" SG_ 1933 VIS_AHBC_OBJ_05_TYPE "VtSig_VIS_AHBC_OBJ_05_TYPE";
BA_ "GenSigSendType" SG_ 1933 VIS_AHBC_OBJ_05_TYPE 1;
BA_ "GenSigSendType" SG_ 1933 VIS_AHBC_OBJ_05_ID 1;
BA_ "GenSigSendType" SG_ 1933 VIS_AHBC_OBJ_05_HORIZONTAL_POS 1;
BA_ "GenSigSendType" SG_ 1933 VIS_AHBC_OBJ_05_HORIZONTAL_DIM 1;
BA_ "GenSigVtEn" SG_ 1933 VIS_AHBC_OBJ_05_DISTANCE "TRUE";
BA_ "GenSigVtName" SG_ 1933 VIS_AHBC_OBJ_05_DISTANCE "VtSig_VIS_AHBC_OBJ_05_DISTANCE";
BA_ "GenSigSendType" SG_ 1933 VIS_AHBC_OBJ_05_DISTANCE 1;
BA_ "GenSigSendType" SG_ 1932 VIS_AHBC_OBJ_04_VERTICAL_POS 1;
BA_ "GenSigVtEn" SG_ 1932 VIS_AHBC_OBJ_04_TYPE "TRUE";
BA_ "GenSigVtName" SG_ 1932 VIS_AHBC_OBJ_04_TYPE "VtSig_VIS_AHBC_OBJ_04_TYPE";
BA_ "GenSigSendType" SG_ 1932 VIS_AHBC_OBJ_04_TYPE 1;
BA_ "GenSigSendType" SG_ 1932 VIS_AHBC_OBJ_04_ID 1;
BA_ "GenSigSendType" SG_ 1932 VIS_AHBC_OBJ_04_HORIZONTAL_POS 1;
BA_ "GenSigSendType" SG_ 1932 VIS_AHBC_OBJ_04_HORIZONTAL_DIM 1;
BA_ "GenSigVtEn" SG_ 1932 VIS_AHBC_OBJ_04_DISTANCE "TRUE";
BA_ "GenSigVtName" SG_ 1932 VIS_AHBC_OBJ_04_DISTANCE "VtSig_VIS_AHBC_OBJ_04_DISTANCE";
BA_ "GenSigSendType" SG_ 1932 VIS_AHBC_OBJ_04_DISTANCE 1;
BA_ "GenSigSendType" SG_ 1931 VIS_AHBC_OBJ_03_VERTICAL_POS 1;
BA_ "GenSigVtEn" SG_ 1931 VIS_AHBC_OBJ_03_TYPE "TRUE";
BA_ "GenSigVtName" SG_ 1931 VIS_AHBC_OBJ_03_TYPE "VtSig_VIS_AHBC_OBJ_03_TYPE";
BA_ "GenSigSendType" SG_ 1931 VIS_AHBC_OBJ_03_TYPE 1;
BA_ "GenSigSendType" SG_ 1931 VIS_AHBC_OBJ_03_ID 1;
BA_ "GenSigSendType" SG_ 1931 VIS_AHBC_OBJ_03_HORIZONTAL_POS 1;
BA_ "GenSigSendType" SG_ 1931 VIS_AHBC_OBJ_03_HORIZONTAL_DIM 1;
BA_ "GenSigVtEn" SG_ 1931 VIS_AHBC_OBJ_03_DISTANCE "TRUE";
BA_ "GenSigVtName" SG_ 1931 VIS_AHBC_OBJ_03_DISTANCE "VtSig_VIS_AHBC_OBJ_3_DISTANCE";
BA_ "GenSigSendType" SG_ 1931 VIS_AHBC_OBJ_03_DISTANCE 1;
BA_ "GenSigSendType" SG_ 1930 VIS_AHBC_OBJ_02_VERTICAL_POS 1;
BA_ "GenSigVtEn" SG_ 1930 VIS_AHBC_OBJ_02_TYPE "TRUE";
BA_ "GenSigVtName" SG_ 1930 VIS_AHBC_OBJ_02_TYPE "VtSig_VIS_AHBC_OBJ_02_TYPE";
BA_ "GenSigSendType" SG_ 1930 VIS_AHBC_OBJ_02_TYPE 1;
BA_ "GenSigSendType" SG_ 1930 VIS_AHBC_OBJ_02_ID 1;
BA_ "GenSigSendType" SG_ 1930 VIS_AHBC_OBJ_02_HORIZONTAL_POS 1;
BA_ "GenSigSendType" SG_ 1930 VIS_AHBC_OBJ_02_HORIZONTAL_DIM 1;
BA_ "GenSigVtEn" SG_ 1930 VIS_AHBC_OBJ_02_DISTANCE "TRUE";
BA_ "GenSigVtName" SG_ 1930 VIS_AHBC_OBJ_02_DISTANCE "VtSig_VIS_AHBC_OBJ_02_DISTANCE";
BA_ "GenSigSendType" SG_ 1930 VIS_AHBC_OBJ_02_DISTANCE 1;
BA_ "GenSigSendType" SG_ 1929 VIS_AHBC_OBJ_01_VERTICAL_POS 1;
BA_ "GenSigVtEn" SG_ 1929 VIS_AHBC_OBJ_01_TYPE "TRUE";
BA_ "GenSigVtName" SG_ 1929 VIS_AHBC_OBJ_01_TYPE "VtSig_VIS_AHBC_OBJ_01_TYPE";
BA_ "GenSigSendType" SG_ 1929 VIS_AHBC_OBJ_01_TYPE 1;
BA_ "GenSigSendType" SG_ 1929 VIS_AHBC_OBJ_01_ID 1;
BA_ "GenSigSendType" SG_ 1929 VIS_AHBC_OBJ_01_HORIZONTAL_POS 1;
BA_ "GenSigSendType" SG_ 1929 VIS_AHBC_OBJ_01_HORIZONTAL_DIM 1;
BA_ "GenSigVtEn" SG_ 1929 VIS_AHBC_OBJ_01_DISTANCE "TRUE";
BA_ "GenSigVtName" SG_ 1929 VIS_AHBC_OBJ_01_DISTANCE "VtSig_VIS_AHBC_OBJ_01_DISTANCE";
BA_ "GenSigSendType" SG_ 1929 VIS_AHBC_OBJ_01_DISTANCE 1;
BA_ "GenSigVtEn" SG_ 1709 VIS_LANE_RIGHT_PARALL_STATUS "TRUE";
BA_ "GenSigVtName" SG_ 1709 VIS_LANE_RIGHT_PARALL_STATUS "VtSig_VIS_LANE_RIGHT_PARALL_STATUS";
BA_ "GenSigSendType" SG_ 1709 VIS_LANE_RIGHT_PARALL_STATUS 1;
BA_ "GenSigVtEn" SG_ 1709 VIS_LANE_RIGHT_INDIVID_STATUS "TRUE";
BA_ "GenSigVtName" SG_ 1709 VIS_LANE_RIGHT_INDIVID_STATUS "VtSig_VIS_LANE_RIGHT_INIDIV_STATUS";
BA_ "GenSigSendType" SG_ 1709 VIS_LANE_RIGHT_INDIVID_STATUS 1;
BA_ "GenSigVtEn" SG_ 1709 VIS_LANE_LEFT_PARALL_STATUS "TRUE";
BA_ "GenSigVtName" SG_ 1709 VIS_LANE_LEFT_PARALL_STATUS "VtSig_VIS_LANE_LEFT_PARALL_STATUS";
BA_ "GenSigSendType" SG_ 1709 VIS_LANE_LEFT_PARALL_STATUS 1;
BA_ "GenSigVtEn" SG_ 1709 VIS_LANE_LEFT_INDIVID_STATUS "TRUE";
BA_ "GenSigVtName" SG_ 1709 VIS_LANE_LEFT_INDIVID_STATUS "VtSig_VIS_LANE_LEFT_INDIVID_STATUS";
BA_ "GenSigSendType" SG_ 1709 VIS_LANE_LEFT_INDIVID_STATUS 1;
BA_ "GenSigSendType" SG_ 1709 VIS_PREDICTION_INFORMATION_R 1;
BA_ "GenSigSendType" SG_ 1709 VIS_PREDICTION_INFORMATION_L 1;
BA_ "GenSigSendType" SG_ 1701 VIS_CENTER_POLYNOMIAL_WIDTH 1;
BA_ "GenSigSendType" SG_ 1701 VIS_CENTER_POLYNOMIAL_A3 1;
BA_ "GenSigSendType" SG_ 1701 VIS_CENTER_POLYNOMIAL_A2 1;
BA_ "GenSigVtEn" SG_ 1701 VIS_CENTER_POLYNOMIAL_LINECASE "TRUE";
BA_ "GenSigVtName" SG_ 1701 VIS_CENTER_POLYNOMIAL_LINECASE "VtSig_VIS_CENTER_POLYNOMIAL_LINECASE";
BA_ "GenSigSendType" SG_ 1701 VIS_CENTER_POLYNOMIAL_LINECASE 1;
BA_ "GenSigSendType" SG_ 1701 VIS_CENTER_POLYNOMIAL_A1 1;
BA_ "GenSigSendType" SG_ 1701 VIS_CENTER_POLYNOMIAL_A0 1;
BA_ "GenSigVtEn" SG_ 1701 VIS_CENTER_POLYNOMIAL_LANECONF "TRUE";
BA_ "GenSigVtName" SG_ 1701 VIS_CENTER_POLYNOMIAL_LANECONF "VtSig_VIS_CENTER_POLYNOMIAL_LANECONF";
BA_ "GenSigSendType" SG_ 1701 VIS_CENTER_POLYNOMIAL_LANECONF 1;
BA_ "GenSigStartValue" SG_ 1655 VIS_OBS_LONG_VEL_15 2048;
BA_ "GenSigStartValue" SG_ 1655 VIS_OBS_LONG_VEL_14 2048;
BA_ "GenSigStartValue" SG_ 1655 VIS_OBS_LONG_VEL_13 2048;
BA_ "GenSigStartValue" SG_ 1655 VIS_OBS_LONG_VEL_12 2048;
BA_ "GenSigStartValue" SG_ 1655 VIS_OBS_LONG_VEL_11 2048;
BA_ "GenSigStartValue" SG_ 1655 VIS_OBS_LONG_VEL_10 2048;
BA_ "GenSigStartValue" SG_ 1655 VIS_OBS_LONG_VEL_09 2048;
BA_ "GenSigStartValue" SG_ 1655 VIS_OBS_LONG_VEL_08 2048;
BA_ "GenSigStartValue" SG_ 1655 VIS_OBS_LONG_VEL_07 2048;
BA_ "GenSigStartValue" SG_ 1655 VIS_OBS_LONG_VEL_06 2048;
BA_ "GenSigStartValue" SG_ 1655 VIS_OBS_LONG_VEL_05 2048;
BA_ "GenSigStartValue" SG_ 1655 VIS_OBS_LONG_VEL_04 2048;
BA_ "GenSigStartValue" SG_ 1655 VIS_OBS_LONG_VEL_03 2048;
BA_ "GenSigStartValue" SG_ 1655 VIS_OBS_LONG_VEL_02 2048;
BA_ "GenSigStartValue" SG_ 1655 VIS_OBS_LAT_VEL_15 2048;
BA_ "GenSigStartValue" SG_ 1655 VIS_OBS_LAT_VEL_14 2048;
BA_ "GenSigStartValue" SG_ 1655 VIS_OBS_LAT_VEL_13 2048;
BA_ "GenSigStartValue" SG_ 1655 VIS_OBS_LAT_VEL_12 2048;
BA_ "GenSigStartValue" SG_ 1655 VIS_OBS_LAT_VEL_11 2048;
BA_ "GenSigStartValue" SG_ 1655 VIS_OBS_LAT_VEL_10 2048;
BA_ "GenSigStartValue" SG_ 1655 VIS_OBS_LAT_VEL_09 2048;
BA_ "GenSigStartValue" SG_ 1655 VIS_OBS_LAT_VEL_08 2048;
BA_ "GenSigStartValue" SG_ 1655 VIS_OBS_LAT_VEL_07 2048;
BA_ "GenSigStartValue" SG_ 1655 VIS_OBS_LAT_VEL_06 2048;
BA_ "GenSigStartValue" SG_ 1655 VIS_OBS_LAT_VEL_05 2048;
BA_ "GenSigStartValue" SG_ 1655 VIS_OBS_LAT_VEL_04 2048;
BA_ "GenSigStartValue" SG_ 1655 VIS_OBS_LAT_VEL_03 2048;
BA_ "GenSigStartValue" SG_ 1655 VIS_OBS_LAT_VEL_02 2048;
BA_ "GenSigStartValue" SG_ 1655 VIS_OBS_LAT_POS_15 2048;
BA_ "GenSigStartValue" SG_ 1655 VIS_OBS_LAT_POS_14 2048;
BA_ "GenSigStartValue" SG_ 1655 VIS_OBS_LAT_POS_13 2048;
BA_ "GenSigStartValue" SG_ 1655 VIS_OBS_LAT_POS_12 2048;
BA_ "GenSigStartValue" SG_ 1655 VIS_OBS_LAT_POS_11 2048;
BA_ "GenSigStartValue" SG_ 1655 VIS_OBS_LAT_POS_10 2048;
BA_ "GenSigStartValue" SG_ 1655 VIS_OBS_LAT_POS_09 2048;
BA_ "GenSigStartValue" SG_ 1655 VIS_OBS_LAT_POS_08 2048;
BA_ "GenSigStartValue" SG_ 1655 VIS_OBS_LAT_POS_07 2048;
BA_ "GenSigStartValue" SG_ 1655 VIS_OBS_LAT_POS_06 2048;
BA_ "GenSigStartValue" SG_ 1655 VIS_OBS_LAT_POS_05 2048;
BA_ "GenSigStartValue" SG_ 1655 VIS_OBS_LAT_POS_04 2048;
BA_ "GenSigStartValue" SG_ 1655 VIS_OBS_LAT_POS_03 2048;
BA_ "GenSigStartValue" SG_ 1655 VIS_OBS_LAT_POS_02 2048;
BA_ "GenSigStartValue" SG_ 1655 VIS_OBS_LONG_VEL_01 2048;
BA_ "GenSigStartValue" SG_ 1655 VIS_OBS_LAT_VEL_01 2048;
BA_ "GenSigStartValue" SG_ 1655 VIS_OBS_LAT_POS_01 2048;
BA_ "GenSigSendType" SG_ 1702 VIS_LANE_RIGHT_PARALL_RANGE 1;
BA_ "GenSigSendType" SG_ 1702 VIS_LANE_RIGHT_PARALL_A3 1;
BA_ "GenSigSendType" SG_ 1702 VIS_LANE_RIGHT_PARALL_A2 1;
BA_ "GenSigSendType" SG_ 1702 VIS_LANE_RIGHT_PARALL_A1 1;
BA_ "GenSigSendType" SG_ 1702 VIS_LANE_RIGHT_PARALL_A0 1;
BA_ "GenSigVtEn" SG_ 1702 VIS_LANE_RIGHT_PA_MARKER_COLOR "TRUE";
BA_ "GenSigVtName" SG_ 1702 VIS_LANE_RIGHT_PA_MARKER_COLOR "VtSig_VIS_LANE_RIGHT_PA_MARKER_COLOR";
BA_ "GenSigSendType" SG_ 1702 VIS_LANE_RIGHT_PA_MARKER_COLOR 1;
BA_ "GenSigSendType" SG_ 1707 VIS_LANE_RIGHT_INDIVID_RANGE 1;
BA_ "GenSigSendType" SG_ 1707 VIS_LANE_RIGHT_INDIVID_A3 1;
BA_ "GenSigSendType" SG_ 1707 VIS_LANE_RIGHT_INDIVID_A2 1;
BA_ "GenSigSendType" SG_ 1707 VIS_LANE_RIGHT_INDIVID_A1 1;
BA_ "GenSigSendType" SG_ 1707 VIS_LANE_RIGHT_INDIVID_A0 1;
BA_ "GenSigVtEn" SG_ 1707 VIS_LANE_RIGHT_IN_MARKER_COLOR "TRUE";
BA_ "GenSigVtName" SG_ 1707 VIS_LANE_RIGHT_IN_MARKER_COLOR "VtSig_VIS_LANE_RIGHT_IN_MARKER_COLOR";
BA_ "GenSigSendType" SG_ 1707 VIS_LANE_RIGHT_IN_MARKER_COLOR 1;
BA_ "GenSigSendType" SG_ 1703 VIS_LANE_LEFT_PARALL_RANGE 1;
BA_ "GenSigSendType" SG_ 1703 VIS_LANE_LEFT_PARALL_A3 1;
BA_ "GenSigSendType" SG_ 1703 VIS_LANE_LEFT_PARALL_A2 1;
BA_ "GenSigSendType" SG_ 1703 VIS_LANE_LEFT_PARALL_A1 1;
BA_ "GenSigSendType" SG_ 1703 VIS_LANE_LEFT_PARALL_A0 1;
BA_ "GenSigVtEn" SG_ 1703 VIS_LANE_LEFT_PA_MARKER_COLOR "TRUE";
BA_ "GenSigVtName" SG_ 1703 VIS_LANE_LEFT_PA_MARKER_COLOR "VtSig_VIS_LANE_LEFT_PA_MARKER_COLOR";
BA_ "GenSigSendType" SG_ 1703 VIS_LANE_LEFT_PA_MARKER_COLOR 1;
BA_ "GenSigSendType" SG_ 1708 VIS_LANE_LEFT_INDIVID_RANGE 1;
BA_ "GenSigSendType" SG_ 1708 VIS_LANE_LEFT_INDIVID_A3 1;
BA_ "GenSigSendType" SG_ 1708 VIS_LANE_LEFT_INDIVID_A2 1;
BA_ "GenSigSendType" SG_ 1708 VIS_LANE_LEFT_INDIVID_A1 1;
BA_ "GenSigSendType" SG_ 1708 VIS_LANE_LEFT_INDIVID_A0 1;
BA_ "GenSigVtEn" SG_ 1708 VIS_LANE_LEFT_IN_MARKER_COLOR "TRUE";
BA_ "GenSigVtName" SG_ 1708 VIS_LANE_LEFT_IN_MARKER_COLOR "VtSig_VIS_LANE_LEFT_IN_MARKER_COLOR";
BA_ "GenSigSendType" SG_ 1708 VIS_LANE_LEFT_IN_MARKER_COLOR 1;
BA_ "GenSigSendType" SG_ 1687 SIGN_8_VIS_TSR_RELEVANT 1;
BA_ "GenSigVtEn" SG_ 1687 SIGN_8_VIS_TSR_RELEVANT_DECISION "TRUE";
BA_ "GenSigVtName" SG_ 1687 SIGN_8_VIS_TSR_RELEVANT_DECISION "VtSig_SIGN_8_VIS_TRS_RELEVANT_DECISION";
BA_ "GenSigSendType" SG_ 1687 SIGN_8_VIS_TSR_RELEVANT_DECISION 1;
BA_ "GenSigVtEn" SG_ 1687 SIGN_8_VIS_TSR_LOCATION "TRUE";
BA_ "GenSigVtName" SG_ 1687 SIGN_8_VIS_TSR_LOCATION "VtSig_SIGN_8_VIS_TSR_LOCATION";
BA_ "GenSigSendType" SG_ 1687 SIGN_8_VIS_TSR_LOCATION 1;
BA_ "GenSigSendType" SG_ 1687 SIGN_8_VIS_TSR_SIGN_EMBEDDED 1;
BA_ "GenSigSendType" SG_ 1687 SIGN_8_VIS_TSR_POSITION_LATERAL 1;
BA_ "GenSigVtEn" SG_ 1687 SIGN_8_VIS_TSR_SUPPL_TYPE_1ST "TRUE";
BA_ "GenSigVtName" SG_ 1687 SIGN_8_VIS_TSR_SUPPL_TYPE_1ST "VtSig_SIGN_8_VIS_TSR_SUPPL_TYPE_1ST";
BA_ "GenSigSendType" SG_ 1687 SIGN_8_VIS_TSR_SUPPL_TYPE_1ST 1;
BA_ "GenSigSendType" SG_ 1687 SIGN_8_VIS_TSR_ID 1;
BA_ "GenSigSendType" SG_ 1687 SIGN_8_VIS_TSR_SIGN_VALUE 1;
BA_ "GenSigSendType" SG_ 1687 SIGN_8_VIS_TSR_CONFIDENCE 1;
BA_ "GenSigVtEn" SG_ 1687 SIGN_8_VIS_TSR_STATUS "TRUE";
BA_ "GenSigVtName" SG_ 1687 SIGN_8_VIS_TSR_STATUS "VtSig_SIGN_8_VIS_TSR_STATUS";
BA_ "GenSigSendType" SG_ 1687 SIGN_8_VIS_TSR_STATUS 1;
BA_ "GenSigVtEn" SG_ 1687 SIGN_8_VIS_TSR_SUPPL_TYPE_2ND "TRUE";
BA_ "GenSigVtName" SG_ 1687 SIGN_8_VIS_TSR_SUPPL_TYPE_2ND "VtSig_SIGN_8_VIS_TSR_SUPPL_TYPE_2ND";
BA_ "GenSigSendType" SG_ 1687 SIGN_8_VIS_TSR_SUPPL_TYPE_2ND 1;
BA_ "GenSigSendType" SG_ 1687 SIGN_8_VIS_TSR_LOCATION_LANE 1;
BA_ "GenSigVtEn" SG_ 1687 SIGN_8_VIS_TSR_ELECTRONIC_SIGN "TRUE";
BA_ "GenSigVtName" SG_ 1687 SIGN_8_VIS_TSR_ELECTRONIC_SIGN "VtSig_SIGN_8_VIS_TSR_ELECTRONIC_SIGN";
BA_ "GenSigSendType" SG_ 1687 SIGN_8_VIS_TSR_ELECTRONIC_SIGN 1;
BA_ "GenSigVtEn" SG_ 1687 SIGN_8_VIS_TSR_TYPE "TRUE";
BA_ "GenSigVtName" SG_ 1687 SIGN_8_VIS_TSR_TYPE "VtSig_SIGN_8_VIS_TSR_TYPE";
BA_ "GenSigSendType" SG_ 1687 SIGN_8_VIS_TSR_TYPE 1;
BA_ "GenSigSendType" SG_ 1686 SIGN_7_VIS_TSR_RELEVANT 1;
BA_ "GenSigVtEn" SG_ 1686 SIGN_7_VIS_TSR_RELEVANT_DECISION "TRUE";
BA_ "GenSigVtName" SG_ 1686 SIGN_7_VIS_TSR_RELEVANT_DECISION "VtSig_SIGN_7_VIS_TRS_RELEVANT_DECISION";
BA_ "GenSigSendType" SG_ 1686 SIGN_7_VIS_TSR_RELEVANT_DECISION 1;
BA_ "GenSigVtEn" SG_ 1686 SIGN_7_VIS_TSR_LOCATION "TRUE";
BA_ "GenSigVtName" SG_ 1686 SIGN_7_VIS_TSR_LOCATION "VtSig_SIGN_7_VIS_TSR_LOCATION";
BA_ "GenSigSendType" SG_ 1686 SIGN_7_VIS_TSR_LOCATION 1;
BA_ "GenSigSendType" SG_ 1686 SIGN_7_VIS_TSR_SIGN_EMBEDDED 1;
BA_ "GenSigSendType" SG_ 1686 SIGN_7_VIS_TSR_POSITION_LATERAL 1;
BA_ "GenSigVtEn" SG_ 1686 SIGN_7_VIS_TSR_SUPPL_TYPE_1ST "TRUE";
BA_ "GenSigVtName" SG_ 1686 SIGN_7_VIS_TSR_SUPPL_TYPE_1ST "VtSig_SIGN_7_VIS_TSR_SUPPL_TYPE_1ST";
BA_ "GenSigSendType" SG_ 1686 SIGN_7_VIS_TSR_SUPPL_TYPE_1ST 1;
BA_ "GenSigSendType" SG_ 1686 SIGN_7_VIS_TSR_ID 1;
BA_ "GenSigSendType" SG_ 1686 SIGN_7_VIS_TSR_SIGN_VALUE 1;
BA_ "GenSigSendType" SG_ 1686 SIGN_7_VIS_TSR_CONFIDENCE 1;
BA_ "GenSigVtEn" SG_ 1686 SIGN_7_VIS_TSR_STATUS "TRUE";
BA_ "GenSigVtName" SG_ 1686 SIGN_7_VIS_TSR_STATUS "VtSig_SIGN_7_VIS_TSR_STATUS";
BA_ "GenSigSendType" SG_ 1686 SIGN_7_VIS_TSR_STATUS 1;
BA_ "GenSigVtEn" SG_ 1686 SIGN_7_VIS_TSR_SUPPL_TYPE_2ND "TRUE";
BA_ "GenSigVtName" SG_ 1686 SIGN_7_VIS_TSR_SUPPL_TYPE_2ND "VtSig_SIGN_7_VIS_TSR_SUPPL_TYPE_2ND";
BA_ "GenSigSendType" SG_ 1686 SIGN_7_VIS_TSR_SUPPL_TYPE_2ND 1;
BA_ "GenSigSendType" SG_ 1686 SIGN_7_VIS_TSR_LOCATION_LANE 1;
BA_ "GenSigVtEn" SG_ 1686 SIGN_7_VIS_TSR_ELECTRONIC_SIGN "TRUE";
BA_ "GenSigVtName" SG_ 1686 SIGN_7_VIS_TSR_ELECTRONIC_SIGN "VtSig_SIGN_7_VIS_TSR_ELECTRONIC_SIGN";
BA_ "GenSigSendType" SG_ 1686 SIGN_7_VIS_TSR_ELECTRONIC_SIGN 1;
BA_ "GenSigVtEn" SG_ 1686 SIGN_7_VIS_TSR_TYPE "TRUE";
BA_ "GenSigVtName" SG_ 1686 SIGN_7_VIS_TSR_TYPE "VtSig_SIGN_7_VIS_TSR_TYPE";
BA_ "GenSigSendType" SG_ 1686 SIGN_7_VIS_TSR_TYPE 1;
BA_ "GenSigSendType" SG_ 1685 SIGN_6_VIS_TSR_RELEVANT 1;
BA_ "GenSigVtEn" SG_ 1685 SIGN_6_VIS_TSR_RELEVANT_DECISION "TRUE";
BA_ "GenSigVtName" SG_ 1685 SIGN_6_VIS_TSR_RELEVANT_DECISION "VtSig_SIGN_6_VIS_TRS_RELEVANT_DECISION";
BA_ "GenSigSendType" SG_ 1685 SIGN_6_VIS_TSR_RELEVANT_DECISION 1;
BA_ "GenSigVtEn" SG_ 1685 SIGN_6_VIS_TSR_LOCATION "TRUE";
BA_ "GenSigVtName" SG_ 1685 SIGN_6_VIS_TSR_LOCATION "VtSig_SIGN_6_VIS_TSR_LOCATION";
BA_ "GenSigSendType" SG_ 1685 SIGN_6_VIS_TSR_LOCATION 1;
BA_ "GenSigSendType" SG_ 1685 SIGN_6_VIS_TSR_SIGN_EMBEDDED 1;
BA_ "GenSigSendType" SG_ 1685 SIGN_6_VIS_TSR_POSITION_LATERAL 1;
BA_ "GenSigVtEn" SG_ 1685 SIGN_6_VIS_TSR_SUPPL_TYPE_1ST "TRUE";
BA_ "GenSigVtName" SG_ 1685 SIGN_6_VIS_TSR_SUPPL_TYPE_1ST "VtSig_SIGN_6_VIS_TSR_SUPPL_TYPE_1ST";
BA_ "GenSigSendType" SG_ 1685 SIGN_6_VIS_TSR_SUPPL_TYPE_1ST 1;
BA_ "GenSigSendType" SG_ 1685 SIGN_6_VIS_TSR_ID 1;
BA_ "GenSigSendType" SG_ 1685 SIGN_6_VIS_TSR_SIGN_VALUE 1;
BA_ "GenSigSendType" SG_ 1685 SIGN_6_VIS_TSR_CONFIDENCE 1;
BA_ "GenSigVtEn" SG_ 1685 SIGN_6_VIS_TSR_STATUS "TRUE";
BA_ "GenSigVtName" SG_ 1685 SIGN_6_VIS_TSR_STATUS "VtSig_SIGN_6_VIS_TSR_STATUS";
BA_ "GenSigSendType" SG_ 1685 SIGN_6_VIS_TSR_STATUS 1;
BA_ "GenSigVtEn" SG_ 1685 SIGN_6_VIS_TSR_SUPPL_TYPE_2ND "TRUE";
BA_ "GenSigVtName" SG_ 1685 SIGN_6_VIS_TSR_SUPPL_TYPE_2ND "VtSig_SIGN_6_VIS_TSR_SUPPL_TYPE_2ND";
BA_ "GenSigSendType" SG_ 1685 SIGN_6_VIS_TSR_SUPPL_TYPE_2ND 1;
BA_ "GenSigSendType" SG_ 1685 SIGN_6_VIS_TSR_LOCATION_LANE 1;
BA_ "GenSigVtEn" SG_ 1685 SIGN_6_VIS_TSR_ELECTRONIC_SIGN "TRUE";
BA_ "GenSigVtName" SG_ 1685 SIGN_6_VIS_TSR_ELECTRONIC_SIGN "VtSig_SIGN_6_VIS_TSR_ELECTRONIC_SIGN";
BA_ "GenSigSendType" SG_ 1685 SIGN_6_VIS_TSR_ELECTRONIC_SIGN 1;
BA_ "GenSigVtEn" SG_ 1685 SIGN_6_VIS_TSR_TYPE "TRUE";
BA_ "GenSigVtName" SG_ 1685 SIGN_6_VIS_TSR_TYPE "VtSig_SIGN_6_VIS_TSR_TYPE";
BA_ "GenSigSendType" SG_ 1685 SIGN_6_VIS_TSR_TYPE 1;
BA_ "GenSigSendType" SG_ 1684 SIGN_5_VIS_TSR_RELEVANT 1;
BA_ "GenSigVtEn" SG_ 1684 SIGN_5_VIS_TSR_RELEVANT_DECISION "TRUE";
BA_ "GenSigVtName" SG_ 1684 SIGN_5_VIS_TSR_RELEVANT_DECISION "VtSig_SIGN_5_VIS_TRS_RELEVANT_DECISION";
BA_ "GenSigSendType" SG_ 1684 SIGN_5_VIS_TSR_RELEVANT_DECISION 1;
BA_ "GenSigVtEn" SG_ 1684 SIGN_5_VIS_TSR_LOCATION "TRUE";
BA_ "GenSigVtName" SG_ 1684 SIGN_5_VIS_TSR_LOCATION "VtSig_SIGN_5_VIS_TSR_LOCATION";
BA_ "GenSigSendType" SG_ 1684 SIGN_5_VIS_TSR_LOCATION 1;
BA_ "GenSigSendType" SG_ 1684 SIGN_5_VIS_TSR_SIGN_EMBEDDED 1;
BA_ "GenSigSendType" SG_ 1684 SIGN_5_VIS_TSR_POSITION_LATERAL 1;
BA_ "GenSigVtEn" SG_ 1684 SIGN_5_VIS_TSR_SUPPL_TYPE_1ST "TRUE";
BA_ "GenSigVtName" SG_ 1684 SIGN_5_VIS_TSR_SUPPL_TYPE_1ST "VtSig_SIGN_5_VIS_TSR_SUPPL_TYPE_1ST";
BA_ "GenSigSendType" SG_ 1684 SIGN_5_VIS_TSR_SUPPL_TYPE_1ST 1;
BA_ "GenSigSendType" SG_ 1684 SIGN_5_VIS_TSR_ID 1;
BA_ "GenSigSendType" SG_ 1684 SIGN_5_VIS_TSR_SIGN_VALUE 1;
BA_ "GenSigSendType" SG_ 1684 SIGN_5_VIS_TSR_CONFIDENCE 1;
BA_ "GenSigVtEn" SG_ 1684 SIGN_5_VIS_TSR_STATUS "TRUE";
BA_ "GenSigVtName" SG_ 1684 SIGN_5_VIS_TSR_STATUS "VtSig_SIGN_5_VIS_TSR_STATUS";
BA_ "GenSigSendType" SG_ 1684 SIGN_5_VIS_TSR_STATUS 1;
BA_ "GenSigVtEn" SG_ 1684 SIGN_5_VIS_TSR_SUPPL_TYPE_2ND "TRUE";
BA_ "GenSigVtName" SG_ 1684 SIGN_5_VIS_TSR_SUPPL_TYPE_2ND "VtSig_SIGN_5_VIS_TSR_SUPPL_TYPE_2ND";
BA_ "GenSigSendType" SG_ 1684 SIGN_5_VIS_TSR_SUPPL_TYPE_2ND 1;
BA_ "GenSigSendType" SG_ 1684 SIGN_5_VIS_TSR_LOCATION_LANE 1;
BA_ "GenSigVtEn" SG_ 1684 SIGN_5_VIS_TSR_ELECTRONIC_SIGN "TRUE";
BA_ "GenSigVtName" SG_ 1684 SIGN_5_VIS_TSR_ELECTRONIC_SIGN "VtSig_SIGN_5_VIS_TSR_ELECTRONIC_SIGN";
BA_ "GenSigSendType" SG_ 1684 SIGN_5_VIS_TSR_ELECTRONIC_SIGN 1;
BA_ "GenSigVtEn" SG_ 1684 SIGN_5_VIS_TSR_TYPE "TRUE";
BA_ "GenSigVtName" SG_ 1684 SIGN_5_VIS_TSR_TYPE "VtSig_SIGN_5_VIS_TSR_TYPE";
BA_ "GenSigSendType" SG_ 1684 SIGN_5_VIS_TSR_TYPE 1;
BA_ "GenSigSendType" SG_ 1683 SIGN_4_VIS_TSR_RELEVANT 1;
BA_ "GenSigVtEn" SG_ 1683 SIGN_4_VIS_TSR_RELEVANT_DECISION "TRUE";
BA_ "GenSigVtName" SG_ 1683 SIGN_4_VIS_TSR_RELEVANT_DECISION "VtSig_SIGN_4_VIS_TRS_RELEVANT_DECISION";
BA_ "GenSigSendType" SG_ 1683 SIGN_4_VIS_TSR_RELEVANT_DECISION 1;
BA_ "GenSigVtEn" SG_ 1683 SIGN_4_VIS_TSR_LOCATION "TRUE";
BA_ "GenSigVtName" SG_ 1683 SIGN_4_VIS_TSR_LOCATION "VtSig_SIGN_4_VIS_TSR_LOCATION";
BA_ "GenSigSendType" SG_ 1683 SIGN_4_VIS_TSR_LOCATION 1;
BA_ "GenSigSendType" SG_ 1683 SIGN_4_VIS_TSR_SIGN_EMBEDDED 1;
BA_ "GenSigSendType" SG_ 1683 SIGN_4_VIS_TSR_POSITION_LATERAL 1;
BA_ "GenSigVtEn" SG_ 1683 SIGN_4_VIS_TSR_SUPPL_TYPE_1ST "TRUE";
BA_ "GenSigVtName" SG_ 1683 SIGN_4_VIS_TSR_SUPPL_TYPE_1ST "VtSig_SIGN_4_VIS_TSR_SUPPL_TYPE_1ST";
BA_ "GenSigSendType" SG_ 1683 SIGN_4_VIS_TSR_SUPPL_TYPE_1ST 1;
BA_ "GenSigSendType" SG_ 1683 SIGN_4_VIS_TSR_ID 1;
BA_ "GenSigSendType" SG_ 1683 SIGN_4_VIS_TSR_SIGN_VALUE 1;
BA_ "GenSigSendType" SG_ 1683 SIGN_4_VIS_TSR_CONFIDENCE 1;
BA_ "GenSigVtEn" SG_ 1683 SIGN_4_VIS_TSR_STATUS "TRUE";
BA_ "GenSigVtName" SG_ 1683 SIGN_4_VIS_TSR_STATUS "VtSig_SIGN_4_VIS_TSR_STATUS";
BA_ "GenSigSendType" SG_ 1683 SIGN_4_VIS_TSR_STATUS 1;
BA_ "GenSigVtEn" SG_ 1683 SIGN_4_VIS_TSR_SUPPL_TYPE_2ND "TRUE";
BA_ "GenSigVtName" SG_ 1683 SIGN_4_VIS_TSR_SUPPL_TYPE_2ND "VtSig_SIGN_4_VIS_TSR_SUPPL_TYPE_2ND";
BA_ "GenSigSendType" SG_ 1683 SIGN_4_VIS_TSR_SUPPL_TYPE_2ND 1;
BA_ "GenSigSendType" SG_ 1683 SIGN_4_VIS_TSR_LOCATION_LANE 1;
BA_ "GenSigVtEn" SG_ 1683 SIGN_4_VIS_TSR_ELECTRONIC_SIGN "TRUE";
BA_ "GenSigVtName" SG_ 1683 SIGN_4_VIS_TSR_ELECTRONIC_SIGN "VtSig_SIGN_4_VIS_TSR_ELECTRONIC_SIGN";
BA_ "GenSigSendType" SG_ 1683 SIGN_4_VIS_TSR_ELECTRONIC_SIGN 1;
BA_ "GenSigVtEn" SG_ 1683 SIGN_4_VIS_TSR_TYPE "TRUE";
BA_ "GenSigVtName" SG_ 1683 SIGN_4_VIS_TSR_TYPE "VtSig_SIGN_4_VIS_TSR_TYPE";
BA_ "GenSigSendType" SG_ 1683 SIGN_4_VIS_TSR_TYPE 1;
BA_ "GenSigSendType" SG_ 1682 SIGN_3_VIS_TSR_RELEVANT 1;
BA_ "GenSigVtEn" SG_ 1682 SIGN_3_VIS_TSR_RELEVANT_DECISION "TRUE";
BA_ "GenSigVtName" SG_ 1682 SIGN_3_VIS_TSR_RELEVANT_DECISION "VtSig_SIGN_3_VIS_TRS_RELEVANT_DECISION";
BA_ "GenSigSendType" SG_ 1682 SIGN_3_VIS_TSR_RELEVANT_DECISION 1;
BA_ "GenSigVtEn" SG_ 1682 SIGN_3_VIS_TSR_LOCATION "TRUE";
BA_ "GenSigVtName" SG_ 1682 SIGN_3_VIS_TSR_LOCATION "VtSig_SIGN_3_VIS_TSR_LOCATION";
BA_ "GenSigSendType" SG_ 1682 SIGN_3_VIS_TSR_LOCATION 1;
BA_ "GenSigSendType" SG_ 1682 SIGN_3_VIS_TSR_SIGN_EMBEDDED 1;
BA_ "GenSigSendType" SG_ 1682 SIGN_3_VIS_TSR_POSITION_LATERAL 1;
BA_ "GenSigVtEn" SG_ 1682 SIGN_3_VIS_TSR_SUPPL_TYPE_1ST "TRUE";
BA_ "GenSigVtName" SG_ 1682 SIGN_3_VIS_TSR_SUPPL_TYPE_1ST "VtSig_SIGN_3_VIS_TSR_SUPPL_TYPE_1ST";
BA_ "GenSigSendType" SG_ 1682 SIGN_3_VIS_TSR_SUPPL_TYPE_1ST 1;
BA_ "GenSigSendType" SG_ 1682 SIGN_3_VIS_TSR_ID 1;
BA_ "GenSigSendType" SG_ 1682 SIGN_3_VIS_TSR_SIGN_VALUE 1;
BA_ "GenSigSendType" SG_ 1682 SIGN_3_VIS_TSR_CONFIDENCE 1;
BA_ "GenSigVtEn" SG_ 1682 SIGN_3_VIS_TSR_STATUS "TRUE";
BA_ "GenSigVtName" SG_ 1682 SIGN_3_VIS_TSR_STATUS "VtSig_SIGN_3_VIS_TSR_STATUS";
BA_ "GenSigSendType" SG_ 1682 SIGN_3_VIS_TSR_STATUS 1;
BA_ "GenSigVtEn" SG_ 1682 SIGN_3_VIS_TSR_SUPPL_TYPE_2ND "TRUE";
BA_ "GenSigVtName" SG_ 1682 SIGN_3_VIS_TSR_SUPPL_TYPE_2ND "VtSig_SIGN_3_VIS_TSR_SUPPL_TYPE_2ND";
BA_ "GenSigSendType" SG_ 1682 SIGN_3_VIS_TSR_SUPPL_TYPE_2ND 1;
BA_ "GenSigSendType" SG_ 1682 SIGN_3_VIS_TSR_LOCATION_LANE 1;
BA_ "GenSigVtEn" SG_ 1682 SIGN_3_VIS_TSR_ELECTRONIC_SIGN "TRUE";
BA_ "GenSigVtName" SG_ 1682 SIGN_3_VIS_TSR_ELECTRONIC_SIGN "VtSig_SIGN_3_VIS_TSR_ELECTRONIC_SIGN";
BA_ "GenSigSendType" SG_ 1682 SIGN_3_VIS_TSR_ELECTRONIC_SIGN 1;
BA_ "GenSigVtEn" SG_ 1682 SIGN_3_VIS_TSR_TYPE "TRUE";
BA_ "GenSigVtName" SG_ 1682 SIGN_3_VIS_TSR_TYPE "VtSig_SIGN_3_VIS_TSR_TYPE";
BA_ "GenSigSendType" SG_ 1682 SIGN_3_VIS_TSR_TYPE 1;
BA_ "GenSigSendType" SG_ 1681 SIGN_2_VIS_TSR_RELEVANT 1;
BA_ "GenSigVtEn" SG_ 1681 SIGN_2_VIS_TSR_RELEVANT_DECISION "TRUE";
BA_ "GenSigVtName" SG_ 1681 SIGN_2_VIS_TSR_RELEVANT_DECISION "VtSig_SIGN_2_VIS_TRS_RELEVANT_DECISION";
BA_ "GenSigSendType" SG_ 1681 SIGN_2_VIS_TSR_RELEVANT_DECISION 1;
BA_ "GenSigVtEn" SG_ 1681 SIGN_2_VIS_TSR_LOCATION "TRUE";
BA_ "GenSigVtName" SG_ 1681 SIGN_2_VIS_TSR_LOCATION "VtSig_SIGN_2_VIS_TSR_LOCATION";
BA_ "GenSigSendType" SG_ 1681 SIGN_2_VIS_TSR_LOCATION 1;
BA_ "GenSigSendType" SG_ 1681 SIGN_2_VIS_TSR_SIGN_EMBEDDED 1;
BA_ "GenSigSendType" SG_ 1681 SIGN_2_VIS_TSR_POSITION_LATERAL 1;
BA_ "GenSigVtEn" SG_ 1681 SIGN_2_VIS_TSR_SUPPL_TYPE_1ST "TRUE";
BA_ "GenSigVtName" SG_ 1681 SIGN_2_VIS_TSR_SUPPL_TYPE_1ST "VtSig_SIGN_2_VIS_TSR_SUPPL_TYPE_1ST";
BA_ "GenSigSendType" SG_ 1681 SIGN_2_VIS_TSR_SUPPL_TYPE_1ST 1;
BA_ "GenSigSendType" SG_ 1681 SIGN_2_VIS_TSR_ID 1;
BA_ "GenSigSendType" SG_ 1681 SIGN_2_VIS_TSR_SIGN_VALUE 1;
BA_ "GenSigSendType" SG_ 1681 SIGN_2_VIS_TSR_CONFIDENCE 1;
BA_ "GenSigVtEn" SG_ 1681 SIGN_2_VIS_TSR_STATUS "TRUE";
BA_ "GenSigVtName" SG_ 1681 SIGN_2_VIS_TSR_STATUS "VtSig_SIGN_2_VIS_TSR_STATUS";
BA_ "GenSigSendType" SG_ 1681 SIGN_2_VIS_TSR_STATUS 1;
BA_ "GenSigVtEn" SG_ 1681 SIGN_2_VIS_TSR_SUPPL_TYPE_2ND "TRUE";
BA_ "GenSigVtName" SG_ 1681 SIGN_2_VIS_TSR_SUPPL_TYPE_2ND "VtSig_SIGN_2_VIS_TSR_SUPPL_TYPE_2ND";
BA_ "GenSigSendType" SG_ 1681 SIGN_2_VIS_TSR_SUPPL_TYPE_2ND 1;
BA_ "GenSigSendType" SG_ 1681 SIGN_2_VIS_TSR_LOCATION_LANE 1;
BA_ "GenSigVtEn" SG_ 1681 SIGN_2_VIS_TSR_ELECTRONIC_SIGN "TRUE";
BA_ "GenSigVtName" SG_ 1681 SIGN_2_VIS_TSR_ELECTRONIC_SIGN "VtSig_SIGN_2_VIS_TSR_ELECTRONIC_SIGN";
BA_ "GenSigSendType" SG_ 1681 SIGN_2_VIS_TSR_ELECTRONIC_SIGN 1;
BA_ "GenSigVtEn" SG_ 1681 SIGN_2_VIS_TSR_TYPE "TRUE";
BA_ "GenSigVtName" SG_ 1681 SIGN_2_VIS_TSR_TYPE "VtSig_SIGN_2_VIS_TSR_TYPE";
BA_ "GenSigSendType" SG_ 1681 SIGN_2_VIS_TSR_TYPE 1;
BA_ "GenSigSendType" SG_ 1680 SIGN_1_VIS_TSR_RELEVANT 1;
BA_ "GenSigVtEn" SG_ 1680 SIGN_1_VIS_TSR_RELEVANT_DECISION "TRUE";
BA_ "GenSigVtName" SG_ 1680 SIGN_1_VIS_TSR_RELEVANT_DECISION "VtSig_SIGN_1_VIS_TRS_RELEVANT_DECISION";
BA_ "GenSigSendType" SG_ 1680 SIGN_1_VIS_TSR_RELEVANT_DECISION 1;
BA_ "GenSigVtEn" SG_ 1680 SIGN_1_VIS_TSR_LOCATION "TRUE";
BA_ "GenSigVtName" SG_ 1680 SIGN_1_VIS_TSR_LOCATION "VtSig_SIGN_1_VIS_TSR_LOCATION";
BA_ "GenSigSendType" SG_ 1680 SIGN_1_VIS_TSR_LOCATION 1;
BA_ "GenSigSendType" SG_ 1680 SIGN_1_VIS_TSR_SIGN_EMBEDDED 1;
BA_ "GenSigSendType" SG_ 1680 SIGN_1_VIS_TSR_POSITION_LATERAL 1;
BA_ "GenSigVtEn" SG_ 1680 SIGN_1_VIS_TSR_SUPPL_TYPE_1ST "TRUE";
BA_ "GenSigVtName" SG_ 1680 SIGN_1_VIS_TSR_SUPPL_TYPE_1ST "VtSig_SIGN_1_VIS_TSR_SUPPL_TYPE_1ST";
BA_ "GenSigSendType" SG_ 1680 SIGN_1_VIS_TSR_SUPPL_TYPE_1ST 1;
BA_ "GenSigSendType" SG_ 1680 SIGN_1_VIS_TSR_ID 1;
BA_ "GenSigSendType" SG_ 1680 SIGN_1_VIS_TSR_SIGN_VALUE 1;
BA_ "GenSigSendType" SG_ 1680 SIGN_1_VIS_TSR_CONFIDENCE 1;
BA_ "GenSigVtEn" SG_ 1680 SIGN_1_VIS_TSR_STATUS "TRUE";
BA_ "GenSigVtName" SG_ 1680 SIGN_1_VIS_TSR_STATUS "VtSig_SIGN_1_VIS_TSR_STATUS";
BA_ "GenSigSendType" SG_ 1680 SIGN_1_VIS_TSR_STATUS 1;
BA_ "GenSigVtEn" SG_ 1680 SIGN_1_VIS_TSR_SUPPL_TYPE_2ND "TRUE";
BA_ "GenSigVtName" SG_ 1680 SIGN_1_VIS_TSR_SUPPL_TYPE_2ND "VtSig_SIGN_1_VIS_TSR_SUPPL_TYPE_2ND";
BA_ "GenSigSendType" SG_ 1680 SIGN_1_VIS_TSR_SUPPL_TYPE_2ND 1;
BA_ "GenSigSendType" SG_ 1680 SIGN_1_VIS_TSR_LOCATION_LANE 1;
BA_ "GenSigVtEn" SG_ 1680 SIGN_1_VIS_TSR_ELECTRONIC_SIGN "TRUE";
BA_ "GenSigVtName" SG_ 1680 SIGN_1_VIS_TSR_ELECTRONIC_SIGN "VtSig_SIGN_1_VIS_TSR_ELECTRONIC_SIGN";
BA_ "GenSigSendType" SG_ 1680 SIGN_1_VIS_TSR_ELECTRONIC_SIGN 1;
BA_ "GenSigVtEn" SG_ 1680 SIGN_1_VIS_TSR_TYPE "TRUE";
BA_ "GenSigVtName" SG_ 1680 SIGN_1_VIS_TSR_TYPE "VtSig_SIGN_1_VIS_TSR_TYPE";
BA_ "GenSigSendType" SG_ 1680 SIGN_1_VIS_TSR_TYPE 1;
BA_ "GenSigSendType" SG_ 1700 VIS_LANE_PARALL_PROB 1;
BA_ "GenSigSendType" SG_ 1700 VIS_ROAD_ISTUNNEL_ENTRYEXIT 1;
BA_ "GenSigSendType" SG_ 1649 VIS_OBS_CIPV 1;
BA_ "GenSigSendType" SG_ 1649 VIS_FCN_VIS_VRU_FCE_UNCONF_BRK 1;
BA_ "GenSigSendType" SG_ 1649 VIS_FCN_VIS_VEH_FCE_UNCONF_BRK 1;
BA_ "GenSigSendType" SG_ 1649 VIS_FCW_VIS_ONLY_VRU_WARN 1;
BA_ "GenSigSendType" SG_ 1649 VIS_FCW_VIS_ONLY_VRU_PART_BRAKE 1;
BA_ "GenSigSendType" SG_ 1649 VIS_FCW_VIS_ONLY_VEH_PART_BRAKE 1;
BA_ "GenSigVtEn" SG_ 1649 VIS_FCW_SENS_LEVEL "TRUE";
BA_ "GenSigVtName" SG_ 1649 VIS_FCW_SENS_LEVEL "VtSig_VIS_FCW_SENS_LEVEL";
BA_ "GenSigSendType" SG_ 1649 VIS_FCW_SENS_LEVEL 1;
BA_ "GenSigVtEn" SG_ 1649 VIS_FCW_NEAR_RNG_OBS_VIO "TRUE";
BA_ "GenSigVtName" SG_ 1649 VIS_FCW_NEAR_RNG_OBS_VIO "VtSig_VIS_FCN_NEAR_RNG_OBS_VIO";
BA_ "GenSigSendType" SG_ 1649 VIS_FCW_NEAR_RNG_OBS_VIO 1;
BA_ "GenSigSendType" SG_ 1649 VIS_FCW_VIS_ONLY_VEH_WARN 1;
BA_ "GenSigSendType" SG_ 1649 VIS_FCW_VIS_ONLY_VEH_BRAKE 1;
BA_ "GenSigSendType" SG_ 1649 VIS_FCW_VIS_ONLY_VRU_BRAKE 1;
BA_ "GenSigSendType" SG_ 1171 PAC_visTrkID 1;
BA_ "GenSigSendType" SG_ 1171 PAC_Stage_age 1;
BA_ "GenSigVtEn" SG_ 1171 PAC_Object_class "TRUE";
BA_ "GenSigVtName" SG_ 1171 PAC_Object_class "VtSig_PAC_Object_class";
BA_ "GenSigSendType" SG_ 1171 PAC_Object_class 1;
BA_ "GenSigSendType" SG_ 1155 P9C_visTrkID 1;
BA_ "GenSigSendType" SG_ 1155 P9C_Stage_age 1;
BA_ "GenSigVtEn" SG_ 1155 P9C_Object_class "TRUE";
BA_ "GenSigVtName" SG_ 1155 P9C_Object_class "VtSig_P9C_Object_class";
BA_ "GenSigSendType" SG_ 1155 P9C_Object_class 1;
BA_ "GenSigSendType" SG_ 1139 P8C_visTrkID 1;
BA_ "GenSigSendType" SG_ 1139 P8C_Stage_age 1;
BA_ "GenSigVtEn" SG_ 1139 P8C_Object_class "TRUE";
BA_ "GenSigVtName" SG_ 1139 P8C_Object_class "VtSig_P8C_Object_class";
BA_ "GenSigSendType" SG_ 1139 P8C_Object_class 1;
BA_ "GenSigSendType" SG_ 1123 P7C_visTrkID 1;
BA_ "GenSigSendType" SG_ 1123 P7C_Stage_age 1;
BA_ "GenSigVtEn" SG_ 1123 P7C_Object_class "TRUE";
BA_ "GenSigVtName" SG_ 1123 P7C_Object_class "VtSig_P7C_Object_class";
BA_ "GenSigSendType" SG_ 1123 P7C_Object_class 1;
BA_ "GenSigSendType" SG_ 1107 P6C_visTrkID 1;
BA_ "GenSigSendType" SG_ 1107 P6C_Stage_age 1;
BA_ "GenSigVtEn" SG_ 1107 P6C_Object_class "TRUE";
BA_ "GenSigVtName" SG_ 1107 P6C_Object_class "VtSig_P6C_Object_class";
BA_ "GenSigSendType" SG_ 1107 P6C_Object_class 1;
BA_ "GenSigSendType" SG_ 1091 P5C_visTrkID 1;
BA_ "GenSigSendType" SG_ 1091 P5C_Stage_age 1;
BA_ "GenSigVtEn" SG_ 1091 P5C_Object_class "TRUE";
BA_ "GenSigVtName" SG_ 1091 P5C_Object_class "VtSig_P5C_Object_class";
BA_ "GenSigSendType" SG_ 1091 P5C_Object_class 1;
BA_ "GenSigSendType" SG_ 1075 P4C_visTrkID 1;
BA_ "GenSigSendType" SG_ 1075 P4C_Stage_age 1;
BA_ "GenSigVtEn" SG_ 1075 P4C_Object_class "TRUE";
BA_ "GenSigVtName" SG_ 1075 P4C_Object_class "VtSig_P4C_Object_class";
BA_ "GenSigSendType" SG_ 1075 P4C_Object_class 1;
BA_ "GenSigSendType" SG_ 1059 P3C_visTrkID 1;
BA_ "GenSigSendType" SG_ 1059 P3C_Stage_age 1;
BA_ "GenSigVtEn" SG_ 1059 P3C_Object_class "TRUE";
BA_ "GenSigVtName" SG_ 1059 P3C_Object_class "VtSig_P3C_Object_class";
BA_ "GenSigSendType" SG_ 1059 P3C_Object_class 1;
BA_ "GenSigSendType" SG_ 1043 P2C_visTrkID 1;
BA_ "GenSigSendType" SG_ 1043 P2C_Stage_age 1;
BA_ "GenSigVtEn" SG_ 1043 P2C_Object_class "TRUE";
BA_ "GenSigVtName" SG_ 1043 P2C_Object_class "VtSig_P2C_Object_class";
BA_ "GenSigSendType" SG_ 1043 P2C_Object_class 1;
BA_ "GenSigSendType" SG_ 1170 PAB_A_lat_obj 1;
BA_ "GenSigSendType" SG_ 1170 PAB_V_lat_obj 1;
BA_ "GenSigSendType" SG_ 1170 PAB_FcwConfidence 1;
BA_ "GenSigSendType" SG_ 1170 PAB_CmbbPrimaryConfidence 1;
BA_ "GenSigVtEn" SG_ 1170 PAB_Status "TRUE";
BA_ "GenSigVtName" SG_ 1170 PAB_Status "VtSig_PAB_Status";
BA_ "GenSigSendType" SG_ 1170 PAB_Status 1;
BA_ "GenSigSendType" SG_ 1170 PAB_Age 1;
BA_ "GenSigSendType" SG_ 1154 P9B_V_lat_obj 1;
BA_ "GenSigSendType" SG_ 1154 P9B_FcwConfidence 1;
BA_ "GenSigSendType" SG_ 1154 P9B_CmbbPrimaryConfidence 1;
BA_ "GenSigVtEn" SG_ 1154 P9B_Status "TRUE";
BA_ "GenSigVtName" SG_ 1154 P9B_Status "VtSig_P9B_Status";
BA_ "GenSigSendType" SG_ 1154 P9B_Status 1;
BA_ "GenSigSendType" SG_ 1154 P9B_Age 1;
BA_ "GenSigSendType" SG_ 1154 P9B_A_lat_obj 1;
BA_ "GenSigSendType" SG_ 1138 P8B_V_lat_obj 1;
BA_ "GenSigSendType" SG_ 1138 P8B_FcwConfidence 1;
BA_ "GenSigSendType" SG_ 1138 P8B_CmbbPrimaryConfidence 1;
BA_ "GenSigVtEn" SG_ 1138 P8B_Status "TRUE";
BA_ "GenSigVtName" SG_ 1138 P8B_Status "VtSig_P8B_Status";
BA_ "GenSigSendType" SG_ 1138 P8B_Status 1;
BA_ "GenSigSendType" SG_ 1138 P8B_Age 1;
BA_ "GenSigSendType" SG_ 1138 P8B_A_lat_obj 1;
BA_ "GenSigSendType" SG_ 1122 P7B_V_lat_obj 1;
BA_ "GenSigSendType" SG_ 1122 P7B_FcwConfidence 1;
BA_ "GenSigSendType" SG_ 1122 P7B_CmbbPrimaryConfidence 1;
BA_ "GenSigVtEn" SG_ 1122 P7B_Status "TRUE";
BA_ "GenSigVtName" SG_ 1122 P7B_Status "VtSig_P7B_Status";
BA_ "GenSigSendType" SG_ 1122 P7B_Status 1;
BA_ "GenSigSendType" SG_ 1122 P7B_Age 1;
BA_ "GenSigSendType" SG_ 1122 P7B_A_lat_obj 1;
BA_ "GenSigSendType" SG_ 1106 P6B_V_lat_obj 1;
BA_ "GenSigSendType" SG_ 1106 P6B_FcwConfidence 1;
BA_ "GenSigSendType" SG_ 1106 P6B_CmbbPrimaryConfidence 1;
BA_ "GenSigVtEn" SG_ 1106 P6B_Status "TRUE";
BA_ "GenSigVtName" SG_ 1106 P6B_Status "VtSig_P6B_Status";
BA_ "GenSigSendType" SG_ 1106 P6B_Status 1;
BA_ "GenSigSendType" SG_ 1106 P6B_Age 1;
BA_ "GenSigSendType" SG_ 1106 P6B_A_lat_obj 1;
BA_ "GenSigSendType" SG_ 1090 P5B_V_lat_obj 1;
BA_ "GenSigSendType" SG_ 1090 P5B_FcwConfidence 1;
BA_ "GenSigSendType" SG_ 1090 P5B_CmbbPrimaryConfidence 1;
BA_ "GenSigVtEn" SG_ 1090 P5B_Status "TRUE";
BA_ "GenSigVtName" SG_ 1090 P5B_Status "VtSig_P5B_Status";
BA_ "GenSigSendType" SG_ 1090 P5B_Status 1;
BA_ "GenSigSendType" SG_ 1090 P5B_Age 1;
BA_ "GenSigSendType" SG_ 1090 P5B_A_lat_obj 1;
BA_ "GenSigSendType" SG_ 1074 P4B_V_lat_obj 1;
BA_ "GenSigSendType" SG_ 1074 P4B_FcwConfidence 1;
BA_ "GenSigSendType" SG_ 1074 P4B_CmbbPrimaryConfidence 1;
BA_ "GenSigVtEn" SG_ 1074 P4B_Status "TRUE";
BA_ "GenSigVtName" SG_ 1074 P4B_Status "VtSig_P4B_Status";
BA_ "GenSigSendType" SG_ 1074 P4B_Status 1;
BA_ "GenSigSendType" SG_ 1074 P4B_Age 1;
BA_ "GenSigSendType" SG_ 1074 P4B_A_lat_obj 1;
BA_ "GenSigSendType" SG_ 1058 P3B_V_lat_obj 1;
BA_ "GenSigSendType" SG_ 1058 P3B_FcwConfidence 1;
BA_ "GenSigSendType" SG_ 1058 P3B_CmbbPrimaryConfidence 1;
BA_ "GenSigVtEn" SG_ 1058 P3B_Status "TRUE";
BA_ "GenSigVtName" SG_ 1058 P3B_Status "VtSig_P3B_Status";
BA_ "GenSigSendType" SG_ 1058 P3B_Status 1;
BA_ "GenSigSendType" SG_ 1058 P3B_Age 1;
BA_ "GenSigSendType" SG_ 1058 P3B_A_lat_obj 1;
BA_ "GenSigSendType" SG_ 1042 P2B_V_lat_obj 1;
BA_ "GenSigSendType" SG_ 1042 P2B_FcwConfidence 1;
BA_ "GenSigSendType" SG_ 1042 P2B_CmbbPrimaryConfidence 1;
BA_ "GenSigVtEn" SG_ 1042 P2B_Status "TRUE";
BA_ "GenSigVtName" SG_ 1042 P2B_Status "VtSig_P2B_Status";
BA_ "GenSigSendType" SG_ 1042 P2B_Status 1;
BA_ "GenSigSendType" SG_ 1042 P2B_Age 1;
BA_ "GenSigSendType" SG_ 1042 P2B_A_lat_obj 1;
BA_ "GenSigSendType" SG_ 1169 PAA_V_long_obj 1;
BA_ "GenSigSendType" SG_ 1169 PAA_TrackID 1;
BA_ "GenSigStartValue" SG_ 1169 PAA_L_long_rel 3000;
BA_ "GenSigSendType" SG_ 1169 PAA_L_long_rel 1;
BA_ "GenSigSendType" SG_ 1169 PAA_L_lat_rel 1;
BA_ "GenSigSendType" SG_ 1169 PAA_A_long_obj 1;
BA_ "GenSigSendType" SG_ 1153 P9A_V_long_obj 1;
BA_ "GenSigSendType" SG_ 1153 P9A_TrackID 1;
BA_ "GenSigStartValue" SG_ 1153 P9A_L_long_rel 3000;
BA_ "GenSigSendType" SG_ 1153 P9A_L_long_rel 1;
BA_ "GenSigSendType" SG_ 1153 P9A_L_lat_rel 1;
BA_ "GenSigSendType" SG_ 1153 P9A_A_long_obj 1;
BA_ "GenSigSendType" SG_ 1137 P8A_V_long_obj 1;
BA_ "GenSigSendType" SG_ 1137 P8A_TrackID 1;
BA_ "GenSigStartValue" SG_ 1137 P8A_L_long_rel 3000;
BA_ "GenSigSendType" SG_ 1137 P8A_L_long_rel 1;
BA_ "GenSigSendType" SG_ 1137 P8A_L_lat_rel 1;
BA_ "GenSigSendType" SG_ 1137 P8A_A_long_obj 1;
BA_ "GenSigSendType" SG_ 1121 P7A_V_long_obj 1;
BA_ "GenSigSendType" SG_ 1121 P7A_TrackID 1;
BA_ "GenSigStartValue" SG_ 1121 P7A_L_long_rel 3000;
BA_ "GenSigSendType" SG_ 1121 P7A_L_long_rel 1;
BA_ "GenSigSendType" SG_ 1121 P7A_L_lat_rel 1;
BA_ "GenSigSendType" SG_ 1121 P7A_A_long_obj 1;
BA_ "GenSigSendType" SG_ 1105 P6A_L_lat_rel 1;
BA_ "GenSigSendType" SG_ 1105 P6A_A_long_obj 1;
BA_ "GenSigSendType" SG_ 1105 P6A_V_long_obj 1;
BA_ "GenSigStartValue" SG_ 1105 P6A_L_long_rel 3000;
BA_ "GenSigSendType" SG_ 1105 P6A_L_long_rel 1;
BA_ "GenSigSendType" SG_ 1105 P6A_TrackID 1;
BA_ "GenSigSendType" SG_ 1089 P5A_L_lat_rel 1;
BA_ "GenSigSendType" SG_ 1089 P5A_A_long_obj 1;
BA_ "GenSigSendType" SG_ 1089 P5A_V_long_obj 1;
BA_ "GenSigStartValue" SG_ 1089 P5A_L_long_rel 3000;
BA_ "GenSigSendType" SG_ 1089 P5A_L_long_rel 1;
BA_ "GenSigSendType" SG_ 1089 P5A_TrackID 1;
BA_ "GenSigSendType" SG_ 1073 P4A_L_lat_rel 1;
BA_ "GenSigSendType" SG_ 1073 P4A_A_long_obj 1;
BA_ "GenSigSendType" SG_ 1073 P4A_V_long_obj 1;
BA_ "GenSigStartValue" SG_ 1073 P4A_L_long_rel 3000;
BA_ "GenSigSendType" SG_ 1073 P4A_L_long_rel 1;
BA_ "GenSigSendType" SG_ 1073 P4A_TrackID 1;
BA_ "GenSigSendType" SG_ 1057 P3A_L_lat_rel 1;
BA_ "GenSigSendType" SG_ 1057 P3A_A_long_obj 1;
BA_ "GenSigSendType" SG_ 1057 P3A_V_long_obj 1;
BA_ "GenSigStartValue" SG_ 1057 P3A_L_long_rel 3000;
BA_ "GenSigSendType" SG_ 1057 P3A_L_long_rel 1;
BA_ "GenSigSendType" SG_ 1057 P3A_TrackID 1;
BA_ "GenSigSendType" SG_ 1041 P2A_L_lat_rel 1;
BA_ "GenSigSendType" SG_ 1041 P2A_V_long_obj 1;
BA_ "GenSigSendType" SG_ 1041 P2A_A_long_obj 1;
BA_ "GenSigStartValue" SG_ 1041 P2A_L_long_rel 3000;
BA_ "GenSigSendType" SG_ 1041 P2A_L_long_rel 1;
BA_ "GenSigSendType" SG_ 1041 P2A_TrackID 1;
BA_ "GenSigSendType" SG_ 1026 P1B_Age 1;
BA_ "GenSigSendType" SG_ 1026 P1B_V_lat_obj 1;
BA_ "GenSigSendType" SG_ 1026 P1B_FcwConfidence 1;
BA_ "GenSigSendType" SG_ 1026 P1B_CmbbPrimaryConfidence 1;
BA_ "GenSigVtEn" SG_ 1026 P1B_Status "TRUE";
BA_ "GenSigVtName" SG_ 1026 P1B_Status "VtSig_P1B_Status";
BA_ "GenSigSendType" SG_ 1026 P1B_Status 1;
BA_ "GenSigSendType" SG_ 1026 P1B_A_lat_obj 1;
VAL_ 1654 VIS_OBS_CUT_IN_OUT_15 7 "reserved" 6 "reserved" 5 "reserved" 4 "cut out" 3 "cut in" 2 "out host lane" 1 "in host lane" 0 "undetermined" ;
VAL_ 1654 VIS_OBS_CUT_IN_OUT_14 7 "reserved" 6 "reserved" 5 "reserved" 4 "cut out" 3 "cut in" 2 "out host lane" 1 "in host lane" 0 "undetermined" ;
VAL_ 1654 VIS_OBS_CUT_IN_OUT_13 7 "reserved" 6 "reserved" 5 "reserved" 4 "cut out" 3 "cut in" 2 "out host lane" 1 "in host lane" 0 "undetermined" ;
VAL_ 1654 VIS_OBS_CUT_IN_OUT_12 7 "reserved" 6 "reserved" 5 "reserved" 4 "cut out" 3 "cut in" 2 "out host lane" 1 "in host lane" 0 "undetermined" ;
VAL_ 1654 VIS_OBS_CUT_IN_OUT_11 7 "reserved" 6 "reserved" 5 "reserved" 4 "cut out" 3 "cut in" 2 "out host lane" 1 "in host lane" 0 "undetermined" ;
VAL_ 1654 VIS_OBS_CUT_IN_OUT_10 7 "reserved" 6 "reserved" 5 "reserved" 4 "cut out" 3 "cut in" 2 "out host lane" 1 "in host lane" 0 "undetermined" ;
VAL_ 1654 VIS_OBS_CUT_IN_OUT_09 7 "reserved" 6 "reserved" 5 "reserved" 4 "cut out" 3 "cut in" 2 "out host lane" 1 "in host lane" 0 "undetermined" ;
VAL_ 1654 VIS_OBS_CUT_IN_OUT_08 7 "reserved" 6 "reserved" 5 "reserved" 4 "cut out" 3 "cut in" 2 "out host lane" 1 "in host lane" 0 "undetermined" ;
VAL_ 1654 VIS_OBS_CUT_IN_OUT_07 7 "reserved" 6 "reserved" 5 "reserved" 4 "cut out" 3 "cut in" 2 "out host lane" 1 "in host lane" 0 "undetermined" ;
VAL_ 1654 VIS_OBS_CUT_IN_OUT_06 7 "reserved" 6 "reserved" 5 "reserved" 4 "cut out" 3 "cut in" 2 "out host lane" 1 "in host lane" 0 "undetermined" ;
VAL_ 1654 VIS_OBS_CUT_IN_OUT_05 7 "reserved" 6 "reserved" 5 "reserved" 4 "cut out" 3 "cut in" 2 "out host lane" 1 "in host lane" 0 "undetermined" ;
VAL_ 1654 VIS_OBS_CUT_IN_OUT_04 7 "reserved" 6 "reserved" 5 "reserved" 4 "cut out" 3 "cut in" 2 "out host lane" 1 "in host lane" 0 "undetermined" ;
VAL_ 1654 VIS_OBS_CUT_IN_OUT_03 7 "reserved" 6 "reserved" 5 "reserved" 4 "cut out" 3 "cut in" 2 "out host lane" 1 "in host lane" 0 "undetermined" ;
VAL_ 1654 VIS_OBS_CUT_IN_OUT_02 7 "reserved" 6 "reserved" 5 "reserved" 4 "cut out" 3 "cut in" 2 "out host lane" 1 "in host lane" 0 "undetermined" ;
VAL_ 1654 VIS_OBS_CUT_IN_OUT_01 7 "reserved" 6 "reserved" 5 "reserved" 4 "cut out" 3 "cut in" 2 "out host lane" 1 "in host lane" 0 "undetermined" ;
VAL_ 1650 VIS_FAILSAFE_OUT_OF_FOCUS 3 "most severe" 2 "75" 1 "25" 0 "off" ;
VAL_ 1650 VIS_FAILSAFE_OUT_OF_CALIBRATION 3 "most severe" 2 "75" 1 "25" 0 "off" ;
VAL_ 1650 FUS_FAILSAFE_FUS_RAD_MISALIGNMNT 3 "most severe" 2 "75" 1 "25" 0 "off" ;
VAL_ 1650 FUS_FAILSAFE_FUS_RAD_LOW_VIS 3 "most severe" 2 "75" 1 "25" 0 "off" ;
VAL_ 1650 VIS_FAILSAFE_NIGHT_SPOT_RAYS 3 "most severe" 2 "75" 1 "25" 0 "off" ;
VAL_ 1650 VIS_FAILSAFE_NIGHT_SMEARED_SPOTS 3 "most severe" 2 "75" 1 "25" 0 "off" ;
VAL_ 1650 VIS_FAILSAFE_NIGHT_SELF_GLARE 3 "most severe" 2 "75" 1 "25" 0 "off" ;
VAL_ 1650 VIS_FAILSAFE_SMEAR_IMAGE 3 "most severe" 2 "75" 1 "25" 0 "off" ;
VAL_ 1650 VIS_FAILSAFE_NIGHT_FULL_BLOCK 3 "most severe" 2 "75" 1 "25" 0 "off" ;
VAL_ 1650 VIS_FAILSAFE_NIGHT_FOGGY_SPOTS 3 "most severe" 2 "75" 1 "25" 0 "off" ;
VAL_ 1650 VIS_FAILSAFE_NIGHT_BLUR 3 "most severe" 2 "75" 1 "25" 0 "off" ;
VAL_ 1650 VIS_FAILSAFE_DAY_SUN_RAY 3 "most severe" 2 "75" 1 "25" 0 "off" ;
VAL_ 1650 VIS_FAILSAFE_DAY_SPLASHES 3 "most severe" 2 "75" 1 "25" 0 "off" ;
VAL_ 1650 VIS_FAILSAFE_DAY_LOW_SUN 3 "most severe" 2 "75" 1 "25" 0 "off" ;
VAL_ 1650 CAN_DRIVING_SIDE 1 "true" 0 "false" ;
VAL_ 1650 VIS_FAILSAFE_FLR_VIS_CORRELATION 1 "true" 0 "false" ;
VAL_ 1650 VIS_FAULT_INVALID_SPEED_YAW 1 "true" 0 "false" ;
VAL_ 1650 VIS_FAULT_IMAGER_RCC_MISALIGNED 1 "true" 0 "false" ;
VAL_ 1650 VIS_FAILSAFE_PART_BLUR_IMAGE 1 "true" 0 "false" ;
VAL_ 1650 VIS_FAILSAFE_PART_SOLID_BLOCKAGE 1 "true" 0 "false" ;
VAL_ 1650 VIS_FAILSAFE_HEAVY_RAIN 1 "true" 0 "false" ;
VAL_ 1650 VIS_FAILSAFE_ROLL_ANGLE 1 "true" 0 "false" ;
VAL_ 1689 VIS_TSR_SIGN_EMBEDDED_1 1 "yes" 0 "no" ;
VAL_ 1689 VIS_TSR_SIGN_LANE_1 6 "right lane 2" 5 "right lane 1" 4 "lane host" 3 "left lane 2" 2 "left lane 1" 1 "exit" 0 "none" ;
VAL_ 1689 VIS_TSR_SIGN_POSITION_1 2 "top" 1 "left" 0 "right" ;
VAL_ 1689 VIS_TSR_SIGN_SUPPL_TYPE2_1 24 "truck and trailer" 23 "distance for AND in" 22 "ice" 21 "end" 20 "bend right" 19 "bend left" 18 "arrow right" 17 "arrow left" 16 "tractor" 15 "truck" 14 "trailer" 13 "zone" 12 "night" 11 "fog" 10 "snow rain" 9 "snow" 8 "rain cloud" 7 "rain" 6 "school" 5 "weight" 4 "time" 3 "distance arrow" 2 "distance" 1 "generic" 0 "none" ;
VAL_ 1689 VIS_TSR_SIGN_SUPPL_TYPE1_1 24 "truck and trailer" 23 "distance for AND in" 22 "ice" 21 "end" 20 "bend right" 19 "bend left" 18 "arrow right" 17 "arrow left" 16 "tractor" 15 "truck" 14 "trailer" 13 "zone" 12 "night" 11 "fog" 10 "snow rain" 9 "snow" 8 "rain cloud" 7 "rain" 6 "school" 5 "weight" 4 "time" 3 "distance arrow" 2 "distance" 1 "generic" 0 "none" ;
VAL_ 1689 VIS_TSR_SIGN_VARIABLE_1 1 "yes" 0 "no" ;
VAL_ 1689 VIS_TSR_SIGN_TYPE_1 27 "end of all" 26 "round about" 25 "reserved" 24 "reserved" 23 "reserved" 22 "reserved" 21 "reserved" 20 "no overtaking trucks end" 19 "no overtaking trucks start" 18 "no entrance" 17 "no overtaking end" 16 "no overtaking start" 15 "stop" 14 "low speed area end" 13 "low speed area start" 12 "town end" 11 "town start" 10 "reserved" 9 "reserved" 8 "freeway end" 7 "freeway start" 6 "highway end" 5 "highway start" 4 "reserved" 3 "reserved" 2 "speed limit end" 1 "speed limit start" 0 "unknown" ;
VAL_ 1689 VIS_TSR_SCENE_STATUS_1 1 "open" 0 "closed" ;
VAL_ 1688 VIS_TSR_LANE_CHANGE 2 "lane change right" 1 "lane change left" 0 "no lane change detected" ;
VAL_ 1688 VIS_TSR_ROAD_CLASS 4 "motorway" 3 "expressway" 2 "outside a city" 1 "inside a city" 0 "unknown" ;
VAL_ 1688 VIS_TSR_SPEED_UNIT 2 "mph" 1 "kph" 0 "unknown" ;
VAL_ 1688 VIS_TSR_TRAFFIC_STYLE 1 "left hand driving" 0 "right hand driving" ;
VAL_ 1939 VIS_AHBC_DARK_ONCOMING_LANE 1 "not dark" 0 "dark" ;
VAL_ 1939 VIS_AHBC_CLEAR_FIELD_OF_VIEW 2 "clear field of view" 1 "no clear field of view" 0 "unknown" ;
VAL_ 1939 VIS_AHBC_STRUCT_SEPARATION_DET 4 "unknown/alternating separation" 3 "separation covering cars complet" 2 "separation covering cars partly" 1 "separation covering headlamps" 0 "no structural separation" ;
VAL_ 1939 VIS_AHBC_DAY_TIME_STATUS 3 "tunnel" 2 "night" 1 "twilight" 0 "day" ;
VAL_ 1939 VIS_AHBC_FOG_DETECTION 1 "fog" 0 "no fog" ;
VAL_ 1939 VIS_AHBC_HIGHWAY_DETECTION 1 "autobahn/highway" 0 "no autobahn/highway" ;
VAL_ 1939 VIS_AHBC_URBAN_AREA_DETECTION 2 "city" 1 "subdivision" 0 "no urban area" ;
VAL_ 1939 VIS_AHBC_TRAFFIC_STYLE_DETECTION 1 "left hand traffic" 0 "right hand traffic" ;
VAL_ 1938 VIS_AHBC_OBJ_10_TYPE 5 "truck cabin top lights" 4 "pair of tail-lamps" 3 "pair of headlamps" 2 "tail-lamp" 1 "headlamp" 0 "none" ;
VAL_ 1938 VIS_AHBC_OBJ_10_DISTANCE 15 ">1000m" 14 ">800m - 1000m" 13 ">700m - 800m" 12 ">600m - 700m" 11 ">500m - 600m" 10 ">400m - 500m" 9 ">300m - 400m" 8 ">200m - 300m" 7 ">175m - 200m" 6 ">150m - 175m" 5 ">125m - 150m" 4 ">100m - 125m" 3 ">75m - 100m" 2 ">50m - 75m" 1 ">25m - 50m" 0 "0m - 25m" ;
VAL_ 1937 VIS_AHBC_OBJ_09_TYPE 5 "truck cabin top lights" 4 "pair of tail-lamps" 3 "pair of headlamps" 2 "tail-lamp" 1 "headlamp" 0 "none" ;
VAL_ 1937 VIS_AHBC_OBJ_09_DISTANCE 15 ">1000m" 14 ">800m - 1000m" 13 ">700m - 800m" 12 ">600m - 700m" 11 ">500m - 600m" 10 ">400m - 500m" 9 ">300m - 400m" 8 ">200m - 300m" 7 ">175m - 200m" 6 ">150m - 175m" 5 ">125m - 150m" 4 ">100m - 125m" 3 ">75m - 100m" 2 ">50m - 75m" 1 ">25m - 50m" 0 "0m - 25m" ;
VAL_ 1936 VIS_AHBC_OBJ_08_TYPE 5 "truck cabin top lights" 4 "pair of tail-lamps" 3 "pair of headlamps" 2 "tail-lamp" 1 "headlamp" 0 "none" ;
VAL_ 1936 VIS_AHBC_OBJ_08_DISTANCE 15 ">1000m" 14 ">800m - 1000m" 13 ">700m - 800m" 12 ">600m - 700m" 11 ">500m - 600m" 10 ">400m - 500m" 9 ">300m - 400m" 8 ">200m - 300m" 7 ">175m - 200m" 6 ">150m - 175m" 5 ">125m - 150m" 4 ">100m - 125m" 3 ">75m - 100m" 2 ">50m - 75m" 1 ">25m - 50m" 0 "0m - 25m" ;
VAL_ 1935 VIS_AHBC_OBJ_07_TYPE 5 "truck cabin top lights" 4 "pair of tail-lamps" 3 "pair of headlamps" 2 "tail-lamp" 1 "headlamp" 0 "none" ;
VAL_ 1935 VIS_AHBC_OBJ_07_DISTANCE 15 ">1000m" 14 ">800m - 1000m" 13 ">700m - 800m" 12 ">600m - 700m" 11 ">500m - 600m" 10 ">400m - 500m" 9 ">300m - 400m" 8 ">200m - 300m" 7 ">175m - 200m" 6 ">150m - 175m" 5 ">125m - 150m" 4 ">100m - 125m" 3 ">75m - 100m" 2 ">50m - 75m" 1 ">25m - 50m" 0 "0m - 25m" ;
VAL_ 1934 VIS_AHBC_OBJ_06_TYPE 5 "truck cabin top lights" 4 "pair of tail-lamps" 3 "pair of headlamps" 2 "tail-lamp" 1 "headlamp" 0 "none" ;
VAL_ 1934 VIS_AHBC_OBJ_06_DISTANCE 15 ">1000m" 14 ">800m - 1000m" 13 ">700m - 800m" 12 ">600m - 700m" 11 ">500m - 600m" 10 ">400m - 500m" 9 ">300m - 400m" 8 ">200m - 300m" 7 ">175m - 200m" 6 ">150m - 175m" 5 ">125m - 150m" 4 ">100m - 125m" 3 ">75m - 100m" 2 ">50m - 75m" 1 ">25m - 50m" 0 "0m - 25m" ;
VAL_ 1933 VIS_AHBC_OBJ_05_TYPE 5 "truck cabin top lights" 4 "pair of tail-lamps" 3 "pair of headlamps" 2 "tail-lamp" 1 "headlamp" 0 "none" ;
VAL_ 1933 VIS_AHBC_OBJ_05_DISTANCE 15 ">1000m" 14 ">800m - 1000m" 13 ">700m - 800m" 12 ">600m - 700m" 11 ">500m - 600m" 10 ">400m - 500m" 9 ">300m - 400m" 8 ">200m - 300m" 7 ">175m - 200m" 6 ">150m - 175m" 5 ">125m - 150m" 4 ">100m - 125m" 3 ">75m - 100m" 2 ">50m - 75m" 1 ">25m - 50m" 0 "0m - 25m" ;
VAL_ 1932 VIS_AHBC_OBJ_04_TYPE 5 "truck cabin top lights" 4 "pair of tail-lamps" 3 "pair of headlamps" 2 "tail-lamp" 1 "headlamp" 0 "none" ;
VAL_ 1932 VIS_AHBC_OBJ_04_DISTANCE 15 ">1000m" 14 ">800m - 1000m" 13 ">700m - 800m" 12 ">600m - 700m" 11 ">500m - 600m" 10 ">400m - 500m" 9 ">300m - 400m" 8 ">200m - 300m" 7 ">175m - 200m" 6 ">150m - 175m" 5 ">125m - 150m" 4 ">100m - 125m" 3 ">75m - 100m" 2 ">50m - 75m" 1 ">25m - 50m" 0 "0m - 25m" ;
VAL_ 1931 VIS_AHBC_OBJ_03_TYPE 5 "truck cabin top lights" 4 "pair of tail-lamps" 3 "pair of headlamps" 2 "tail-lamp" 1 "headlamp" 0 "none" ;
VAL_ 1931 VIS_AHBC_OBJ_03_DISTANCE 15 ">1000m" 14 ">800m - 1000m" 13 ">700m - 800m" 12 ">600m - 700m" 11 ">500m - 600m" 10 ">400m - 500m" 9 ">300m - 400m" 8 ">200m - 300m" 7 ">175m - 200m" 6 ">150m - 175m" 5 ">125m - 150m" 4 ">100m - 125m" 3 ">75m - 100m" 2 ">50m - 75m" 1 ">25m - 50m" 0 "0m - 25m" ;
VAL_ 1930 VIS_AHBC_OBJ_02_TYPE 5 "truck cabin top lights" 4 "pair of tail-lamps" 3 "pair of headlamps" 2 "tail-lamp" 1 "headlamp" 0 "none" ;
VAL_ 1930 VIS_AHBC_OBJ_02_DISTANCE 15 ">1000m" 14 ">800m - 1000m" 13 ">700m - 800m" 12 ">600m - 700m" 11 ">500m - 600m" 10 ">400m - 500m" 9 ">300m - 400m" 8 ">200m - 300m" 7 ">175m - 200m" 6 ">150m - 175m" 5 ">125m - 150m" 4 ">100m - 125m" 3 ">75m - 100m" 2 ">50m - 75m" 1 ">25m - 50m" 0 "0m - 25m" ;
VAL_ 1929 VIS_AHBC_OBJ_01_TYPE 5 "truck cabin top lights" 4 "pair of tail-lamps" 3 "pair of headlamps" 2 "tail-lamp" 1 "headlamp" 0 "none" ;
VAL_ 1929 VIS_AHBC_OBJ_01_DISTANCE 15 ">1000m" 14 ">800m - 1000m" 13 ">700m - 800m" 12 ">600m - 700m" 11 ">500m - 600m" 10 ">400m - 500m" 9 ">300m - 400m" 8 ">200m - 300m" 7 ">175m - 200m" 6 ">150m - 175m" 5 ">125m - 150m" 4 ">100m - 125m" 3 ">75m - 100m" 2 ">50m - 75m" 1 ">25m - 50m" 0 "0m - 25m" ;
VAL_ 1709 VIS_LANE_RIGHT_PARALL_STATUS 7 "reserved" 6 "coasted measurement" 5 "updated measurement of geometry" 4 "reserved" 3 "reserved" 2 "new geometry detected" 1 "reserved" 0 "invalid" ;
VAL_ 1709 VIS_LANE_RIGHT_INDIVID_STATUS 7 "reserved" 6 "coasted measurement" 5 "updated measurement of geometry" 4 "reserved" 3 "reserved" 2 "new geometry detected" 1 "reserved" 0 "invalid" ;
VAL_ 1709 VIS_LANE_LEFT_PARALL_STATUS 7 "reserved" 6 "coasted measurement" 5 "updated measurement of geometry" 4 "reserved" 3 "reserved" 2 "new geometry detected" 1 "reserved" 0 "invalid" ;
VAL_ 1709 VIS_LANE_LEFT_INDIVID_STATUS 7 "reserved" 6 "coasted measurement" 5 "updated measurement of geometry" 4 "reserved" 3 "reserved" 2 "new geometry detected" 1 "reserved" 0 "invalid" ;
VAL_ 1701 VIS_CENTER_POLYNOMIAL_LINECASE 3 "left and right line" 2 "right line" 1 "left line" 0 "no line" ;
VAL_ 1701 VIS_CENTER_POLYNOMIAL_LANECONF 2 "good" 1 "middle" 0 "bad" ;
VAL_ 1653 VIS_OBS_TURN_INDICATOR_15 3 "unknown" 2 "right turn indicator active" 1 "left turn indicator active" 0 "no turn indicator active" ;
VAL_ 1653 VIS_OBS_TURN_INDICATOR_14 3 "unknown" 2 "right turn indicator active" 1 "left turn indicator active" 0 "no turn indicator active" ;
VAL_ 1653 VIS_OBS_TURN_INDICATOR_13 3 "unknown" 2 "right turn indicator active" 1 "left turn indicator active" 0 "no turn indicator active" ;
VAL_ 1653 VIS_OBS_TURN_INDICATOR_12 3 "unknown" 2 "right turn indicator active" 1 "left turn indicator active" 0 "no turn indicator active" ;
VAL_ 1653 VIS_OBS_TURN_INDICATOR_11 3 "unknown" 2 "right turn indicator active" 1 "left turn indicator active" 0 "no turn indicator active" ;
VAL_ 1653 VIS_OBS_TURN_INDICATOR_10 3 "unknown" 2 "right turn indicator active" 1 "left turn indicator active" 0 "no turn indicator active" ;
VAL_ 1653 VIS_OBS_TURN_INDICATOR_09 3 "unknown" 2 "right turn indicator active" 1 "left turn indicator active" 0 "no turn indicator active" ;
VAL_ 1653 VIS_OBS_TURN_INDICATOR_08 3 "unknown" 2 "right turn indicator active" 1 "left turn indicator active" 0 "no turn indicator active" ;
VAL_ 1653 VIS_OBS_TURN_INDICATOR_07 3 "unknown" 2 "right turn indicator active" 1 "left turn indicator active" 0 "no turn indicator active" ;
VAL_ 1653 VIS_OBS_TURN_INDICATOR_06 3 "unknown" 2 "right turn indicator active" 1 "left turn indicator active" 0 "no turn indicator active" ;
VAL_ 1653 VIS_OBS_TURN_INDICATOR_05 3 "unknown" 2 "right turn indicator active" 1 "left turn indicator active" 0 "no turn indicator active" ;
VAL_ 1653 VIS_OBS_TURN_INDICATOR_04 3 "unknown" 2 "right turn indicator active" 1 "left turn indicator active" 0 "no turn indicator active" ;
VAL_ 1653 VIS_OBS_TURN_INDICATOR_03 3 "unknown" 2 "right turn indicator active" 1 "left turn indicator active" 0 "no turn indicator active" ;
VAL_ 1653 VIS_OBS_TURN_INDICATOR_02 3 "unknown" 2 "right turn indicator active" 1 "left turn indicator active" 0 "no turn indicator active" ;
VAL_ 1653 VIS_OBS_PED_WAIST_UP_15 1 "false" 0 "true" ;
VAL_ 1653 VIS_OBS_PED_WAIST_UP_14 1 "false" 0 "true" ;
VAL_ 1653 VIS_OBS_PED_WAIST_UP_13 1 "false" 0 "true" ;
VAL_ 1653 VIS_OBS_PED_WAIST_UP_12 1 "false" 0 "true" ;
VAL_ 1653 VIS_OBS_PED_WAIST_UP_11 1 "false" 0 "true" ;
VAL_ 1653 VIS_OBS_PED_WAIST_UP_10 1 "false" 0 "true" ;
VAL_ 1653 VIS_OBS_PED_WAIST_UP_09 1 "false" 0 "true" ;
VAL_ 1653 VIS_OBS_PED_WAIST_UP_08 1 "false" 0 "true" ;
VAL_ 1653 VIS_OBS_PED_WAIST_UP_07 1 "false" 0 "true" ;
VAL_ 1653 VIS_OBS_PED_WAIST_UP_06 1 "false" 0 "true" ;
VAL_ 1653 VIS_OBS_PED_WAIST_UP_05 1 "false" 0 "true" ;
VAL_ 1653 VIS_OBS_PED_WAIST_UP_04 1 "false" 0 "true" ;
VAL_ 1653 VIS_OBS_PED_WAIST_UP_03 1 "false" 0 "true" ;
VAL_ 1653 VIS_OBS_PED_WAIST_UP_02 1 "false" 0 "true" ;
VAL_ 1653 VIS_OBS_CLASSIFICATION_15 10 "unidentified vehicle" 9 "bicycle" 8 "general on-road object" 7 "animal" 6 "reserved" 5 "reserved" 4 "pedestrian" 3 "truck" 2 "motorcycle" 1 "car" 0 "undetermined" ;
VAL_ 1653 VIS_OBS_CLASSIFICATION_14 10 "unidentified vehicle" 9 "bicycle" 8 "general on-road object" 7 "animal" 6 "reserved" 5 "reserved" 4 "pedestrian" 3 "truck" 2 "motorcycle" 1 "car" 0 "undetermined" ;
VAL_ 1653 VIS_OBS_CLASSIFICATION_13 10 "unidentified vehicle" 9 "bicycle" 8 "general on-road object" 7 "animal" 6 "reserved" 5 "reserved" 4 "pedestrian" 3 "truck" 2 "motorcycle" 1 "car" 0 "undetermined" ;
VAL_ 1653 VIS_OBS_CLASSIFICATION_12 10 "unidentified vehicle" 9 "bicycle" 8 "general on-road object" 7 "animal" 6 "reserved" 5 "reserved" 4 "pedestrian" 3 "truck" 2 "motorcycle" 1 "car" 0 "undetermined" ;
VAL_ 1653 VIS_OBS_CLASSIFICATION_11 10 "unidentified vehicle" 9 "bicycle" 8 "general on-road object" 7 "animal" 6 "reserved" 5 "reserved" 4 "pedestrian" 3 "truck" 2 "motorcycle" 1 "car" 0 "undetermined" ;
VAL_ 1653 VIS_OBS_CLASSIFICATION_10 10 "unidentified vehicle" 9 "bicycle" 8 "general on-road object" 7 "animal" 6 "reserved" 5 "reserved" 4 "pedestrian" 3 "truck" 2 "motorcycle" 1 "car" 0 "undetermined" ;
VAL_ 1653 VIS_OBS_CLASSIFICATION_09 10 "unidentified vehicle" 9 "bicycle" 8 "general on-road object" 7 "animal" 6 "reserved" 5 "reserved" 4 "pedestrian" 3 "truck" 2 "motorcycle" 1 "car" 0 "undetermined" ;
VAL_ 1653 VIS_OBS_CLASSIFICATION_08 10 "unidentified vehicle" 9 "bicycle" 8 "general on-road object" 7 "animal" 6 "reserved" 5 "reserved" 4 "pedestrian" 3 "truck" 2 "motorcycle" 1 "car" 0 "undetermined" ;
VAL_ 1653 VIS_OBS_CLASSIFICATION_07 10 "unidentified vehicle" 9 "bicycle" 8 "general on-road object" 7 "animal" 6 "reserved" 5 "reserved" 4 "pedestrian" 3 "truck" 2 "motorcycle" 1 "car" 0 "undetermined" ;
VAL_ 1653 VIS_OBS_CLASSIFICATION_06 10 "unidentified vehicle" 9 "bicycle" 8 "general on-road object" 7 "animal" 6 "reserved" 5 "reserved" 4 "pedestrian" 3 "truck" 2 "motorcycle" 1 "car" 0 "undetermined" ;
VAL_ 1653 VIS_OBS_CLASSIFICATION_05 10 "unidentified vehicle" 9 "bicycle" 8 "general on-road object" 7 "animal" 6 "reserved" 5 "reserved" 4 "pedestrian" 3 "truck" 2 "motorcycle" 1 "car" 0 "undetermined" ;
VAL_ 1653 VIS_OBS_CLASSIFICATION_04 10 "unidentified vehicle" 9 "bicycle" 8 "general on-road object" 7 "animal" 6 "reserved" 5 "reserved" 4 "pedestrian" 3 "truck" 2 "motorcycle" 1 "car" 0 "undetermined" ;
VAL_ 1653 VIS_OBS_CLASSIFICATION_03 10 "unidentified vehicle" 9 "bicycle" 8 "general on-road object" 7 "animal" 6 "reserved" 5 "reserved" 4 "pedestrian" 3 "truck" 2 "motorcycle" 1 "car" 0 "undetermined" ;
VAL_ 1653 VIS_OBS_CLASSIFICATION_02 10 "unidentified vehicle" 9 "bicycle" 8 "general on-road object" 7 "animal" 6 "reserved" 5 "reserved" 4 "pedestrian" 3 "truck" 2 "motorcycle" 1 "car" 0 "undetermined" ;
VAL_ 1653 VIS_OBS_BRAKE_LIGHT_INDIC_15 2 "brake light is steady active" 1 "no brake light is active" 0 "unknown" ;
VAL_ 1653 VIS_OBS_BRAKE_LIGHT_INDIC_14 2 "brake light is steady active" 1 "no brake light is active" 0 "unknown" ;
VAL_ 1653 VIS_OBS_BRAKE_LIGHT_INDIC_13 2 "brake light is steady active" 1 "no brake light is active" 0 "unknown" ;
VAL_ 1653 VIS_OBS_BRAKE_LIGHT_INDIC_12 2 "brake light is steady active" 1 "no brake light is active" 0 "unknown" ;
VAL_ 1653 VIS_OBS_BRAKE_LIGHT_INDIC_11 2 "brake light is steady active" 1 "no brake light is active" 0 "unknown" ;
VAL_ 1653 VIS_OBS_BRAKE_LIGHT_INDIC_10 2 "brake light is steady active" 1 "no brake light is active" 0 "unknown" ;
VAL_ 1653 VIS_OBS_BRAKE_LIGHT_INDIC_09 2 "brake light is steady active" 1 "no brake light is active" 0 "unknown" ;
VAL_ 1653 VIS_OBS_BRAKE_LIGHT_INDIC_08 2 "brake light is steady active" 1 "no brake light is active" 0 "unknown" ;
VAL_ 1653 VIS_OBS_BRAKE_LIGHT_INDIC_07 2 "brake light is steady active" 1 "no brake light is active" 0 "unknown" ;
VAL_ 1653 VIS_OBS_BRAKE_LIGHT_INDIC_06 2 "brake light is steady active" 1 "no brake light is active" 0 "unknown" ;
VAL_ 1653 VIS_OBS_BRAKE_LIGHT_INDIC_05 2 "brake light is steady active" 1 "no brake light is active" 0 "unknown" ;
VAL_ 1653 VIS_OBS_BRAKE_LIGHT_INDIC_04 2 "brake light is steady active" 1 "no brake light is active" 0 "unknown" ;
VAL_ 1653 VIS_OBS_BRAKE_LIGHT_INDIC_03 2 "brake light is steady active" 1 "no brake light is active" 0 "unknown" ;
VAL_ 1653 VIS_OBS_BRAKE_LIGHT_INDIC_02 2 "brake light is steady active" 1 "no brake light is active" 0 "unknown" ;
VAL_ 1653 VIS_OBS_TURN_INDICATOR_01 3 "unknown" 2 "right turn indicator active" 1 "left turn indicator active" 0 "no turn indicator active" ;
VAL_ 1653 VIS_OBS_PED_WAIST_UP_01 1 "false" 0 "true" ;
VAL_ 1653 VIS_OBS_CLASSIFICATION_01 10 "unidentified vehicle" 9 "bicycle" 8 "general on-road object" 7 "animal" 6 "reserved" 5 "reserved" 4 "pedestrian" 3 "truck" 2 "motorcycle" 1 "car" 0 "undetermined" ;
VAL_ 1653 VIS_OBS_BRAKE_LIGHT_INDIC_01 2 "brake light is steady active" 1 "no brake light is active" 0 "unknown" ;
VAL_ 1702 VIS_LANE_RIGHT_PA_MARKER_COLOR 3 "blue" 2 "white" 1 "yellow" 0 "unknown" ;
VAL_ 1707 VIS_LANE_RIGHT_IN_MARKER_COLOR 3 "blue" 2 "white" 1 "yellow" 0 "unknown" ;
VAL_ 1703 VIS_LANE_LEFT_PA_MARKER_COLOR 3 "blue" 2 "white" 1 "yellow" 0 "unknown" ;
VAL_ 1708 VIS_LANE_LEFT_IN_MARKER_COLOR 3 "blue" 2 "white" 1 "yellow" 0 "unknown" ;
VAL_ 1687 SIGN_8_VIS_TSR_RELEVANT_DECISION 7 "other filter reason" 6 "internal sign contradiction" 5 "far irrelevant sign" 4 "sign on turn" 3 "parallel road signs" 2 "lane assignment sign" 1 "highway exit" 0 "relevant sign" ;
VAL_ 1687 SIGN_8_VIS_TSR_LOCATION 1 "above current road" 0 "unknown" ;
VAL_ 1687 SIGN_8_VIS_TSR_SUPPL_TYPE_1ST 24 "Beschreibung für den Wert '0x18'" 23 "distance for AND in" 22 "ice" 21 "end" 20 "bend right" 19 "bend left" 18 "arrow right" 17 "arrow left" 16 "tractor" 15 "truck" 14 "trailer" 13 "zone" 12 "night" 11 "fog" 10 "snow rain" 9 "snow" 8 "rain cloud" 7 "rain" 6 "school" 5 "weight" 4 "time" 3 "distance arrow" 2 "distance" 1 "generic" 0 "none" ;
VAL_ 1687 SIGN_8_VIS_TSR_STATUS 7 "reserved" 6 "reserved" 5 "updated" 4 "reserved" 3 "reserved" 2 "new" 1 "reserved" 0 "invalid" ;
VAL_ 1687 SIGN_8_VIS_TSR_SUPPL_TYPE_2ND 27 "end of all" 26 "round about" 25 "no overtaking trucks end" 24 "no overtaking trucks start" 23 "reserved (not used)" 22 "reserved (not used)" 21 "reserved (not used)" 20 "reserved (not used)" 19 "advisory speed limit start" 18 "no entrance" 17 "no overtaking end" 16 "no overtaking start" 15 "stop" 14 "low speed area end" 13 "low speed area start" 12 "town end" 11 "town start" 10 "reserved (not used" 9 "reserved (not used)" 8 "freeway end" 7 "freeway start" 6 "hightway end" 5 "highway start" 4 "reserved (not used)" 3 "reserved (not used)" 2 "speed limit end" 1 "speed limit start" 0 "unknown" ;
VAL_ 1687 SIGN_8_VIS_TSR_ELECTRONIC_SIGN 1 "electronic sign" 0 "no electronic sign" ;
VAL_ 1687 SIGN_8_VIS_TSR_TYPE 27 "end of all" 26 "round about" 25 "no overtaking trucks end" 24 "no overtaking trucks start" 23 "reserved (not used)" 22 "reserved (not used)" 21 "reserved (not used)" 20 "reserved (not used)" 19 "advisory speed limit start" 18 "no entrance" 17 "no overtaking end" 16 "no overtaking start" 15 "stop" 14 "low speed area end" 13 "low speed area start" 12 "town end" 11 "town start" 10 "reserved (not used)" 9 "reserved (not used)" 8 "freeway end" 7 "freeway start" 6 "highway end" 5 "highway start" 4 "reserved (not used)" 3 "reserved (not used)" 2 "speed limit end" 1 "speed limit start" 0 "start" ;
VAL_ 1686 SIGN_7_VIS_TSR_RELEVANT_DECISION 7 "other filter reason" 6 "internal sign contradiction" 5 "far irrelevant sign" 4 "sign on turn" 3 "parallel road signs" 2 "lane assignment sign" 1 "highway exit" 0 "relevant sign" ;
VAL_ 1686 SIGN_7_VIS_TSR_LOCATION 1 "above current road" 0 "unknown" ;
VAL_ 1686 SIGN_7_VIS_TSR_SUPPL_TYPE_1ST 24 "Beschreibung für den Wert '0x18'" 23 "distance for AND in" 22 "ice" 21 "end" 20 "bend right" 19 "bend left" 18 "arrow right" 17 "arrow left" 16 "tractor" 15 "truck" 14 "trailer" 13 "zone" 12 "night" 11 "fog" 10 "snow rain" 9 "snow" 8 "rain cloud" 7 "rain" 6 "school" 5 "weight" 4 "time" 3 "distance arrow" 2 "distance" 1 "generic" 0 "none" ;
VAL_ 1686 SIGN_7_VIS_TSR_STATUS 7 "reserved" 6 "reserved" 5 "updated" 4 "reserved" 3 "reserved" 2 "new" 1 "reserved" 0 "invalid" ;
VAL_ 1686 SIGN_7_VIS_TSR_SUPPL_TYPE_2ND 27 "end of all" 26 "round about" 25 "no overtaking trucks end" 24 "no overtaking trucks start" 23 "reserved (not used)" 22 "reserved (not used)" 21 "reserved (not used)" 20 "reserved (not used)" 19 "advisory speed limit start" 18 "no entrance" 17 "no overtaking end" 16 "no overtaking start" 15 "stop" 14 "low speed area end" 13 "low speed area start" 12 "town end" 11 "town start" 10 "reserved (not used" 9 "reserved (not used)" 8 "freeway end" 7 "freeway start" 6 "hightway end" 5 "highway start" 4 "reserved (not used)" 3 "reserved (not used)" 2 "speed limit end" 1 "speed limit start" 0 "unknown" ;
VAL_ 1686 SIGN_7_VIS_TSR_ELECTRONIC_SIGN 1 "electronic sign" 0 "no electronic sign" ;
VAL_ 1686 SIGN_7_VIS_TSR_TYPE 27 "end of all" 26 "round about" 25 "no overtaking trucks end" 24 "no overtaking trucks start" 23 "reserved (not used)" 22 "reserved (not used)" 21 "reserved (not used)" 20 "reserved (not used)" 19 "advisory speed limit start" 18 "no entrance" 17 "no overtaking end" 16 "no overtaking start" 15 "stop" 14 "low speed area end" 13 "low speed area start" 12 "town end" 11 "town start" 10 "reserved (not used)" 9 "reserved (not used)" 8 "freeway end" 7 "freeway start" 6 "highway end" 5 "highway start" 4 "reserved (not used)" 3 "reserved (not used)" 2 "speed limit end" 1 "speed limit start" 0 "start" ;
VAL_ 1685 SIGN_6_VIS_TSR_RELEVANT_DECISION 7 "other filter reason" 6 "internal sign contradiction" 5 "far irrelevant sign" 4 "sign on turn" 3 "parallel road signs" 2 "lane assignment sign" 1 "highway exit" 0 "relevant sign" ;
VAL_ 1685 SIGN_6_VIS_TSR_LOCATION 1 "above current road" 0 "unknown" ;
VAL_ 1685 SIGN_6_VIS_TSR_SUPPL_TYPE_1ST 24 "Beschreibung für den Wert '0x18'" 23 "distance for AND in" 22 "ice" 21 "end" 20 "bend right" 19 "bend left" 18 "arrow right" 17 "arrow left" 16 "tractor" 15 "truck" 14 "trailer" 13 "zone" 12 "night" 11 "fog" 10 "snow rain" 9 "snow" 8 "rain cloud" 7 "rain" 6 "school" 5 "weight" 4 "time" 3 "distance arrow" 2 "distance" 1 "generic" 0 "none" ;
VAL_ 1685 SIGN_6_VIS_TSR_STATUS 7 "reserved" 6 "reserved" 5 "updated" 4 "reserved" 3 "reserved" 2 "new" 1 "reserved" 0 "invalid" ;
VAL_ 1685 SIGN_6_VIS_TSR_SUPPL_TYPE_2ND 27 "end of all" 26 "round about" 25 "no overtaking trucks end" 24 "no overtaking trucks start" 23 "reserved (not used)" 22 "reserved (not used)" 21 "reserved (not used)" 20 "reserved (not used)" 19 "advisory speed limit start" 18 "no entrance" 17 "no overtaking end" 16 "no overtaking start" 15 "stop" 14 "low speed area end" 13 "low speed area start" 12 "town end" 11 "town start" 10 "reserved (not used" 9 "reserved (not used)" 8 "freeway end" 7 "freeway start" 6 "hightway end" 5 "highway start" 4 "reserved (not used)" 3 "reserved (not used)" 2 "speed limit end" 1 "speed limit start" 0 "unknown" ;
VAL_ 1685 SIGN_6_VIS_TSR_ELECTRONIC_SIGN 1 "electronic sign" 0 "no electronic sign" ;
VAL_ 1685 SIGN_6_VIS_TSR_TYPE 27 "end of all" 26 "round about" 25 "no overtaking trucks end" 24 "no overtaking trucks start" 23 "reserved (not used)" 22 "reserved (not used)" 21 "reserved (not used)" 20 "reserved (not used)" 19 "advisory speed limit start" 18 "no entrance" 17 "no overtaking end" 16 "no overtaking start" 15 "stop" 14 "low speed area end" 13 "low speed area start" 12 "town end" 11 "town start" 10 "reserved (not used)" 9 "reserved (not used)" 8 "freeway end" 7 "freeway start" 6 "highway end" 5 "highway start" 4 "reserved (not used)" 3 "reserved (not used)" 2 "speed limit end" 1 "speed limit start" 0 "start" ;
VAL_ 1684 SIGN_5_VIS_TSR_RELEVANT_DECISION 7 "other filter reason" 6 "internal sign contradiction" 5 "far irrelevant sign" 4 "sign on turn" 3 "parallel road signs" 2 "lane assignment sign" 1 "highway exit" 0 "relevant sign" ;
VAL_ 1684 SIGN_5_VIS_TSR_LOCATION 1 "above current road" 0 "unknown" ;
VAL_ 1684 SIGN_5_VIS_TSR_SUPPL_TYPE_1ST 24 "Beschreibung für den Wert '0x18'" 23 "distance for AND in" 22 "ice" 21 "end" 20 "bend right" 19 "bend left" 18 "arrow right" 17 "arrow left" 16 "tractor" 15 "truck" 14 "trailer" 13 "zone" 12 "night" 11 "fog" 10 "snow rain" 9 "snow" 8 "rain cloud" 7 "rain" 6 "school" 5 "weight" 4 "time" 3 "distance arrow" 2 "distance" 1 "generic" 0 "none" ;
VAL_ 1684 SIGN_5_VIS_TSR_STATUS 7 "reserved" 6 "reserved" 5 "updated" 4 "reserved" 3 "reserved" 2 "new" 1 "reserved" 0 "invalid" ;
VAL_ 1684 SIGN_5_VIS_TSR_SUPPL_TYPE_2ND 27 "end of all" 26 "round about" 25 "no overtaking trucks end" 24 "no overtaking trucks start" 23 "reserved (not used)" 22 "reserved (not used)" 21 "reserved (not used)" 20 "reserved (not used)" 19 "advisory speed limit start" 18 "no entrance" 17 "no overtaking end" 16 "no overtaking start" 15 "stop" 14 "low speed area end" 13 "low speed area start" 12 "town end" 11 "town start" 10 "reserved (not used" 9 "reserved (not used)" 8 "freeway end" 7 "freeway start" 6 "hightway end" 5 "highway start" 4 "reserved (not used)" 3 "reserved (not used)" 2 "speed limit end" 1 "speed limit start" 0 "unknown" ;
VAL_ 1684 SIGN_5_VIS_TSR_ELECTRONIC_SIGN 1 "electronic sign" 0 "no electronic sign" ;
VAL_ 1684 SIGN_5_VIS_TSR_TYPE 27 "end of all" 26 "round about" 25 "no overtaking trucks end" 24 "no overtaking trucks start" 23 "reserved (not used)" 22 "reserved (not used)" 21 "reserved (not used)" 20 "reserved (not used)" 19 "advisory speed limit start" 18 "no entrance" 17 "no overtaking end" 16 "no overtaking start" 15 "stop" 14 "low speed area end" 13 "low speed area start" 12 "town end" 11 "town start" 10 "reserved (not used)" 9 "reserved (not used)" 8 "freeway end" 7 "freeway start" 6 "highway end" 5 "highway start" 4 "reserved (not used)" 3 "reserved (not used)" 2 "speed limit end" 1 "speed limit start" 0 "start" ;
VAL_ 1683 SIGN_4_VIS_TSR_RELEVANT_DECISION 7 "other filter reason" 6 "internal sign contradiction" 5 "far irrelevant sign" 4 "sign on turn" 3 "parallel road signs" 2 "lane assignment sign" 1 "highway exit" 0 "relevant sign" ;
VAL_ 1683 SIGN_4_VIS_TSR_LOCATION 1 "above current road" 0 "unknown" ;
VAL_ 1683 SIGN_4_VIS_TSR_SUPPL_TYPE_1ST 24 "Beschreibung für den Wert '0x18'" 23 "distance for AND in" 22 "ice" 21 "end" 20 "bend right" 19 "bend left" 18 "arrow right" 17 "arrow left" 16 "tractor" 15 "truck" 14 "trailer" 13 "zone" 12 "night" 11 "fog" 10 "snow rain" 9 "snow" 8 "rain cloud" 7 "rain" 6 "school" 5 "weight" 4 "time" 3 "distance arrow" 2 "distance" 1 "generic" 0 "none" ;
VAL_ 1683 SIGN_4_VIS_TSR_STATUS 7 "reserved" 6 "reserved" 5 "updated" 4 "reserved" 3 "reserved" 2 "new" 1 "reserved" 0 "invalid" ;
VAL_ 1683 SIGN_4_VIS_TSR_SUPPL_TYPE_2ND 27 "end of all" 26 "round about" 25 "no overtaking trucks end" 24 "no overtaking trucks start" 23 "reserved (not used)" 22 "reserved (not used)" 21 "reserved (not used)" 20 "reserved (not used)" 19 "advisory speed limit start" 18 "no entrance" 17 "no overtaking end" 16 "no overtaking start" 15 "stop" 14 "low speed area end" 13 "low speed area start" 12 "town end" 11 "town start" 10 "reserved (not used" 9 "reserved (not used)" 8 "freeway end" 7 "freeway start" 6 "hightway end" 5 "highway start" 4 "reserved (not used)" 3 "reserved (not used)" 2 "speed limit end" 1 "speed limit start" 0 "unknown" ;
VAL_ 1683 SIGN_4_VIS_TSR_ELECTRONIC_SIGN 1 "electronic sign" 0 "no electronic sign" ;
VAL_ 1683 SIGN_4_VIS_TSR_TYPE 27 "end of all" 26 "round about" 25 "no overtaking trucks end" 24 "no overtaking trucks start" 23 "reserved (not used)" 22 "reserved (not used)" 21 "reserved (not used)" 20 "reserved (not used)" 19 "advisory speed limit start" 18 "no entrance" 17 "no overtaking end" 16 "no overtaking start" 15 "stop" 14 "low speed area end" 13 "low speed area start" 12 "town end" 11 "town start" 10 "reserved (not used)" 9 "reserved (not used)" 8 "freeway end" 7 "freeway start" 6 "highway end" 5 "highway start" 4 "reserved (not used)" 3 "reserved (not used)" 2 "speed limit end" 1 "speed limit start" 0 "start" ;
VAL_ 1682 SIGN_3_VIS_TSR_RELEVANT_DECISION 7 "other filter reason" 6 "internal sign contradiction" 5 "far irrelevant sign" 4 "sign on turn" 3 "parallel road signs" 2 "lane assignment sign" 1 "highway exit" 0 "relevant sign" ;
VAL_ 1682 SIGN_3_VIS_TSR_LOCATION 1 "above current road" 0 "unknown" ;
VAL_ 1682 SIGN_3_VIS_TSR_SUPPL_TYPE_1ST 24 "Beschreibung für den Wert '0x18'" 23 "distance for AND in" 22 "ice" 21 "end" 20 "bend right" 19 "bend left" 18 "arrow right" 17 "arrow left" 16 "tractor" 15 "truck" 14 "trailer" 13 "zone" 12 "night" 11 "fog" 10 "snow rain" 9 "snow" 8 "rain cloud" 7 "rain" 6 "school" 5 "weight" 4 "time" 3 "distance arrow" 2 "distance" 1 "generic" 0 "none" ;
VAL_ 1682 SIGN_3_VIS_TSR_STATUS 7 "reserved" 6 "reserved" 5 "updated" 4 "reserved" 3 "reserved" 2 "new" 1 "reserved" 0 "invalid" ;
VAL_ 1682 SIGN_3_VIS_TSR_SUPPL_TYPE_2ND 27 "end of all" 26 "round about" 25 "no overtaking trucks end" 24 "no overtaking trucks start" 23 "reserved (not used)" 22 "reserved (not used)" 21 "reserved (not used)" 20 "reserved (not used)" 19 "advisory speed limit start" 18 "no entrance" 17 "no overtaking end" 16 "no overtaking start" 15 "stop" 14 "low speed area end" 13 "low speed area start" 12 "town end" 11 "town start" 10 "reserved (not used" 9 "reserved (not used)" 8 "freeway end" 7 "freeway start" 6 "hightway end" 5 "highway start" 4 "reserved (not used)" 3 "reserved (not used)" 2 "speed limit end" 1 "speed limit start" 0 "unknown" ;
VAL_ 1682 SIGN_3_VIS_TSR_ELECTRONIC_SIGN 1 "electronic sign" 0 "no electronic sign" ;
VAL_ 1682 SIGN_3_VIS_TSR_TYPE 27 "end of all" 26 "round about" 25 "no overtaking trucks end" 24 "no overtaking trucks start" 23 "reserved (not used)" 22 "reserved (not used)" 21 "reserved (not used)" 20 "reserved (not used)" 19 "advisory speed limit start" 18 "no entrance" 17 "no overtaking end" 16 "no overtaking start" 15 "stop" 14 "low speed area end" 13 "low speed area start" 12 "town end" 11 "town start" 10 "reserved (not used)" 9 "reserved (not used)" 8 "freeway end" 7 "freeway start" 6 "highway end" 5 "highway start" 4 "reserved (not used)" 3 "reserved (not used)" 2 "speed limit end" 1 "speed limit start" 0 "start" ;
VAL_ 1681 SIGN_2_VIS_TSR_RELEVANT_DECISION 7 "other filter reason" 6 "internal sign contradiction" 5 "far irrelevant sign" 4 "sign on turn" 3 "parallel road signs" 2 "lane assignment sign" 1 "highway exit" 0 "relevant sign" ;
VAL_ 1681 SIGN_2_VIS_TSR_LOCATION 1 "above current road" 0 "unknown" ;
VAL_ 1681 SIGN_2_VIS_TSR_SUPPL_TYPE_1ST 24 "Beschreibung für den Wert '0x18'" 23 "distance for AND in" 22 "ice" 21 "end" 20 "bend right" 19 "bend left" 18 "arrow right" 17 "arrow left" 16 "tractor" 15 "truck" 14 "trailer" 13 "zone" 12 "night" 11 "fog" 10 "snow rain" 9 "snow" 8 "rain cloud" 7 "rain" 6 "school" 5 "weight" 4 "time" 3 "distance arrow" 2 "distance" 1 "generic" 0 "none" ;
VAL_ 1681 SIGN_2_VIS_TSR_STATUS 7 "reserved" 6 "reserved" 5 "updated" 4 "reserved" 3 "reserved" 2 "new" 1 "reserved" 0 "invalid" ;
VAL_ 1681 SIGN_2_VIS_TSR_SUPPL_TYPE_2ND 27 "end of all" 26 "round about" 25 "no overtaking trucks end" 24 "no overtaking trucks start" 23 "reserved (not used)" 22 "reserved (not used)" 21 "reserved (not used)" 20 "reserved (not used)" 19 "advisory speed limit start" 18 "no entrance" 17 "no overtaking end" 16 "no overtaking start" 15 "stop" 14 "low speed area end" 13 "low speed area start" 12 "town end" 11 "town start" 10 "reserved (not used" 9 "reserved (not used)" 8 "freeway end" 7 "freeway start" 6 "hightway end" 5 "highway start" 4 "reserved (not used)" 3 "reserved (not used)" 2 "speed limit end" 1 "speed limit start" 0 "unknown" ;
VAL_ 1681 SIGN_2_VIS_TSR_ELECTRONIC_SIGN 1 "electronic sign" 0 "no electronic sign" ;
VAL_ 1681 SIGN_2_VIS_TSR_TYPE 27 "end of all" 26 "round about" 25 "no overtaking trucks end" 24 "no overtaking trucks start" 23 "reserved (not used)" 22 "reserved (not used)" 21 "reserved (not used)" 20 "reserved (not used)" 19 "advisory speed limit start" 18 "no entrance" 17 "no overtaking end" 16 "no overtaking start" 15 "stop" 14 "low speed area end" 13 "low speed area start" 12 "town end" 11 "town start" 10 "reserved (not used)" 9 "reserved (not used)" 8 "freeway end" 7 "freeway start" 6 "highway end" 5 "highway start" 4 "reserved (not used)" 3 "reserved (not used)" 2 "speed limit end" 1 "speed limit start" 0 "start" ;
VAL_ 1680 SIGN_1_VIS_TSR_RELEVANT_DECISION 7 "other filter reason" 6 "internal sign contradiction" 5 "far irrelevant sign" 4 "sign on turn" 3 "parallel road signs" 2 "lane assignment sign" 1 "highway exit" 0 "relevant sign" ;
VAL_ 1680 SIGN_1_VIS_TSR_LOCATION 1 "above current road" 0 "unknown" ;
VAL_ 1680 SIGN_1_VIS_TSR_SUPPL_TYPE_1ST 24 "Beschreibung für den Wert '0x18'" 23 "distance for AND in" 22 "ice" 21 "end" 20 "bend right" 19 "bend left" 18 "arrow right" 17 "arrow left" 16 "tractor" 15 "truck" 14 "trailer" 13 "zone" 12 "night" 11 "fog" 10 "snow rain" 9 "snow" 8 "rain cloud" 7 "rain" 6 "school" 5 "weight" 4 "time" 3 "distance arrow" 2 "distance" 1 "generic" 0 "none" ;
VAL_ 1680 SIGN_1_VIS_TSR_STATUS 7 "reserved" 6 "reserved" 5 "updated" 4 "reserved" 3 "reserved" 2 "new" 1 "reserved" 0 "invalid" ;
VAL_ 1680 SIGN_1_VIS_TSR_SUPPL_TYPE_2ND 27 "end of all" 26 "round about" 25 "no overtaking trucks end" 24 "no overtaking trucks start" 23 "reserved (not used)" 22 "reserved (not used)" 21 "reserved (not used)" 20 "reserved (not used)" 19 "advisory speed limit start" 18 "no entrance" 17 "no overtaking end" 16 "no overtaking start" 15 "stop" 14 "low speed area end" 13 "low speed area start" 12 "town end" 11 "town start" 10 "reserved (not used" 9 "reserved (not used)" 8 "freeway end" 7 "freeway start" 6 "hightway end" 5 "highway start" 4 "reserved (not used)" 3 "reserved (not used)" 2 "speed limit end" 1 "speed limit start" 0 "unknown" ;
VAL_ 1680 SIGN_1_VIS_TSR_ELECTRONIC_SIGN 1 "electronic sign" 0 "no electronic sign" ;
VAL_ 1680 SIGN_1_VIS_TSR_TYPE 27 "end of all" 26 "round about" 25 "no overtaking trucks end" 24 "no overtaking trucks start" 23 "reserved (not used)" 22 "reserved (not used)" 21 "reserved (not used)" 20 "reserved (not used)" 19 "advisory speed limit start" 18 "no entrance" 17 "no overtaking end" 16 "no overtaking start" 15 "stop" 14 "low speed area end" 13 "low speed area start" 12 "town end" 11 "town start" 10 "reserved (not used)" 9 "reserved (not used)" 8 "freeway end" 7 "freeway start" 6 "highway end" 5 "highway start" 4 "reserved (not used)" 3 "reserved (not used)" 2 "speed limit end" 1 "speed limit start" 0 "start" ;
VAL_ 1649 VIS_FCW_SENS_LEVEL 2 "high" 1 "medium" 0 "low" ;
VAL_ 1649 VIS_FCW_NEAR_RNG_OBS_VIO 3 "not applicable" 2 "unused" 1 "violation" 0 "no violation" ;
VAL_ 1171 PAC_Object_class 10 "unidentified vehicle" 9 "bicycle" 8 "general on-road object" 7 "animal" 6 "tree" 5 "pole" 4 "pedestrian" 3 "truck" 2 "motorcycle" 1 "car" 0 "undetermined" ;
VAL_ 1155 P9C_Object_class 10 "unidentified vehicle" 9 "bicycle" 8 "general on-road object" 7 "animal" 6 "tree" 5 "pole" 4 "pedestrian" 3 "truck" 2 "motorcycle" 1 "car" 0 "undetermined" ;
VAL_ 1139 P8C_Object_class 10 "unidentified vehicle" 9 "bicycle" 8 "general on-road object" 7 "animal" 6 "tree" 5 "pole" 4 "pedestrian" 3 "truck" 2 "motorcycle" 1 "car" 0 "undetermined" ;
VAL_ 1123 P7C_Object_class 10 "unidentified vehicle" 9 "bicycle" 8 "general on-road object" 7 "animal" 6 "tree" 5 "pole" 4 "pedestrian" 3 "truck" 2 "motorcycle" 1 "car" 0 "undetermined" ;
VAL_ 1107 P6C_Object_class 10 "unidentified vehicle" 9 "bicycle" 8 "general on-road object" 7 "animal" 6 "tree" 5 "pole" 4 "pedestrian" 3 "truck" 2 "motorcycle" 1 "car" 0 "undetermined" ;
VAL_ 1091 P5C_Object_class 10 "unidentified vehicle" 9 "bicycle" 8 "general on-road object" 7 "animal" 6 "tree" 5 "pole" 4 "pedestrian" 3 "truck" 2 "motorcycle" 1 "car" 0 "undetermined" ;
VAL_ 1075 P4C_Object_class 10 "unidentified vehicle" 9 "bicycle" 8 "general on-road object" 7 "animal" 6 "tree" 5 "pole" 4 "pedestrian" 3 "truck" 2 "motorcycle" 1 "car" 0 "undetermined" ;
VAL_ 1059 P3C_Object_class 10 "unidentified vehicle" 9 "bicycle" 8 "general on-road object" 7 "animal" 6 "tree" 5 "pole" 4 "pedestrian" 3 "truck" 2 "motorcycle" 1 "car" 0 "undetermined" ;
VAL_ 1043 P2C_Object_class 10 "unidentified vehicle" 9 "bicycle" 8 "general on-road object" 7 "animal" 6 "tree" 5 "pole" 4 "pedestrian" 3 "truck" 2 "motorcycle" 1 "car" 0 "undetermined" ;
VAL_ 1170 PAB_Status 6 "coasted" 5 "updated" 4 "new updated" 3 "new coasted" 2 "new" 1 "merged" 0 "invalid" ;
VAL_ 1154 P9B_Status 6 "coasted" 5 "updated" 4 "new updated" 3 "new coasted" 2 "new" 1 "merged" 0 "invalid" ;
VAL_ 1138 P8B_Status 6 "coasted" 5 "updated" 4 "new updated" 3 "new coasted" 2 "new" 1 "merged" 0 "invalid" ;
VAL_ 1122 P7B_Status 6 "coasted" 5 "updated" 4 "new updated" 3 "new coasted" 2 "new" 1 "merged" 0 "invalid" ;
VAL_ 1106 P6B_Status 6 "coasted" 5 "updated" 4 "new updated" 3 "new coasted" 2 "new" 1 "merged" 0 "invalid" ;
VAL_ 1090 P5B_Status 6 "coasted" 5 "updated" 4 "new updated" 3 "new coasted" 2 "new" 1 "merged" 0 "invalid" ;
VAL_ 1074 P4B_Status 6 "coasted" 5 "updated" 4 "new updated" 3 "new coasted" 2 "new" 1 "merged" 0 "invalid" ;
VAL_ 1058 P3B_Status 6 "coasted" 5 "updated" 4 "new updated" 3 "new coasted" 2 "new" 1 "merged" 0 "invalid" ;
VAL_ 1042 P2B_Status 6 "coasted" 5 "updated" 4 "new updated" 3 "new coasted" 2 "new" 1 "merged" 0 "invalid" ;
VAL_ 1026 P1B_Status 6 "coasted" 5 "updated" 4 "new updated" 3 "new coasted" 2 "new" 1 "merged" 0 "invalid" ;
VAL_ 1958 LKA_Feature_diag 1 "Pass" 0 "Fault" ;
VAL_ 1956 ME_vision_fault 1 "Pass" 0 "Fault" ;
VAL_ 1956 ldp_LKAMode 8 "LKA_MODE_TRANSITION" 7 "LKA_MODE_STAGE2_RIGHT" 6 "LKA_MODE_STAGE2_LEFT" 5 "LKA_MODE_STAGE1_RIGHT" 4 "LKA_MODE_STAGE1_LEFT" 3 "LKA_MODE_ENABLED" 2 "LKA_MODE_STANDBY" 1 "LKA_MODE_OFF" 0 "LKA_MODE_FAIL" ;
